VERSION "HNNBNNNYNNNNNNNNNNNNNNNNNNNNNNNNNNNNNNNNNN/4/%%%/4/'%**4NNN///"

NS_ :

BS_:

BU_: AWC BAP_Tester BMC_MLBevo BMS_MV BMS_NV CBC DCDC_800V_PAG DCDC_HV DCDC_HV_02 DCDC_IHEV FCU_MLBevo_FCEV Gateway Gateway_PAG Ladegeraet_2 Ladegeraet_Konzern LE1 LE2 LE_MLBevo Sub_Gateway TME

BO_ 2550034644 OBDC_SSN_CMC_04_Resp: 8 BMC_MLBevo
 SG_ OBDC_SSN_CMC_04_Resp_Data : 0|64@1+ (1.0,0.0) [0.0|18446744073709551615] ""  Gateway,Gateway_PAG

BO_ 2549903573 OBDC_SSN_CMC_05_Req: 8 Gateway
 SG_ OBDC_SSN_CMC_05_Req_Data : 0|64@1+ (1.0,0.0) [0.0|18446744073709551615] ""  BMC_MLBevo

BO_ 2550034645 OBDC_SSN_CMC_05_Resp: 8 BMC_MLBevo
 SG_ OBDC_SSN_CMC_05_Resp_Data : 0|64@1+ (1.0,0.0) [0.0|18446744073709551615] ""  Gateway,Gateway_PAG

BO_ 2549903574 OBDC_SSN_CMC_06_Req: 8 Gateway
 SG_ OBDC_SSN_CMC_06_Req_Data : 0|64@1+ (1.0,0.0) [0.0|18446744073709551615] ""  BMC_MLBevo

BO_ 2550034646 OBDC_SSN_CMC_06_Resp: 8 BMC_MLBevo
 SG_ OBDC_SSN_CMC_06_Resp_Data : 0|64@1+ (1.0,0.0) [0.0|18446744073709551615] ""  Gateway,Gateway_PAG

BO_ 2549903575 OBDC_SSN_CMC_07_Req: 8 Gateway
 SG_ OBDC_SSN_CMC_07_Req_Data : 0|64@1+ (1.0,0.0) [0.0|18446744073709551615] ""  BMC_MLBevo

BO_ 2550034647 OBDC_SSN_CMC_07_Resp: 8 BMC_MLBevo
 SG_ OBDC_SSN_CMC_07_Resp_Data : 0|64@1+ (1.0,0.0) [0.0|18446744073709551615] ""  Gateway,Gateway_PAG

BO_ 2549903576 OBDC_SSN_CMC_08_Req: 8 Gateway
 SG_ OBDC_SSN_CMC_08_Req_Data : 0|64@1+ (1.0,0.0) [0.0|18446744073709551615] ""  BMC_MLBevo

BO_ 2550034648 OBDC_SSN_CMC_08_Resp: 8 BMC_MLBevo
 SG_ OBDC_SSN_CMC_08_Resp_Data : 0|64@1+ (1.0,0.0) [0.0|18446744073709551615] ""  Gateway,Gateway_PAG

BO_ 2549903577 OBDC_SSN_CMC_09_Req: 8 Gateway
 SG_ OBDC_SSN_CMC_09_Req_Data : 0|64@1+ (1.0,0.0) [0.0|18446744073709551615] ""  BMC_MLBevo

BO_ 2550034649 OBDC_SSN_CMC_09_Resp: 8 BMC_MLBevo
 SG_ OBDC_SSN_CMC_09_Resp_Data : 0|64@1+ (1.0,0.0) [0.0|18446744073709551615] ""  Gateway,Gateway_PAG

BO_ 2549903578 OBDC_SSN_CMC_10_Req: 8 Gateway
 SG_ OBDC_SSN_CMC_10_Req_Data : 0|64@1+ (1.0,0.0) [0.0|18446744073709551615] ""  BMC_MLBevo

BO_ 2550034650 OBDC_SSN_CMC_10_Resp: 8 BMC_MLBevo
 SG_ OBDC_SSN_CMC_10_Resp_Data : 0|64@1+ (1.0,0.0) [0.0|18446744073709551615] ""  Gateway,Gateway_PAG

BO_ 2549903579 OBDC_SSN_CMC_11_Req: 8 Gateway
 SG_ OBDC_SSN_CMC_11_Req_Data : 0|64@1+ (1.0,0.0) [0.0|18446744073709551615] ""  BMC_MLBevo

BO_ 2550034651 OBDC_SSN_CMC_11_Resp: 8 BMC_MLBevo
 SG_ OBDC_SSN_CMC_11_Resp_Data : 0|64@1+ (1.0,0.0) [0.0|18446744073709551615] ""  Gateway,Gateway_PAG

BO_ 2549903580 OBDC_SSN_CMC_12_Req: 8 Gateway
 SG_ OBDC_SSN_CMC_12_Req_Data : 0|64@1+ (1.0,0.0) [0.0|18446744073709551615] ""  BMC_MLBevo

BO_ 2550034652 OBDC_SSN_CMC_12_Resp: 8 BMC_MLBevo
 SG_ OBDC_SSN_CMC_12_Resp_Data : 0|64@1+ (1.0,0.0) [0.0|18446744073709551615] ""  Gateway,Gateway_PAG

BO_ 2549903601 OBDC_SSN_CMC_13_Req: 8 Gateway
 SG_ OBDC_SSN_CMC_13_Req_Data : 0|64@1+ (1.0,0.0) [0.0|18446744073709551615] ""  BMC_MLBevo

BO_ 2550034673 OBDC_SSN_CMC_13_Resp: 8 BMC_MLBevo
 SG_ OBDC_SSN_CMC_13_Resp_Data : 0|64@1+ (1.0,0.0) [0.0|18446744073709551615] ""  Gateway,Gateway_PAG

BO_ 2549903602 OBDC_SSN_CMC_14_Req: 8 Gateway
 SG_ OBDC_SSN_CMC_14_Req_Data : 0|64@1+ (1.0,0.0) [0.0|18446744073709551615] ""  BMC_MLBevo

BO_ 2550034674 OBDC_SSN_CMC_14_Resp: 8 BMC_MLBevo
 SG_ OBDC_SSN_CMC_14_Resp_Data : 0|64@1+ (1.0,0.0) [0.0|18446744073709551615] ""  Gateway,Gateway_PAG

BO_ 2549903603 OBDC_SSN_CMC_15_Req: 8 Gateway
 SG_ OBDC_SSN_CMC_15_Req_Data : 0|64@1+ (1.0,0.0) [0.0|18446744073709551615] ""  BMC_MLBevo

BO_ 2550034675 OBDC_SSN_CMC_15_Resp: 8 BMC_MLBevo
 SG_ OBDC_SSN_CMC_15_Resp_Data : 0|64@1+ (1.0,0.0) [0.0|18446744073709551615] ""  Gateway,Gateway_PAG

BO_ 2549875380 OBDC_TelemetrieSG_Req: 8 Gateway
 SG_ OBDC_TelemetrieSG_Req_Data : 0|64@1+ (1.0,0.0) [0.0|18446744073709551615] ""  Sub_Gateway

BO_ 2550006452 OBDC_TelemetrieSG_Resp: 8 Sub_Gateway
 SG_ OBDC_TelemetrieSG_Resp_Data : 0|64@1+ (1.0,0.0) [0.0|18446744073709551615] ""  Gateway

BO_ 2549875266 OBDC_TME_Req: 8 Gateway
 SG_ OBDC_TME_Req_Data : 0|64@1+ (1.0,0.0) [0.0|18446744073709551615] ""  TME

BO_ 2550006338 OBDC_TME_Resp: 8 TME
 SG_ OBDC_TME_Resp_Data : 0|64@1+ (1.0,0.0) [0.0|18446744073709551615] ""  Gateway,Gateway_PAG

BO_ 2589283656 ORU_01: 8 Gateway
 SG_ ORU_Warnung : 58|2@1+ (1.0,0.0) [0.0|3] ""  Vector__XXX
 SG_ ORU_Status : 61|3@1+ (1.0,0.0) [0.0|7] ""  BMC_MLBevo,CBC,DCDC_800V_PAG,DCDC_HV,DCDC_HV_02,Ladegeraet_2,Ladegeraet_Konzern,TME

BO_ 872 Parkhilfe2_01: 8 Gateway
 SG_ PH2_Visualisierung : 0|3@1+ (1.0,0.0) [0.0|7] ""  Vector__XXX
 SG_ PDC2_Tonausgabe_Front : 4|4@1+ (1.0,0.0) [0.0|15] ""  Vector__XXX
 SG_ PDC2_Tonausgabe_Heck : 8|4@1+ (1.0,0.0) [0.0|15] ""  Vector__XXX
 SG_ PH2_nachtr_Stopp_An : 12|1@1+ (1.0,0.0) [0.0|1] ""  Vector__XXX
 SG_ PH2_Abschaltursache : 13|3@1+ (1.0,0.0) [0.0|7] ""  Vector__XXX
 SG_ PH2_Opt_Anzeige_V_ein : 16|1@1+ (1.0,0.0) [0.0|1] ""  Vector__XXX
 SG_ PH2_Opt_Anzeige_H_ein : 17|1@1+ (1.0,0.0) [0.0|1] ""  Vector__XXX
 SG_ PH2_Opt_Anz_V_Hindernis : 18|1@1+ (1.0,0.0) [0.0|1] ""  Vector__XXX
 SG_ PH2_Opt_Anz_H_Hindernis : 19|1@1+ (1.0,0.0) [0.0|1] ""  Vector__XXX
 SG_ PH2_Tongeber_V_aktiv : 20|1@1+ (1.0,0.0) [0.0|1] ""  Vector__XXX
 SG_ PH2_Tongeber_H_aktiv : 21|1@1+ (1.0,0.0) [0.0|1] ""  Vector__XXX
 SG_ PH2_Tongeber_mute : 22|1@1+ (1.0,0.0) [0.0|1] ""  Vector__XXX
 SG_ PH2_Anf_Audioabsenkung : 23|1@1+ (1.0,0.0) [0.0|1] ""  Vector__XXX
 SG_ PH2_Tongeber_H_verfuegbar : 24|1@1+ (1.0,0.0) [0.0|1] ""  Vector__XXX
 SG_ PH2_Taster : 28|2@1+ (1.0,0.0) [0.0|3] ""  Vector__XXX
 SG_ PH2_Anf_Verdeck : 30|2@1+ (1.0,0.0) [0.0|3] ""  Vector__XXX
 SG_ PH2_Frequenz_hinten : 32|4@1+ (1,0) [0|15] ""  Vector__XXX
 SG_ PH2_Lautstaerke_hinten : 36|4@1+ (1,0) [0|15] ""  Vector__XXX
 SG_ PH2_Frequenz_vorn : 40|4@1+ (1,0) [0|15] ""  Vector__XXX
 SG_ PH2_Lautstaerke_vorn : 44|4@1+ (1,0) [0|15] ""  Vector__XXX
 SG_ PH2_StartStopp_Info : 49|2@1+ (1.0,0.0) [0.0|3] ""  Vector__XXX
 SG_ PH2_Stoermeldung : 52|4@1+ (1.0,0.0) [0.0|15] ""  Vector__XXX
 SG_ PH2_defekt : 56|1@1+ (1.0,0.0) [0.0|1] ""  Vector__XXX
 SG_ PH2_gestoert : 57|1@1+ (1.0,0.0) [0.0|1] ""  Vector__XXX
 SG_ PH2_Systemzustand : 58|3@1+ (1.0,0.0) [0.0|7] ""  Vector__XXX
 SG_ PH2_Display_Kundenwunsch : 61|2@1+ (1.0,0.0) [0.0|3] ""  Vector__XXX

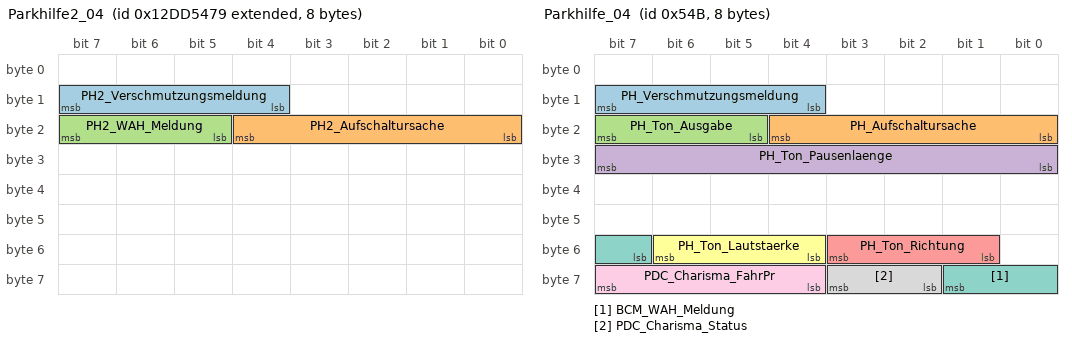
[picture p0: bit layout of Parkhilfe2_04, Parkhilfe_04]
BO_ 2463978617 Parkhilfe2_04: 8 Gateway
 SG_ PH2_Verschmutzungsmeldung : 12|4@1+ (1.0,0.0) [0.0|15] ""  Vector__XXX
 SG_ PH2_Aufschaltursache : 16|5@1+ (1.0,0.0) [0.0|31] ""  Vector__XXX
 SG_ PH2_WAH_Meldung : 21|3@1+ (1.0,0.0) [0.0|7] ""  Vector__XXX

BO_ 1175 Parkhilfe_01: 8 Gateway
 SG_ PH_Visualisierung : 0|3@1+ (1.0,0.0) [0.0|7] ""  Vector__XXX
 SG_ PDC_Tonausgabe_Front : 4|4@1+ (1.0,0.0) [0.0|15] ""  Vector__XXX
 SG_ PDC_Tonausgabe_Heck : 8|4@1+ (1.0,0.0) [0.0|15] ""  Vector__XXX
 SG_ PH_nachtr_Stopp_Anf : 12|1@1+ (1.0,0.0) [0.0|1] ""  Vector__XXX
 SG_ PH_Abschaltursache : 13|3@1+ (1.0,0.0) [0.0|7] ""  Vector__XXX
 SG_ PH_Opt_Anzeige_V_ein : 16|1@1+ (1.0,0.0) [0.0|1] ""  Vector__XXX
 SG_ PH_Opt_Anzeige_H_ein : 17|1@1+ (1.0,0.0) [0.0|1] ""  Vector__XXX
 SG_ PH_Opt_Anz_V_Hindernis : 18|1@1+ (1.0,0.0) [0.0|1] ""  Vector__XXX
 SG_ PH_Opt_Anz_H_Hindernis : 19|1@1+ (1.0,0.0) [0.0|1] ""  Vector__XXX
 SG_ PH_Tongeber_V_aktiv : 20|1@1+ (1.0,0.0) [0.0|1] ""  Vector__XXX
 SG_ PH_Tongeber_H_aktiv : 21|1@1+ (1.0,0.0) [0.0|1] ""  Vector__XXX
 SG_ PH_Tongeber_mute : 22|1@1+ (1.0,0.0) [0.0|1] ""  Vector__XXX
 SG_ PH_Anf_Audioabsenkung : 23|1@1+ (1.0,0.0) [0.0|1] ""  Vector__XXX
 SG_ PH_Tongeber_H_verfuegbar : 24|1@1+ (1.0,0.0) [0.0|1] ""  Vector__XXX
 SG_ PLA_Anf_Aufschaltung_RVC : 25|1@1+ (1.0,0.0) [0.0|1] ""  Vector__XXX
 SG_ PH_Taster : 28|2@1+ (1.0,0.0) [0.0|3] ""  Vector__XXX
 SG_ PH_Anf_Verdeck : 30|2@1+ (1.0,0.0) [0.0|3] ""  Vector__XXX
 SG_ PH_Frequenz_hinten : 32|4@1+ (1,0) [0|15] ""  Vector__XXX
 SG_ PH_Lautstaerke_hinten : 36|4@1+ (1,0) [0|15] ""  Vector__XXX
 SG_ PH_Frequenz_vorn : 40|4@1+ (1,0) [0|15] ""  Vector__XXX
 SG_ PH_Lautstaerke_vorn : 44|4@1+ (1,0) [0|15] ""  Vector__XXX
 SG_ PH_StartStopp_Info : 49|2@1+ (1.0,0.0) [0.0|3] ""  Vector__XXX
 SG_ PH_Stoermeldung : 52|4@1+ (1.0,0.0) [0.0|15] ""  Vector__XXX
 SG_ PH_defekt : 56|1@1+ (1.0,0.0) [0.0|1] ""  Vector__XXX
 SG_ PH_gestoert : 57|1@1+ (1.0,0.0) [0.0|1] ""  Vector__XXX
 SG_ PH_Systemzustand : 58|3@1+ (1.0,0.0) [0.0|7] ""  Vector__XXX
 SG_ PH_Display_Kundenwunsch : 61|2@1+ (1.0,0.0) [0.0|3] ""  Vector__XXX

BO_ 1355 Parkhilfe_04: 8 Gateway
 SG_ PH_Verschmutzungsmeldung : 12|4@1+ (1.0,0.0) [0.0|15] ""  Vector__XXX
 SG_ PH_Aufschaltursache : 16|5@1+ (1.0,0.0) [0.0|31] ""  Vector__XXX
 SG_ PH_Ton_Ausgabe : 21|3@1+ (1.0,0.0) [0.0|7] ""  Vector__XXX
 SG_ PH_Ton_Pausenlaenge : 24|8@1+ (1.0,0.0) [0.0|255] ""  Vector__XXX
 SG_ PH_Ton_Richtung : 49|3@1+ (1.0,0.0) [0.0|7] ""  Vector__XXX
 SG_ PH_Ton_Lautstaerke : 52|3@1+ (1.0,0.0) [0.0|7] ""  Vector__XXX
 SG_ BCM_WAH_Meldung : 55|3@1+ (1.0,0.0) [0.0|7] ""  Vector__XXX
 SG_ PDC_Charisma_Status : 58|2@1+ (1.0,0.0) [0.0|3] ""  Vector__XXX
 SG_ PDC_Charisma_FahrPr : 60|4@1+ (1.0,0.0) [0.0|15] ""  Vector__XXX

BO_ 617 PIF_01: 8 Gateway
 SG_ PIF_Toggle : 0|1@1+ (1.0,0.0) [0.0|1] ""  TME
 SG_ PIF_ST_Status : 1|2@1+ (1.0,0.0) [0.0|3] ""  TME
 SG_ PIF_MT_Status : 3|2@1+ (1.0,0.0) [0.0|3] ""  TME
 SG_ PIF_LT_Status : 5|2@1+ (1.0,0.0) [0.0|3] ""  TME
 SG_ PIF_Identifier : 7|3@1+ (1.0,0.0) [0.0|7] ""  TME
 SG_ PIF_ST_Bin_0 : 10|2@1+ (1.0,0.0) [0.0|3] ""  TME
 SG_ PIF_ST_Bin_1 : 12|2@1+ (1.0,0.0) [0.0|3] ""  TME
 SG_ PIF_ST_Bin_2 : 14|2@1+ (1.0,0.0) [0.0|3] ""  TME
 SG_ PIF_ST_Bin_3 : 16|2@1+ (1.0,0.0) [0.0|3] ""  TME
 SG_ PIF_ST_Bin_4 : 18|2@1+ (1.0,0.0) [0.0|3] ""  TME
 SG_ PIF_ST_Bin_5 : 20|2@1+ (1.0,0.0) [0.0|3] ""  TME
 SG_ PIF_ST_Bin_6 : 22|2@1+ (1.0,0.0) [0.0|3] ""  TME
 SG_ PIF_ST_Bin_7 : 24|2@1+ (1.0,0.0) [0.0|3] ""  TME
 SG_ PIF_ST_Bin_8 : 26|2@1+ (1.0,0.0) [0.0|3] ""  TME
 SG_ PIF_MT_Bin_0 : 28|2@1+ (1.0,0.0) [0.0|3] ""  TME
 SG_ PIF_MT_Bin_1 : 30|2@1+ (1.0,0.0) [0.0|3] ""  TME
 SG_ PIF_MT_Bin_2 : 32|2@1+ (1.0,0.0) [0.0|3] ""  TME
 SG_ PIF_MT_Bin_3 : 34|2@1+ (1.0,0.0) [0.0|3] ""  TME
 SG_ PIF_MT_Bin_4 : 36|2@1+ (1.0,0.0) [0.0|3] ""  TME
 SG_ PIF_MT_Bin_5 : 38|2@1+ (1.0,0.0) [0.0|3] ""  TME
 SG_ PIF_MT_Bin_6 : 40|2@1+ (1.0,0.0) [0.0|3] ""  TME
 SG_ PIF_MT_Bin_7 : 42|2@1+ (1.0,0.0) [0.0|3] ""  TME
 SG_ PIF_MT_Bin_8 : 44|2@1+ (1.0,0.0) [0.0|3] ""  TME
 SG_ PIF_LT_Bin_0 : 46|2@1+ (1.0,0.0) [0.0|3] ""  TME
 SG_ PIF_LT_Bin_1 : 48|2@1+ (1.0,0.0) [0.0|3] ""  TME
 SG_ PIF_LT_Bin_2 : 50|2@1+ (1.0,0.0) [0.0|3] ""  TME
 SG_ PIF_LT_Bin_3 : 52|2@1+ (1.0,0.0) [0.0|3] ""  TME
 SG_ PIF_LT_Bin_4 : 54|2@1+ (1.0,0.0) [0.0|3] ""  TME
 SG_ PIF_LT_Bin_5 : 56|2@1+ (1.0,0.0) [0.0|3] ""  TME
 SG_ PIF_LT_Bin_6 : 58|2@1+ (1.0,0.0) [0.0|3] ""  TME
 SG_ PIF_LT_Bin_7 : 60|2@1+ (1.0,0.0) [0.0|3] ""  TME
 SG_ PIF_LT_Bin_8 : 62|2@1+ (1.0,0.0) [0.0|3] ""  TME

BO_ 2549876804 PnC_Ladegeraet_Req: 8 Ladegeraet_Konzern
 SG_ PnC_Ladegeraet_Req_Data : 0|64@1+ (1,0) [0|18446744073709551615] "Unit_None"  Gateway,Gateway_PAG

BO_ 2550007876 PnC_Ladegeraet_Resp: 8 Gateway
 SG_ PnC_Ladegeraet_Resp_Data : 0|64@1+ (1,0) [0|18446744073709551615] "Unit_None"  Ladegeraet_Konzern

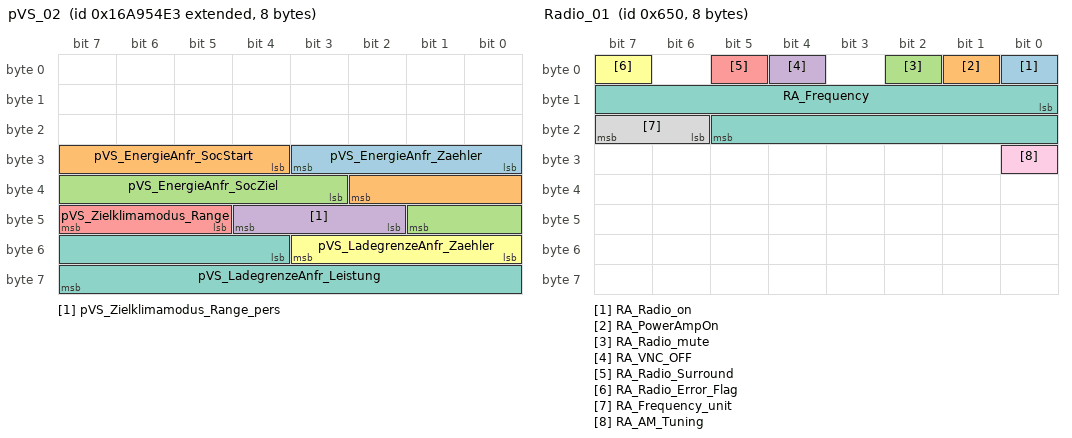
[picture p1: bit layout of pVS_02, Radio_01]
BO_ 2527679715 pVS_02: 8 Gateway_PAG
 SG_ pVS_EnergieAnfr_Zaehler : 24|4@1+ (1,0) [0|13] "Unit_None"  BMC_MLBevo
 SG_ pVS_EnergieAnfr_SocStart : 28|7@1+ (1,0) [0|100] "Unit_PerCent"  BMC_MLBevo
 SG_ pVS_EnergieAnfr_SocZiel : 35|7@1+ (1,0) [0|100] "Unit_PerCent"  BMC_MLBevo
 SG_ pVS_Zielklimamodus_Range_pers : 42|3@1+ (1.0,0.0) [0.0|7] ""  Vector__XXX
 SG_ pVS_Zielklimamodus_Range : 45|3@1+ (1.0,0.0) [0.0|7] ""  Vector__XXX
 SG_ pVS_LadegrenzeAnfr_Zaehler : 48|4@1+ (1,0) [0|13] "Unit_None"  BMC_MLBevo
 SG_ pVS_LadegrenzeAnfr_Leistung : 52|12@1+ (200,0) [0|818600] "Unit_Watt"  BMC_MLBevo

BO_ 1616 Radio_01: 8 Gateway
 SG_ RA_Radio_on : 0|1@1+ (1,0) [0|1] ""  DCDC_800V_PAG,DCDC_IHEV
 SG_ RA_PowerAmpOn : 1|1@1+ (1,0) [0|1] ""  Vector__XXX
 SG_ RA_Radio_mute : 2|1@1+ (1,0) [0|1] ""  Vector__XXX
 SG_ RA_VNC_OFF : 4|1@1+ (1,0) [0|1] ""  Vector__XXX
 SG_ RA_Radio_Surround : 5|1@1+ (1,0) [0|1] ""  Vector__XXX
 SG_ RA_Radio_Error_Flag : 7|1@1+ (1.0,0.0) [0.0|1] ""  Vector__XXX
 SG_ RA_Frequency : 8|14@1+ (1,0) [0|16383] "Unit_None"  DCDC_800V_PAG,DCDC_IHEV
 SG_ RA_Frequency_unit : 22|2@1+ (1.0,0.0) [0.0|3] ""  DCDC_800V_PAG,DCDC_IHEV
 SG_ RA_AM_Tuning : 24|1@1+ (1.0,0.0) [0.0|1] ""  DCDC_800V_PAG,DCDC_IHEV

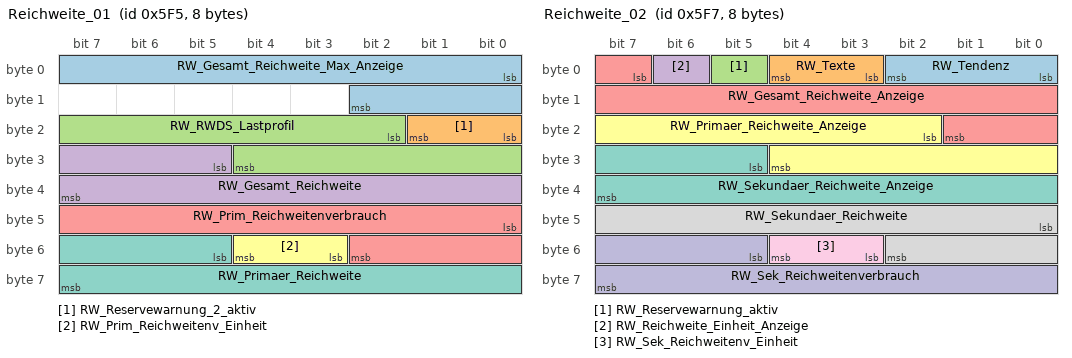
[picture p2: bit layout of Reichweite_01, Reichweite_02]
BO_ 1525 Reichweite_01: 8 Gateway
 SG_ RW_Gesamt_Reichweite_Max_Anzeige : 0|11@1+ (1,0) [0|2044] "Unit_None"  Sub_Gateway
 SG_ RW_Reservewarnung_2_aktiv : 16|2@1+ (1.0,0.0) [0.0|3] ""  Sub_Gateway,TME
 SG_ RW_RWDS_Lastprofil : 18|11@1+ (1,0) [0|2045] "Unit_Amper"  BMC_MLBevo,Sub_Gateway
 SG_ RW_Gesamt_Reichweite : 29|11@1+ (1,0) [0|2044] "Unit_KiloMeter"  Ladegeraet_Konzern,Sub_Gateway
 SG_ RW_Prim_Reichweitenverbrauch : 40|11@1+ (0.1,0) [0.0|204.4] "Unit_None"  Ladegeraet_Konzern,Sub_Gateway
 SG_ RW_Prim_Reichweitenv_Einheit : 51|2@1+ (1.0,0.0) [0.0|3] ""  Sub_Gateway
 SG_ RW_Primaer_Reichweite : 53|11@1+ (1,0) [0|2044] "Unit_KiloMeter"  Ladegeraet_Konzern,Sub_Gateway

BO_ 1527 Reichweite_02: 8 Gateway
 SG_ RW_Tendenz : 0|3@1+ (1.0,0.0) [0.0|7] ""  Sub_Gateway
 SG_ RW_Texte : 3|2@1+ (1.0,0.0) [0.0|3] ""  Sub_Gateway
 SG_ RW_Reservewarnung_aktiv : 5|1@1+ (1.0,0.0) [0.0|1] ""  Sub_Gateway,TME
 SG_ RW_Reichweite_Einheit_Anzeige : 6|1@1+ (1.0,0.0) [0.0|1] ""  Sub_Gateway
 SG_ RW_Gesamt_Reichweite_Anzeige : 7|11@1+ (1,0) [0|2044] "Unit_None"  Sub_Gateway
 SG_ RW_Primaer_Reichweite_Anzeige : 18|11@1+ (1,0) [0|2044] "Unit_None"  Ladegeraet_Konzern,Sub_Gateway
 SG_ RW_Sekundaer_Reichweite_Anzeige : 29|11@1+ (1,0) [0|2044] "Unit_None"  Sub_Gateway
 SG_ RW_Sekundaer_Reichweite : 40|11@1+ (1,0) [0|2044] "Unit_KiloMeter"  Ladegeraet_Konzern,Sub_Gateway
 SG_ RW_Sek_Reichweitenv_Einheit : 51|2@1+ (1.0,0.0) [0.0|3] ""  Sub_Gateway
 SG_ RW_Sek_Reichweitenverbrauch : 53|11@1+ (0.1,0) [0.0|204.4] "Unit_None"  Sub_Gateway

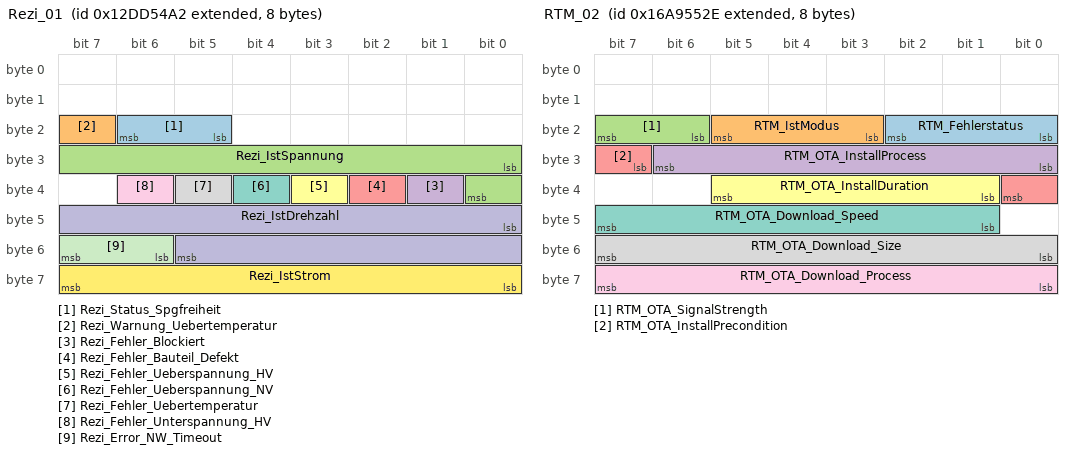
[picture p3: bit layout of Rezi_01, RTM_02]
BO_ 2463978658 Rezi_01: 8 FCU_MLBevo_FCEV
 SG_ Rezi_Status_Spgfreiheit : 21|2@1+ (1.0,0.0) [0.0|3] ""  Gateway
 SG_ Rezi_Warnung_Uebertemperatur : 23|1@1+ (1.0,0.0) [0.0|1] ""  Vector__XXX
 SG_ Rezi_IstSpannung : 24|9@1+ (2,0) [0|1020] "Unit_Volt"  Gateway
 SG_ Rezi_Fehler_Blockiert : 33|1@1+ (1.0,0.0) [0.0|1] ""  Vector__XXX
 SG_ Rezi_Fehler_Bauteil_Defekt : 34|1@1+ (1.0,0.0) [0.0|1] ""  Vector__XXX
 SG_ Rezi_Fehler_Ueberspannung_HV : 35|1@1+ (1.0,0.0) [0.0|1] ""  Vector__XXX
 SG_ Rezi_Fehler_Ueberspannung_NV : 36|1@1+ (1.0,0.0) [0.0|1] ""  Vector__XXX
 SG_ Rezi_Fehler_Uebertemperatur : 37|1@1+ (1.0,0.0) [0.0|1] ""  Vector__XXX
 SG_ Rezi_Fehler_Unterspannung_HV : 38|1@1+ (1.0,0.0) [0.0|1] ""  Vector__XXX
 SG_ Rezi_IstDrehzahl : 40|14@1+ (2,0) [0|32764] "Unit_RevPerMinute"  Vector__XXX
 SG_ Rezi_Error_NW_Timeout : 54|2@1+ (1.0,0.0) [0.0|3] ""  Vector__XXX
 SG_ Rezi_IstStrom : 56|8@1+ (0.1,0) [0.0|25.4] "Unit_Amper"  Vector__XXX

BO_ 1126 RTM_01: 8 Gateway
 SG_ RTM_Warnstatus : 62|2@1+ (1.0,0.0) [0.0|3] ""  Sub_Gateway

BO_ 2527679790 RTM_02: 8 Sub_Gateway
 SG_ RTM_Fehlerstatus : 16|3@1+ (1.0,0.0) [0.0|7] ""  Gateway,Gateway_PAG
 SG_ RTM_IstModus : 19|3@1+ (1.0,0.0) [0.0|7] ""  Gateway,Gateway_PAG
 SG_ RTM_OTA_SignalStrength : 22|2@1+ (1.0,0.0) [0.0|3] ""  Gateway,Gateway_PAG
 SG_ RTM_OTA_InstallProcess : 24|7@1+ (1,-1) [0|100] "Unit_PerCent"  Gateway,Gateway_PAG
 SG_ RTM_OTA_InstallPrecondition : 31|2@1+ (1.0,0.0) [0.0|3] ""  Gateway,Gateway_PAG
 SG_ RTM_OTA_InstallDuration : 33|5@1+ (1,0) [1|30] "Unit_Minut"  Gateway,Gateway_PAG
 SG_ RTM_OTA_Download_Speed : 41|7@1+ (0.1,0) [0.1|12.5] ""  Gateway,Gateway_PAG
 SG_ RTM_OTA_Download_Size : 48|8@1+ (1,1) [1|253] ""  Gateway,Gateway_PAG
 SG_ RTM_OTA_Download_Process : 56|8@1+ (0.5,0) [0.0|100.0] "Unit_PerCent"  Gateway,Gateway_PAG

BO_ 2527679791 RTM_03: 8 Sub_Gateway
 SG_ RTM_03_Dummy : 63|1@1+ (1.0,0.0) [0.0|1] ""  Gateway,Gateway_PAG

BO_ 2527679792 RTM_04: 8 Gateway
 SG_ MIB_OTA_Comfirmation : 12|3@1+ (1.0,0.0) [0.0|7] ""  Sub_Gateway

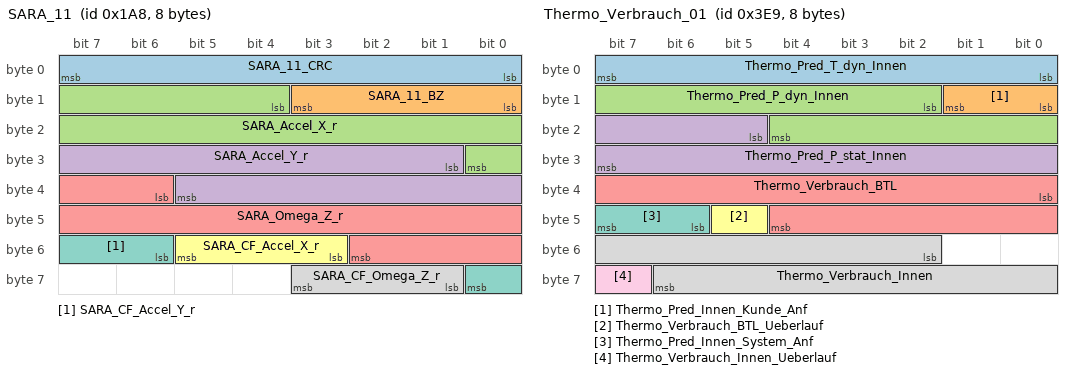
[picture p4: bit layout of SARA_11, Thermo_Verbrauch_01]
BO_ 424 SARA_11: 8 Gateway
 SG_ SARA_11_CRC : 0|8@1+ (1,0) [0|255] ""  Vector__XXX
 SG_ SARA_11_BZ : 8|4@1+ (1,0) [0|15] ""  Vector__XXX
 SG_ SARA_Accel_X_r : 12|13@1+ (0.16,-655.36) [-655.20|655.04] "Unit_MeterPerSeconSquar"  FCU_MLBevo_FCEV
 SG_ SARA_Accel_Y_r : 25|13@1+ (0.16,-655.36) [-655.20|655.04] "Unit_MeterPerSeconSquar"  FCU_MLBevo_FCEV
 SG_ SARA_Omega_Z_r : 38|13@1+ (0.08,-327.68) [-327.60|327.52] "Unit_DegreOfArcPerSecon"  Vector__XXX
 SG_ SARA_CF_Accel_X_r : 51|3@1+ (1.0,0.0) [0.0|7] ""  FCU_MLBevo_FCEV
 SG_ SARA_CF_Accel_Y_r : 54|3@1+ (1.0,0.0) [0.0|7] ""  FCU_MLBevo_FCEV
 SG_ SARA_CF_Omega_Z_r : 57|3@1+ (1.0,0.0) [0.0|7] ""  Vector__XXX

BO_ 1313 STH_01: 8 Gateway
 SG_ STH_Funk_ein : 0|1@1+ (1.0,0.0) [0.0|1] ""  Ladegeraet_Konzern
 SG_ STH_Funk_aus : 1|1@1+ (1.0,0.0) [0.0|1] ""  Ladegeraet_Konzern
 SG_ STH_Zusatzheizung : 2|1@1+ (1.0,0.0) [0.0|1] ""  TME
 SG_ STH_LED : 3|1@1+ (1.0,0.0) [0.0|1] ""  TME
 SG_ STH_Pumpe_ein : 4|1@1+ (1,0) [0|1] ""  TME
 SG_ STH_Geblaese : 5|1@1+ (1.0,0.0) [0.0|1] ""  TME
 SG_ STH_EKP_Anst : 6|1@1+ (1.0,0.0) [0.0|1] ""  Vector__XXX
 SG_ STH_Start_folgt : 7|1@1+ (1.0,0.0) [0.0|1] ""  Vector__XXX
 SG_ STH_Ventiloeffnungszeit : 8|6@1+ (1,0) [0|63] "Unit_Minut"  Vector__XXX
 SG_ STH_Ventil_Status : 14|1@1+ (1.0,0.0) [0.0|1] ""  TME
 SG_ STH_Fehler_ElWaPu : 15|1@1+ (1.0,0.0) [0.0|1] ""  TME
 SG_ STH_Waermeeintrag : 16|6@1+ (1,0) [0|63] "Unit_None"  Vector__XXX
 SG_ STH_Pumpen_Anf_extern : 22|1@1+ (1.0,0.0) [0.0|1] ""  Vector__XXX
 SG_ STH_KL_HUP : 23|1@1+ (1.0,0.0) [0.0|1] ""  Vector__XXX
 SG_ STH_KVS : 24|13@1+ (1,0) [0|8191] "Unit_MilliLiter"  Vector__XXX
 SG_ STH_Fehlerstatus : 37|3@1+ (1.0,0.0) [0.0|7] ""  TME
 SG_ STH_Heizleistung : 40|8@1+ (1,0) [0|255] ""  Vector__XXX
 SG_ STH_Wassertemp : 48|8@1+ (0.75,-40) [-40.00|142.25] "Unit_DegreCelsi"  TME
 SG_ STH_Texte : 56|3@1+ (1.0,0.0) [0.0|7] ""  TME
 SG_ STH_Motorvorwaermung : 59|1@1+ (1.0,0.0) [0.0|1] ""  Vector__XXX
 SG_ STH_Servicemode : 60|1@1+ (1.0,0.0) [0.0|1] ""  Vector__XXX
 SG_ STH_war_aktiv : 61|1@1+ (1.0,0.0) [0.0|1] ""  Vector__XXX
 SG_ STH_KVS_Ueberlauf : 62|1@1+ (1.0,0.0) [0.0|1] ""  Vector__XXX
 SG_ STH_SH_ZH : 63|1@1+ (1.0,0.0) [0.0|1] ""  Vector__XXX

BO_ 505 STP_03: 8 Gateway
 SG_ STP_03_CRC : 0|8@1+ (1,0) [0|255] ""  Vector__XXX
 SG_ STP_03_BZ : 8|4@1+ (1,0) [0|15] ""  Vector__XXX
 SG_ STP_Slave_Status : 12|4@1+ (1.0,0.0) [0.0|15] ""  Vector__XXX
 SG_ FZE_STP_Abschaltbedingung : 16|3@1+ (1.0,0.0) [0.0|7] ""  Vector__XXX
 SG_ ACA_HF_Grund_AV_AB : 19|3@1+ (1.0,0.0) [0.0|7] ""  Vector__XXX
 SG_ FZE_STP_Status : 22|2@1+ (1.0,0.0) [0.0|3] ""  Vector__XXX
 SG_ STP_Notlaufaktivierung : 25|1@1+ (1.0,0.0) [0.0|1] ""  Vector__XXX
 SG_ STP_Funktion_freigegeben : 26|1@1+ (1.0,0.0) [0.0|1] ""  TME
 SG_ ACA_QF_Status_Anzeige : 27|4@1+ (1.0,0.0) [0.0|15] ""  Vector__XXX
 SG_ ACF_SwuFahrerUnaufmerksam : 31|1@1+ (1.0,0.0) [0.0|1] ""  Vector__XXX
 SG_ ACA_QF_Fahreruebernahme : 32|2@1+ (1.0,0.0) [0.0|3] ""  Vector__XXX
 SG_ ACA_HF_Status : 34|4@1+ (1.0,0.0) [0.0|15] ""  Vector__XXX
 SG_ FZE_Spurwechsel_erkannt_li : 40|1@1+ (1.0,0.0) [0.0|1] ""  Vector__XXX
 SG_ FZE_Spurwechsel_erkannt_re : 41|1@1+ (1.0,0.0) [0.0|1] ""  Vector__XXX
 SG_ ACF_Spurwechsel_moeglich : 42|1@1+ (1.0,0.0) [0.0|1] ""  Vector__XXX
 SG_ ACF_Spurwechsel_wahrscheinlich : 43|1@1+ (1.0,0.0) [0.0|1] ""  Vector__XXX
 SG_ FZE_STP_Aktivierverhinderung : 44|2@1+ (1.0,0.0) [0.0|3] ""  Vector__XXX

BO_ 1413 Systeminfo_01: 8 Gateway
 SG_ SI_Sammel_SG_Fehler : 0|6@1+ (1,0) [0|60] ""  FCU_MLBevo_FCEV,Sub_Gateway
 SG_ SI_Diagnose_Aktiv : 7|1@1+ (1.0,0.0) [0.0|1] ""  FCU_MLBevo_FCEV,Sub_Gateway
 SG_ SI_QRS_Mode : 8|1@1+ (1.0,0.0) [0.0|1] ""  FCU_MLBevo_FCEV,Sub_Gateway,TME
 SG_ SI_T_Mode : 9|1@1+ (1.0,0.0) [0.0|1] ""  FCU_MLBevo_FCEV,Sub_Gateway,TME
 SG_ SI_NWDF : 10|1@1+ (1.0,0.0) [0.0|1] ""  BMS_MV,BMS_NV,CBC,DCDC_800V_PAG,DCDC_HV,DCDC_HV_02,DCDC_IHEV,FCU_MLBevo_FCEV,Ladegeraet_2,Ladegeraet_Konzern,Sub_Gateway
 SG_ SI_NWDF_gueltig : 11|1@1+ (1.0,0.0) [0.0|1] ""  BMS_MV,BMS_NV,CBC,DCDC_800V_PAG,DCDC_HV,DCDC_HV_02,DCDC_IHEV,FCU_MLBevo_FCEV,Ladegeraet_2,Ladegeraet_Konzern,Sub_Gateway
 SG_ SI_Sammelfehler : 12|1@1+ (1.0,0.0) [0.0|1] ""  FCU_MLBevo_FCEV,Sub_Gateway
 SG_ GW_KD_Fehler : 13|1@1+ (1.0,0.0) [0.0|1] ""  FCU_MLBevo_FCEV,Sub_Gateway
 SG_ SI_T_Schutz : 14|1@1+ (1.0,0.0) [0.0|1] ""  FCU_MLBevo_FCEV,Sub_Gateway
 SG_ SI_BUS_01 : 16|1@1+ (1.0,0.0) [0.0|1] ""  BMC_MLBevo,BMS_MV,CBC,DCDC_HV_02,FCU_MLBevo_FCEV,Sub_Gateway,TME
 SG_ SI_BUS_02 : 17|1@1+ (1.0,0.0) [0.0|1] ""  FCU_MLBevo_FCEV,Sub_Gateway
 SG_ SI_BUS_03 : 18|1@1+ (1.0,0.0) [0.0|1] ""  BMC_MLBevo,BMS_MV,BMS_NV,CBC,DCDC_800V_PAG,DCDC_HV,DCDC_HV_02,DCDC_IHEV,FCU_MLBevo_FCEV,Ladegeraet_2,Ladegeraet_Konzern,LE_MLBevo,Sub_Gateway,TME
 SG_ SI_BUS_04 : 19|1@1+ (1.0,0.0) [0.0|1] ""  BMC_MLBevo,BMS_MV,BMS_NV,CBC,DCDC_HV_02,FCU_MLBevo_FCEV,Ladegeraet_2,Ladegeraet_Konzern,Sub_Gateway,TME
 SG_ SI_BUS_05 : 20|1@1+ (1.0,0.0) [0.0|1] ""  FCU_MLBevo_FCEV,Sub_Gateway
 SG_ SI_BUS_06 : 21|1@1+ (1.0,0.0) [0.0|1] ""  FCU_MLBevo_FCEV,Ladegeraet_2,Ladegeraet_Konzern,Sub_Gateway,TME
 SG_ SI_BUS_07 : 22|1@1+ (1.0,0.0) [0.0|1] ""  FCU_MLBevo_FCEV,Sub_Gateway
 SG_ SI_BUS_08 : 23|1@1+ (1.0,0.0) [0.0|1] ""  FCU_MLBevo_FCEV,Sub_Gateway
 SG_ SI_BUS_09 : 24|1@1+ (1.0,0.0) [0.0|1] ""  FCU_MLBevo_FCEV,Sub_Gateway
 SG_ SI_BUS_10 : 25|1@1+ (1.0,0.0) [0.0|1] ""  BMC_MLBevo,BMS_MV,BMS_NV,CBC,DCDC_800V_PAG,DCDC_HV,DCDC_HV_02,DCDC_IHEV,FCU_MLBevo_FCEV,Ladegeraet_2,Ladegeraet_Konzern,LE_MLBevo,Sub_Gateway,TME
 SG_ SI_BUS_11 : 26|1@1+ (1.0,0.0) [0.0|1] ""  FCU_MLBevo_FCEV,Sub_Gateway
 SG_ SI_BUS_12 : 27|1@1+ (1.0,0.0) [0.0|1] ""  BMC_MLBevo,BMS_NV,CBC,DCDC_HV_02,FCU_MLBevo_FCEV,Ladegeraet_Konzern,Sub_Gateway,TME
 SG_ SI_BUS_13 : 28|1@1+ (1.0,0.0) [0.0|1] ""  BMS_NV,FCU_MLBevo_FCEV,Ladegeraet_Konzern,Sub_Gateway,TME
 SG_ SI_BUS_14 : 29|1@1+ (1.0,0.0) [0.0|1] ""  FCU_MLBevo_FCEV,Sub_Gateway
 SG_ SI_BUS_15 : 30|1@1+ (1.0,0.0) [0.0|1] ""  FCU_MLBevo_FCEV,Sub_Gateway
 SG_ SI_Bus_Identifikation : 32|8@1+ (1.0,0.0) [0.0|255] ""  FCU_MLBevo_FCEV,Sub_Gateway
 SG_ SI_CAB : 40|24@1+ (1.0,0.0) [0.0|16777215] ""  FCU_MLBevo_FCEV,Sub_Gateway

BO_ 1001 Thermo_Verbrauch_01: 8 TME
 SG_ Thermo_Pred_T_dyn_Innen : 0|8@1+ (1,0) [0|253] "Unit_Minut"  Gateway,Gateway_PAG
 SG_ Thermo_Pred_Innen_Kunde_Anf : 8|2@1+ (1,0) [0|3] "Unit_None"  Gateway,Gateway_PAG
 SG_ Thermo_Pred_P_dyn_Innen : 10|11@1+ (10,0) [0|20450] "Unit_Watt"  Gateway,Gateway_PAG
 SG_ Thermo_Pred_P_stat_Innen : 21|11@1+ (10,0) [0|20450] "Unit_Watt"  Gateway,Gateway_PAG
 SG_ Thermo_Verbrauch_BTL : 32|13@1+ (1,0) [0|8191] "Unit_WattSecond"  Gateway,Gateway_PAG
 SG_ Thermo_Verbrauch_BTL_Ueberlauf : 45|1@1+ (1.0,0.0) [0.0|1] ""  Gateway,Gateway_PAG
 SG_ Thermo_Pred_Innen_System_Anf : 46|2@1+ (1,0) [0|3] "Unit_None"  Gateway,Gateway_PAG
 SG_ Thermo_Verbrauch_Innen : 50|13@1+ (1,0) [0|8191] "Unit_WattSecond"  Gateway,Gateway_PAG
 SG_ Thermo_Verbrauch_Innen_Ueberlauf : 63|1@1+ (1.0,0.0) [0.0|1] ""  Gateway,Gateway_PAG

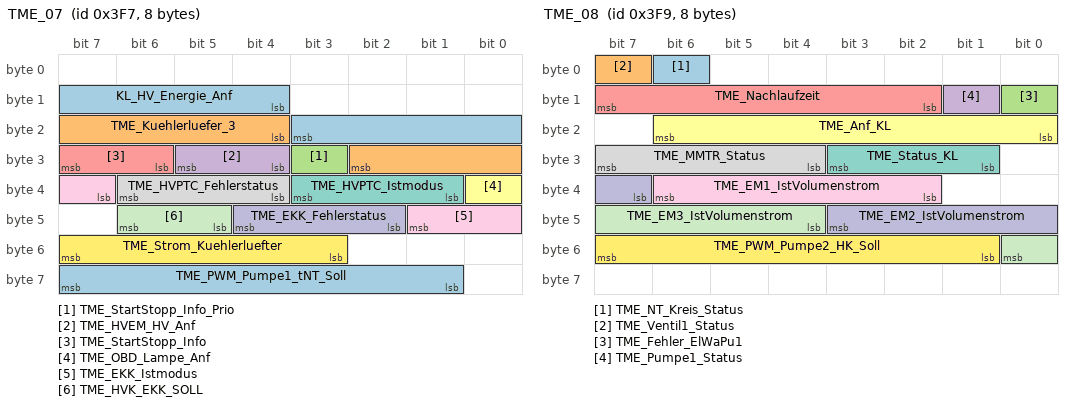
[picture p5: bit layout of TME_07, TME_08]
BO_ 1015 TME_07: 8 TME
 SG_ KL_HV_Energie_Anf : 12|8@1+ (50,0) [0|12600] "Unit_WattHour"  Gateway,Gateway_PAG,Ladegeraet_Konzern
 SG_ TME_Kuehlerluefer_3 : 20|7@1+ (1,0) [0|100] "Unit_PerCent"  Gateway,Gateway_PAG
 SG_ TME_StartStopp_Info_Prio : 27|1@1+ (1.0,0.0) [0.0|1] ""  Gateway,Gateway_PAG
 SG_ TME_HVEM_HV_Anf : 28|2@1+ (1.0,0.0) [0.0|3] ""  Gateway,Gateway_PAG
 SG_ TME_StartStopp_Info : 30|2@1+ (1.0,0.0) [0.0|3] ""  Gateway,Gateway_PAG
 SG_ TME_OBD_Lampe_Anf : 32|1@1+ (1.0,0.0) [0.0|1] ""  Gateway,Gateway_PAG
 SG_ TME_HVPTC_Istmodus : 33|3@1+ (1.0,0.0) [0.0|7] ""  Gateway,Gateway_PAG
 SG_ TME_HVPTC_Fehlerstatus : 36|3@1+ (1.0,0.0) [0.0|7] ""  Gateway,Gateway_PAG
 SG_ TME_EKK_Istmodus : 39|3@1+ (1.0,0.0) [0.0|7] ""  Gateway,Gateway_PAG
 SG_ TME_EKK_Fehlerstatus : 42|3@1+ (1.0,0.0) [0.0|7] ""  Gateway,Gateway_PAG
 SG_ TME_HVK_EKK_SOLL : 45|2@1+ (1.0,0.0) [0.0|3] ""  Gateway,Gateway_PAG
 SG_ TME_Strom_Kuehlerluefter : 51|5@1+ (5,0) [0|145] "Unit_Amper"  Gateway,Gateway_PAG
 SG_ TME_PWM_Pumpe1_tNT_Soll : 57|7@1+ (1,0) [0|100] "Unit_PerCent"  BMC_MLBevo,Gateway,Gateway_PAG

BO_ 1017 TME_08: 8 TME
 SG_ TME_NT_Kreis_Status : 6|1@1+ (1.0,0.0) [0.0|1] ""  CBC,DCDC_800V_PAG,DCDC_HV,Gateway,Gateway_PAG,LE1,LE2,LE_MLBevo
 SG_ TME_Ventil1_Status : 7|1@1+ (1.0,0.0) [0.0|1] ""  Gateway,Gateway_PAG
 SG_ TME_Fehler_ElWaPu1 : 8|1@1+ (1.0,0.0) [0.0|1] ""  Gateway,Gateway_PAG
 SG_ TME_Pumpe1_Status : 9|1@1+ (1.0,0.0) [0.0|1] ""  Gateway,Gateway_PAG
 SG_ TME_Nachlaufzeit : 10|6@1+ (15,0) [15|945] "Unit_Secon"  Gateway,Gateway_PAG
 SG_ TME_Anf_KL : 16|7@1+ (1,0) [0|100] "Unit_PerCent"  Gateway,Gateway_PAG
 SG_ TME_Status_KL : 25|3@1+ (1.0,0.0) [0.0|7] ""  Gateway,Gateway_PAG
 SG_ TME_MMTR_Status : 28|4@1+ (1.0,0.0) [0.0|15] ""  BMC_MLBevo,Gateway,Gateway_PAG
 SG_ TME_EM1_IstVolumenstrom : 34|5@1+ (0.5,0) [0.0|14.5] "Unit_LiterPerMinut"  Gateway,Gateway_PAG
 SG_ TME_EM2_IstVolumenstrom : 39|5@1+ (0.5,0) [0.0|14.5] "Unit_LiterPerMinut"  Gateway,Gateway_PAG
 SG_ TME_EM3_IstVolumenstrom : 44|5@1+ (0.5,0) [0.0|14.5] "Unit_LiterPerMinut"  Gateway,Gateway_PAG
 SG_ TME_PWM_Pumpe2_HK_Soll : 49|7@1+ (1,0) [0|100] "Unit_PerCent"  Gateway,Gateway_PAG

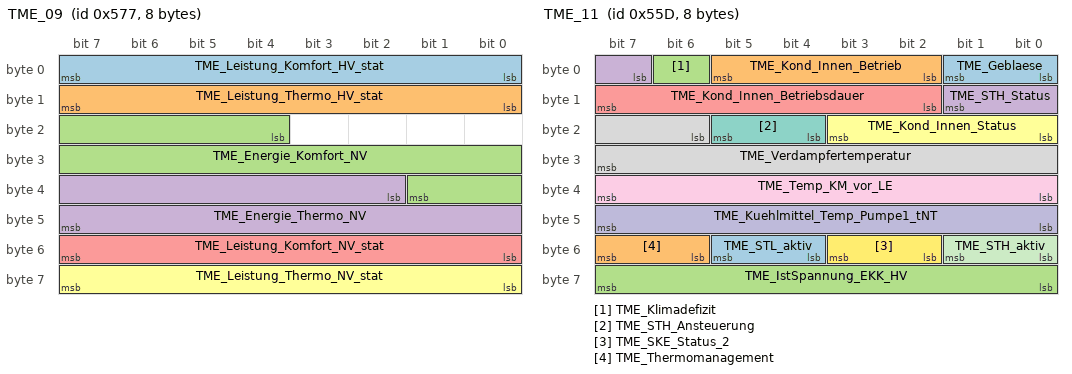
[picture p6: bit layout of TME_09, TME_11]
BO_ 1399 TME_09: 8 TME
 SG_ TME_Leistung_Komfort_HV_stat : 0|8@1+ (50,0) [0|12650] "Unit_Watt"  Ladegeraet_Konzern
 SG_ TME_Leistung_Thermo_HV_stat : 8|8@1+ (50,0) [0|12650] "Unit_Watt"  Ladegeraet_Konzern
 SG_ TME_Energie_Komfort_NV : 20|14@1+ (5,0) [0|63250] "Unit_WattHour"  Ladegeraet_Konzern
 SG_ TME_Energie_Thermo_NV : 34|14@1+ (5,0) [0|63250] "Unit_WattHour"  Ladegeraet_Konzern
 SG_ TME_Leistung_Komfort_NV_stat : 48|8@1+ (10,0) [0|2530] "Unit_Watt"  Ladegeraet_Konzern
 SG_ TME_Leistung_Thermo_NV_stat : 56|8@1+ (10,0) [0|2530] "Unit_Watt"  Ladegeraet_Konzern

BO_ 1375 TME_10: 8 TME
 SG_ TME_VoKo_Strategie_Anzeige : 2|4@1+ (1.0,0.0) [0.0|15] ""  Gateway,Gateway_PAG,Ladegeraet_Konzern
 SG_ TME_Zuheizer_Freigabe : 6|1@1+ (1.0,0.0) [0.0|1] ""  Gateway,Gateway_PAG
 SG_ TME_AC_LED : 7|1@1+ (1.0,0.0) [0.0|1] ""  Gateway,Gateway_PAG
 SG_ TME_Heizstrategie : 8|4@1+ (1.0,0.0) [0.0|15] ""  Gateway,Gateway_PAG,Ladegeraet_Konzern
 SG_ TME_Systemstatus : 12|2@1+ (1.0,0.0) [0.0|3] ""  Gateway,Gateway_PAG
 SG_ TME_Kbr_Innenraum : 14|1@1+ (1.0,0.0) [0.0|1] ""  Gateway,Gateway_PAG
 SG_ TME_Freigabe_Vorkond : 15|1@1+ (1.0,0.0) [0.0|1] ""  Gateway,Gateway_PAG,Ladegeraet_Konzern
 SG_ TME_Verdampfer_Status : 16|1@1+ (1.0,0.0) [0.0|1] ""  Gateway,Gateway_PAG
 SG_ TME_Kuehlmittel_Sensor : 17|1@1+ (1.0,0.0) [0.0|1] ""  BMC_MLBevo,Gateway,Gateway_PAG
 SG_ TME_AC_Rueckmeldung : 18|2@1+ (1.0,0.0) [0.0|3] ""  Gateway,Gateway_PAG
 SG_ TME_Heizungspumpen_Anst : 20|4@1+ (10,0) [0|100] "Unit_PerCent"  FCU_MLBevo_FCEV,Gateway,Gateway_PAG
 SG_ TME_Frischluftklappe_Soll : 24|7@1+ (1,0) [0|100] "Unit_PerCent"  Gateway,Gateway_PAG
 SG_ TME_Freigabe_Luft_PTC : 31|1@1+ (1.0,0.0) [0.0|1] ""  Gateway,Gateway_PAG
 SG_ TME_Umluftklappe_Soll : 32|7@1+ (1,0) [0|100] "Unit_PerCent"  Gateway,Gateway_PAG
 SG_ TME_Waermepumpe_aktiv : 39|1@1+ (1.0,0.0) [0.0|1] ""  Gateway,Gateway_PAG
 SG_ TME_Nachlaufzeit_Heizp : 40|6@1+ (15,0) [0|945] "Unit_Secon"  Gateway,Gateway_PAG
 SG_ TME_Absperrventil1_oeffnen : 46|2@1+ (1.0,0.0) [0.0|3] ""  Gateway,Gateway_PAG
 SG_ TME_Klima_Defizit : 48|8@1+ (40,0) [0|10000] "Unit_Watt"  Gateway,Gateway_PAG
 SG_ TME_Temp_KM_vor_HWT : 56|8@1+ (0.75,-40) [-40.00|149.75] "Unit_DegreCelsi"  Gateway,Gateway_PAG

BO_ 1373 TME_11: 8 TME
 SG_ TME_Geblaese : 0|2@1+ (1.0,0.0) [0.0|3] ""  Gateway,Gateway_PAG
 SG_ TME_Kond_Innen_Betrieb : 2|4@1+ (1.0,0.0) [0.0|15] ""  Gateway,Gateway_PAG,Ladegeraet_Konzern
 SG_ TME_Klimadefizit : 6|1@1+ (1.0,0.0) [0.0|1] ""  Gateway,Gateway_PAG
 SG_ TME_STH_Status : 7|3@1+ (1.0,0.0) [0.0|7] ""  Gateway,Gateway_PAG,Ladegeraet_Konzern
 SG_ TME_Kond_Innen_Betriebsdauer : 10|6@1+ (1,0) [0|60] "Unit_Minut"  Gateway,Gateway_PAG,Ladegeraet_Konzern
 SG_ TME_Kond_Innen_Status : 16|4@1+ (1.0,0.0) [0.0|15] ""  Gateway,Gateway_PAG,Ladegeraet_Konzern
 SG_ TME_STH_Ansteuerung : 20|2@1+ (1.0,0.0) [0.0|3] ""  Gateway,Gateway_PAG
 SG_ TME_Verdampfertemperatur : 22|10@1+ (0.1,-20) [-20.0|70.0] "Unit_DegreCelsi"  Gateway,Gateway_PAG
 SG_ TME_Temp_KM_vor_LE : 32|8@1+ (0.75,-48) [-48.00|141.75] "Unit_DegreCelsi"  FCU_MLBevo_FCEV,Gateway,Gateway_PAG,LE1,LE2,LE_MLBevo
 SG_ TME_Kuehlmittel_Temp_Pumpe1_tNT : 40|8@1+ (1,-40) [-40|213] "Unit_DegreCelsi"  BMC_MLBevo,Gateway,Gateway_PAG
 SG_ TME_STH_aktiv : 48|2@1+ (1.0,0.0) [0.0|3] ""  Gateway,Gateway_PAG
 SG_ TME_SKE_Status_2 : 50|2@1+ (1.0,0.0) [0.0|3] ""  Gateway,Gateway_PAG
 SG_ TME_STL_aktiv : 52|2@1+ (1.0,0.0) [0.0|3] ""  Gateway,Gateway_PAG
 SG_ TME_Thermomanagement : 54|2@1+ (1.0,0.0) [0.0|3] ""  Gateway,Gateway_PAG
 SG_ TME_IstSpannung_EKK_HV : 56|8@1+ (2,0) [0|508] "Unit_Volt"  DCDC_800V_PAG,Gateway,Gateway_PAG

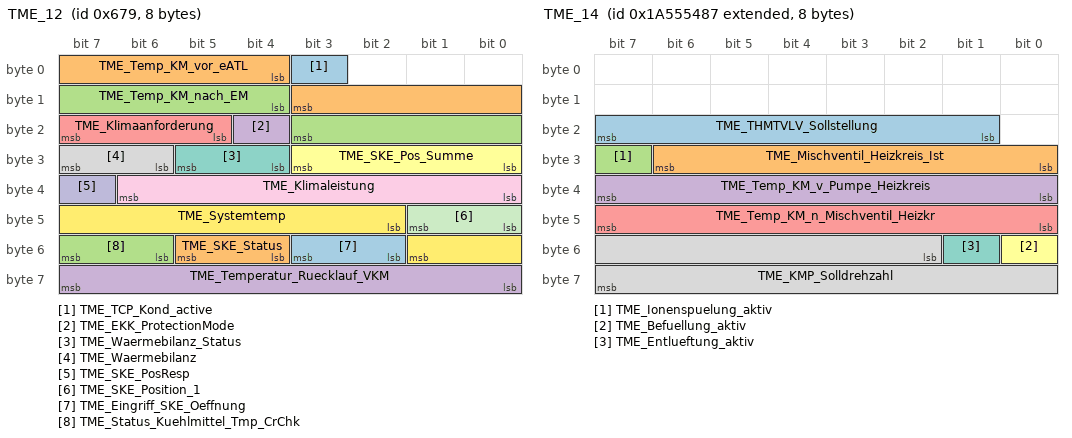
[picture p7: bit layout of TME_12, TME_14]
BO_ 1657 TME_12: 8 TME
 SG_ TME_TCP_Kond_active : 3|1@1+ (1.0,0.0) [0.0|1] ""  Gateway,Gateway_PAG
 SG_ TME_Temp_KM_vor_eATL : 4|8@1+ (1,-40) [-40|213] "Unit_DegreCelsi"  Gateway,Gateway_PAG
 SG_ TME_Temp_KM_nach_EM : 12|8@1+ (0.75,-48) [-48.00|141.00] "Unit_DegreCelsi"  Gateway,Gateway_PAG
 SG_ TME_EKK_ProtectionMode : 20|1@1+ (1.0,0.0) [0.0|1] ""  Gateway,Gateway_PAG
 SG_ TME_Klimaanforderung : 21|3@1+ (1.0,0.0) [0.0|7] ""  Gateway,Gateway_PAG
 SG_ TME_SKE_Pos_Summe : 24|4@1+ (10,0) [0|100] "Unit_PerCent"  Gateway,Gateway_PAG
 SG_ TME_Waermebilanz_Status : 28|2@1+ (1.0,0.0) [0.0|3] ""  Gateway,Gateway_PAG
 SG_ TME_Waermebilanz : 30|2@1+ (1.0,0.0) [0.0|3] ""  Gateway,Gateway_PAG
 SG_ TME_Klimaleistung : 32|7@1+ (0.04,0) [0.00|5.00] "Unit_KiloWatt"  Gateway,Gateway_PAG
 SG_ TME_SKE_PosResp : 39|1@1+ (1.0,0.0) [0.0|1] ""  Gateway,Gateway_PAG
 SG_ TME_SKE_Position_1 : 40|2@1+ (1.0,0.0) [0.0|3] ""  Gateway,Gateway_PAG
 SG_ TME_Systemtemp : 42|8@1+ (0.75,-48) [-48.00|141.75] "Unit_DegreCelsi"  Gateway,Gateway_PAG
 SG_ TME_Eingriff_SKE_Oeffnung : 50|2@1+ (1.0,0.0) [0.0|3] ""  Gateway,Gateway_PAG
 SG_ TME_SKE_Status : 52|2@1+ (1.0,0.0) [0.0|3] ""  Gateway,Gateway_PAG
 SG_ TME_Status_Kuehlmittel_Tmp_CrChk : 54|2@1+ (1.0,0.0) [0.0|3] ""  Gateway,Gateway_PAG
 SG_ TME_Temperatur_Ruecklauf_VKM : 56|8@1+ (0.75,-40) [-40.00|149.75] "Unit_DegreCelsi"  Gateway,Gateway_PAG

BO_ 2463978655 TME_13: 8 TME
 SG_ TME_Senkenleistung_verfuegbar : 55|9@1+ (0.1,0) [0.0|50.9] "Unit_KiloWatt"  FCU_MLBevo_FCEV,Gateway

BO_ 2589283463 TME_14: 8 TME
 SG_ TME_THMTVLV_Sollstellung : 17|7@1+ (1,0) [0|100] "Unit_PerCent"  FCU_MLBevo_FCEV
 SG_ TME_Mischventil_Heizkreis_Ist : 24|7@1+ (1,0) [0|100] "Unit_PerCent"  FCU_MLBevo_FCEV
 SG_ TME_Ionenspuelung_aktiv : 31|1@1+ (1.0,0.0) [0.0|1] ""  FCU_MLBevo_FCEV
 SG_ TME_Temp_KM_v_Pumpe_Heizkreis : 32|8@1+ (0.75,-48) [-48.00|141.75] "Unit_DegreCelsi"  FCU_MLBevo_FCEV
 SG_ TME_Temp_KM_n_Mischventil_Heizkr : 40|8@1+ (0.75,-48) [-48.00|141.75] "Unit_DegreCelsi"  FCU_MLBevo_FCEV
 SG_ TME_Befuellung_aktiv : 48|1@1+ (1.0,0.0) [0.0|1] ""  FCU_MLBevo_FCEV
 SG_ TME_Entlueftung_aktiv : 49|1@1+ (1.0,0.0) [0.0|1] ""  FCU_MLBevo_FCEV
 SG_ TME_KMP_Solldrehzahl : 50|14@1+ (1,0) [0|16381] "Unit_RevPerMinute"  FCU_MLBevo_FCEV

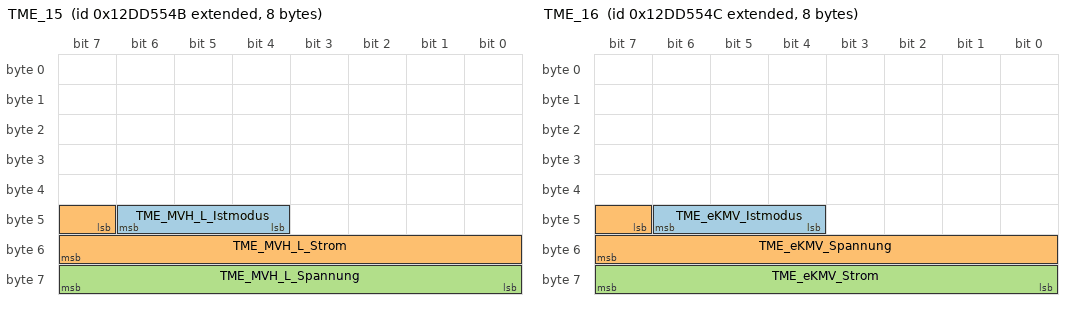
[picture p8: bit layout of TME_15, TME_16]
BO_ 2463978827 TME_15: 8 TME
 SG_ TME_MVH_L_Istmodus : 44|3@1+ (1.0,0.0) [0.0|7] ""  Gateway
 SG_ TME_MVH_L_Strom : 47|9@1+ (0.25,0) [0.00|127.25] "Unit_Amper"  Gateway
 SG_ TME_MVH_L_Spannung : 56|8@1+ (0.25,0) [0.00|63.25] "Unit_Volt"  Gateway

BO_ 2463978828 TME_16: 8 TME
 SG_ TME_eKMV_Istmodus : 44|3@1+ (1.0,0.0) [0.0|7] ""  Gateway
 SG_ TME_eKMV_Spannung : 47|9@1+ (0.2,0) [0.0|101.8] "Unit_Volt"  Gateway
 SG_ TME_eKMV_Strom : 56|8@1+ (0.75,0) [0.00|189.75] "Unit_Amper"  Gateway

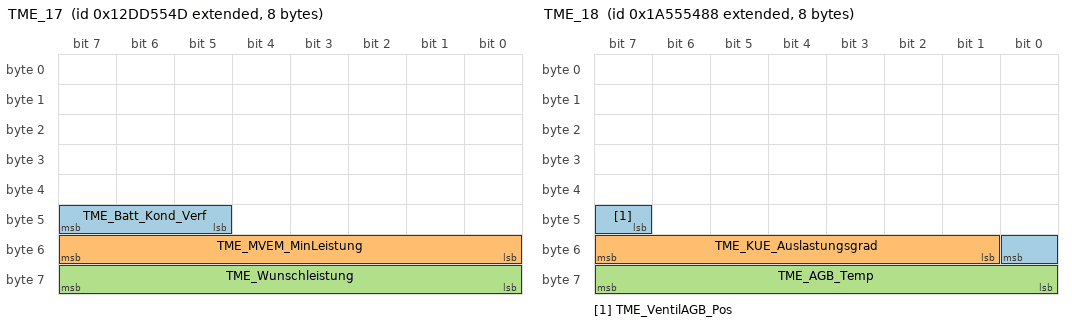
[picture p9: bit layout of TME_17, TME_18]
BO_ 2463978829 TME_17: 8 TME
 SG_ TME_Batt_Kond_Verf : 45|3@1+ (1.0,0.0) [0.0|7] ""  BMC_MLBevo
 SG_ TME_MVEM_MinLeistung : 48|8@1+ (50,0) [0|12650] "Unit_Watt"  Gateway
 SG_ TME_Wunschleistung : 56|8@1+ (50,0) [0|12650] "Unit_Watt"  Gateway

BO_ 2589283464 TME_18: 8 TME
 SG_ TME_VentilAGB_Pos : 47|2@1+ (1.0,0.0) [0.0|3] ""  Gateway,Gateway_PAG
 SG_ TME_KUE_Auslastungsgrad : 49|7@1+ (1,0) [0|100] "Unit_PerCent"  BMC_MLBevo,Gateway,Gateway_PAG
 SG_ TME_AGB_Temp : 56|8@1+ (1,-40) [-40|213] "Unit_DegreCelsi"  Gateway,Gateway_PAG

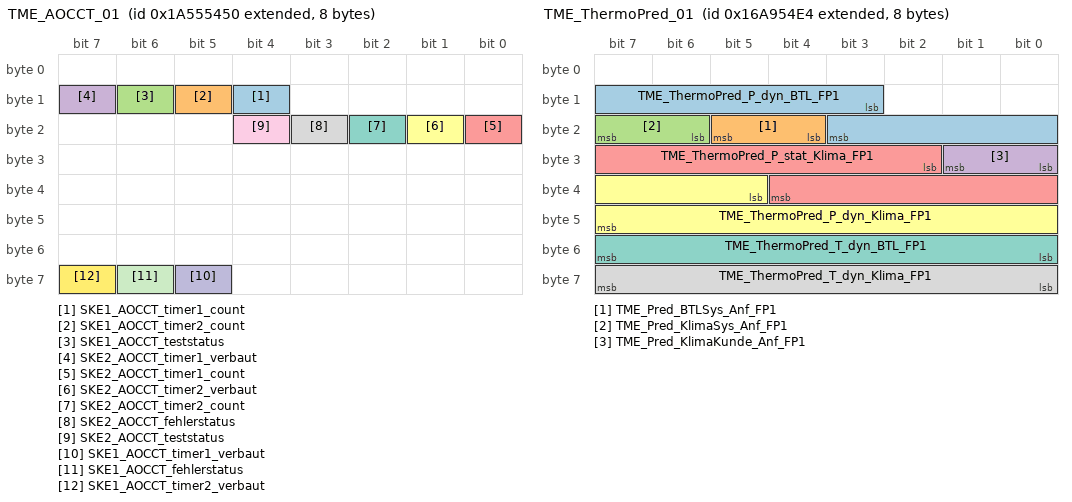
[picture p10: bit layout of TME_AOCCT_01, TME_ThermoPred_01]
BO_ 2589283408 TME_AOCCT_01: 8 TME
 SG_ SKE1_AOCCT_timer1_count : 12|1@1+ (1.0,0.0) [0.0|1] ""  Gateway,Gateway_PAG
 SG_ SKE1_AOCCT_timer2_count : 13|1@1+ (1.0,0.0) [0.0|1] ""  Gateway,Gateway_PAG
 SG_ SKE1_AOCCT_teststatus : 14|1@1+ (1.0,0.0) [0.0|1] ""  Gateway,Gateway_PAG
 SG_ SKE2_AOCCT_timer1_verbaut : 15|1@1+ (1.0,0.0) [0.0|1] ""  Gateway,Gateway_PAG
 SG_ SKE2_AOCCT_timer1_count : 16|1@1+ (1.0,0.0) [0.0|1] ""  Gateway,Gateway_PAG
 SG_ SKE2_AOCCT_timer2_verbaut : 17|1@1+ (1.0,0.0) [0.0|1] ""  Gateway,Gateway_PAG
 SG_ SKE2_AOCCT_timer2_count : 18|1@1+ (1.0,0.0) [0.0|1] ""  Gateway,Gateway_PAG
 SG_ SKE2_AOCCT_fehlerstatus : 19|1@1+ (1.0,0.0) [0.0|1] ""  Gateway,Gateway_PAG
 SG_ SKE2_AOCCT_teststatus : 20|1@1+ (1.0,0.0) [0.0|1] ""  Gateway,Gateway_PAG
 SG_ SKE1_AOCCT_timer1_verbaut : 61|1@1+ (1.0,0.0) [0.0|1] ""  Gateway,Gateway_PAG
 SG_ SKE1_AOCCT_fehlerstatus : 62|1@1+ (1.0,0.0) [0.0|1] ""  Gateway,Gateway_PAG
 SG_ SKE1_AOCCT_timer2_verbaut : 63|1@1+ (1.0,0.0) [0.0|1] ""  Gateway,Gateway_PAG

BO_ 2527679716 TME_ThermoPred_01: 8 TME
 SG_ TME_ThermoPred_P_dyn_BTL_FP1 : 11|9@1+ (50,0) [0|20450] "Unit_Watt"  Gateway,Gateway_PAG
 SG_ TME_Pred_BTLSys_Anf_FP1 : 20|2@1+ (1,0) [0|3] ""  Gateway,Gateway_PAG
 SG_ TME_Pred_KlimaSys_Anf_FP1 : 22|2@1+ (1,0) [0|3] ""  Gateway,Gateway_PAG
 SG_ TME_Pred_KlimaKunde_Anf_FP1 : 24|2@1+ (1,0) [0|3] ""  Gateway,Gateway_PAG
 SG_ TME_ThermoPred_P_stat_Klima_FP1 : 26|11@1+ (10,0) [0|20450] "Unit_Watt"  Gateway,Gateway_PAG
 SG_ TME_ThermoPred_P_dyn_Klima_FP1 : 37|11@1+ (10,0) [0|20450] "Unit_Watt"  Gateway,Gateway_PAG
 SG_ TME_ThermoPred_T_dyn_BTL_FP1 : 48|8@1+ (1,0) [0|253] "Unit_Minut"  Gateway,Gateway_PAG
 SG_ TME_ThermoPred_T_dyn_Klima_FP1 : 56|8@1+ (1,0) [0|253] "Unit_Minut"  Gateway,Gateway_PAG

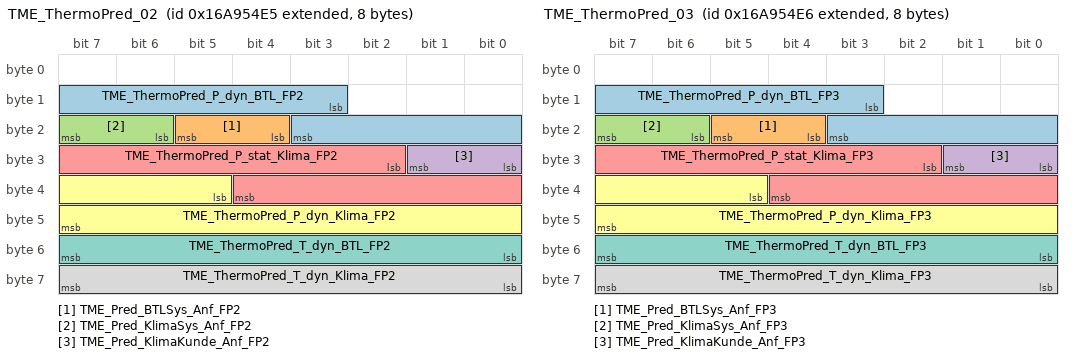
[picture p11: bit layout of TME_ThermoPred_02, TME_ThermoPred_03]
BO_ 2527679717 TME_ThermoPred_02: 8 TME
 SG_ TME_ThermoPred_P_dyn_BTL_FP2 : 11|9@1+ (50,0) [0|20450] "Unit_Watt"  Gateway,Gateway_PAG
 SG_ TME_Pred_BTLSys_Anf_FP2 : 20|2@1+ (1,0) [0|3] ""  Gateway,Gateway_PAG
 SG_ TME_Pred_KlimaSys_Anf_FP2 : 22|2@1+ (1,0) [0|3] ""  Gateway,Gateway_PAG
 SG_ TME_Pred_KlimaKunde_Anf_FP2 : 24|2@1+ (1,0) [0|3] ""  Gateway,Gateway_PAG
 SG_ TME_ThermoPred_P_stat_Klima_FP2 : 26|11@1+ (10,0) [0|20450] "Unit_Watt"  Gateway,Gateway_PAG
 SG_ TME_ThermoPred_P_dyn_Klima_FP2 : 37|11@1+ (10,0) [0|20450] "Unit_Watt"  Gateway,Gateway_PAG
 SG_ TME_ThermoPred_T_dyn_BTL_FP2 : 48|8@1+ (1,0) [0|253] "Unit_Minut"  Gateway,Gateway_PAG
 SG_ TME_ThermoPred_T_dyn_Klima_FP2 : 56|8@1+ (1,0) [0|253] "Unit_Minut"  Gateway,Gateway_PAG

BO_ 2527679718 TME_ThermoPred_03: 8 TME
 SG_ TME_ThermoPred_P_dyn_BTL_FP3 : 11|9@1+ (50,0) [0|20450] "Unit_Watt"  Gateway,Gateway_PAG
 SG_ TME_Pred_BTLSys_Anf_FP3 : 20|2@1+ (1,0) [0|3] ""  Gateway,Gateway_PAG
 SG_ TME_Pred_KlimaSys_Anf_FP3 : 22|2@1+ (1,0) [0|3] ""  Gateway,Gateway_PAG
 SG_ TME_Pred_KlimaKunde_Anf_FP3 : 24|2@1+ (1,0) [0|3] ""  Gateway,Gateway_PAG
 SG_ TME_ThermoPred_P_stat_Klima_FP3 : 26|11@1+ (10,0) [0|20450] "Unit_Watt"  Gateway,Gateway_PAG
 SG_ TME_ThermoPred_P_dyn_Klima_FP3 : 37|11@1+ (10,0) [0|20450] "Unit_Watt"  Gateway,Gateway_PAG
 SG_ TME_ThermoPred_T_dyn_BTL_FP3 : 48|8@1+ (1,0) [0|253] "Unit_Minut"  Gateway,Gateway_PAG
 SG_ TME_ThermoPred_T_dyn_Klima_FP3 : 56|8@1+ (1,0) [0|253] "Unit_Minut"  Gateway,Gateway_PAG

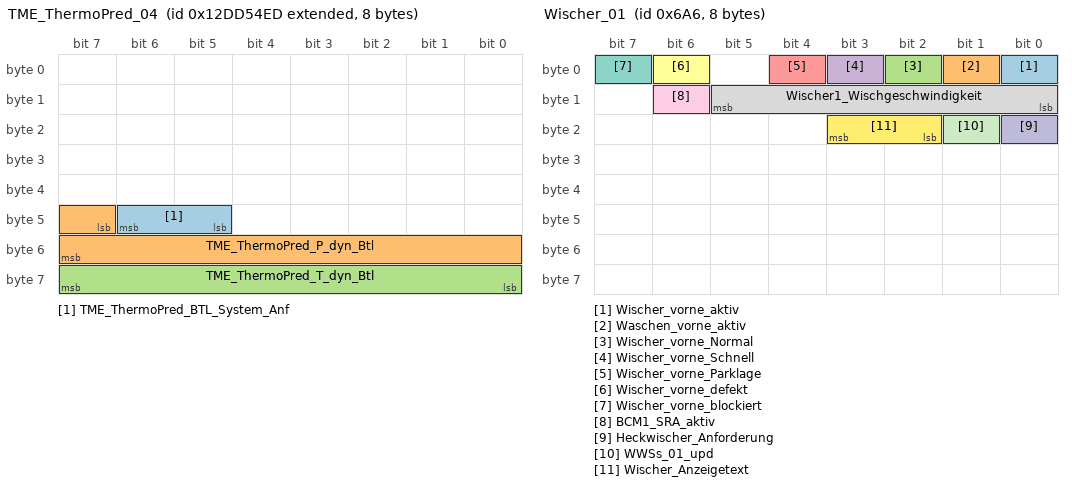
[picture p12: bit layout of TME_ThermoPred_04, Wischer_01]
BO_ 2463978733 TME_ThermoPred_04: 8 TME
 SG_ TME_ThermoPred_BTL_System_Anf : 45|2@1+ (1,0) [0|3] ""  Gateway,Gateway_PAG
 SG_ TME_ThermoPred_P_dyn_Btl : 47|9@1+ (50,0) [0|20450] "Unit_Watt"  Gateway,Gateway_PAG
 SG_ TME_ThermoPred_T_dyn_Btl : 56|8@1+ (1.0,0.0) [0.0|255] ""  Gateway,Gateway_PAG

BO_ 977 TSG_BT_01: 8 Gateway
 SG_ BT_Tuer_geoeffnet : 0|1@1+ (1.0,0.0) [0.0|1] ""  Ladegeraet_Konzern,TME
 SG_ BT_verriegelt : 1|1@1+ (1.0,0.0) [0.0|1] ""  Vector__XXX
 SG_ BT_gesafet : 2|1@1+ (1.0,0.0) [0.0|1] ""  Vector__XXX
 SG_ BT_Schluesselschalter_auf : 3|1@1+ (1.0,0.0) [0.0|1] ""  Vector__XXX
 SG_ BT_Schluesselschalter_zu : 4|1@1+ (1.0,0.0) [0.0|1] ""  Vector__XXX
 SG_ BT_Unlock_Taster : 5|1@1+ (1.0,0.0) [0.0|1] ""  Vector__XXX
 SG_ BT_Lock_Taster : 6|1@1+ (1.0,0.0) [0.0|1] ""  Vector__XXX
 SG_ BT_Sperrklinke : 7|1@1+ (1.0,0.0) [0.0|1] ""  Vector__XXX
 SG_ BT_TAG_betaetigt : 8|1@1+ (1.0,0.0) [0.0|1] ""  Vector__XXX
 SG_ BT_TIG_betaetigt : 9|1@1+ (1.0,0.0) [0.0|1] ""  Vector__XXX
 SG_ BT_EC_Spiegel_Helligkeit : 10|5@1+ (3.125,0) [0.000|96.875] "Unit_PerCent"  Vector__XXX
 SG_ BT_Sp_Heizung_Anf : 15|1@1+ (100,0) [0|100] "Unit_PerCent"  Vector__XXX
 SG_ BT_Tuer_Status : 16|2@1+ (1.0,0.0) [0.0|3] ""  Vector__XXX
 SG_ BT_TSG_hinten_verbaut : 18|1@1+ (1.0,0.0) [0.0|1] ""  Vector__XXX
 SG_ BT_Sp_Blk_def : 19|1@1+ (1.0,0.0) [0.0|1] ""  Vector__XXX
 SG_ BT_FH_S_ManHoch : 20|1@1+ (1.0,0.0) [0.0|1] ""  Vector__XXX
 SG_ BT_FH_S_AutoHoch : 21|1@1+ (1.0,0.0) [0.0|1] ""  Vector__XXX
 SG_ BT_FH_S_ManTief : 22|1@1+ (1.0,0.0) [0.0|1] ""  Vector__XXX
 SG_ BT_FH_S_AutoTief : 23|1@1+ (1.0,0.0) [0.0|1] ""  Vector__XXX
 SG_ BT_FH_Oeffnung : 24|8@1+ (0.5,0) [0.0|100.0] "Unit_PerCent"  TME
 SG_ BT_FH_Bew_hoch : 32|1@1+ (1.0,0.0) [0.0|1] ""  Vector__XXX
 SG_ BT_FH_Bew_tief : 33|1@1+ (1.0,0.0) [0.0|1] ""  Vector__XXX
 SG_ BT_FH_Fang : 34|1@1+ (1.0,0.0) [0.0|1] ""  Vector__XXX
 SG_ BT_FH_Block : 35|1@1+ (1.0,0.0) [0.0|1] ""  Vector__XXX
 SG_ BT_FH_Thermo : 36|1@1+ (1.0,0.0) [0.0|1] ""  Vector__XXX
 SG_ BT_UEKB_aktiviert : 37|1@1+ (1.0,0.0) [0.0|1] ""  Vector__XXX
 SG_ BT_Kisi_Fehler : 38|1@1+ (1.0,0.0) [0.0|1] ""  Vector__XXX
 SG_ BT_FH_normiert : 39|1@1+ (1.0,0.0) [0.0|1] ""  Vector__XXX
 SG_ BT_Schliesstaster : 40|1@1+ (1.0,0.0) [0.0|1] ""  Vector__XXX
 SG_ BT_Zuziehhilfe_aktiv : 41|1@1+ (1.0,0.0) [0.0|1] ""  Vector__XXX
 SG_ BT_SP_ausgerastet : 42|1@1+ (1.0,0.0) [0.0|1] ""  Vector__XXX
 SG_ BT_SP_lr_aktiv : 43|1@1+ (1.0,0.0) [0.0|1] ""  Vector__XXX
 SG_ BT_SP_ht_aktiv : 44|1@1+ (1.0,0.0) [0.0|1] ""  Vector__XXX
 SG_ BT_SP_Heizung_aktiv : 45|1@1+ (1.0,0.0) [0.0|1] ""  Vector__XXX
 SG_ BT_Oben_Block_erw : 46|1@1+ (1.0,0.0) [0.0|1] ""  Vector__XXX
 SG_ BT_Unten_Block_erw : 47|1@1+ (1.0,0.0) [0.0|1] ""  Vector__XXX
 SG_ BT_Tuer_Status_QBit : 48|1@1+ (1.0,0.0) [0.0|1] ""  Vector__XXX
 SG_ BFS_Status_eTAG : 49|2@1+ (1.0,0.0) [0.0|3] ""  Vector__XXX
 SG_ BT_TCR_Mode_aktiv : 51|1@1+ (1.0,0.0) [0.0|1] ""  Vector__XXX
 SG_ BT_SP_Heizung_Status : 55|1@1+ (1.0,0.0) [0.0|1] ""  Vector__XXX
 SG_ ASW_Warnung_aktiv_BFS : 56|1@1+ (1.0,0.0) [0.0|1] ""  Vector__XXX
 SG_ BT_FH_Pos_oben : 57|1@1+ (1.0,0.0) [0.0|1] ""  Vector__XXX
 SG_ BT_Tuerschloss_defekt : 58|1@1+ (1.0,0.0) [0.0|1] ""  Vector__XXX
 SG_ BT_Tueroeffnen_Warnung : 59|1@1+ (1.0,0.0) [0.0|1] ""  Vector__XXX
 SG_ BT_Lock_Taster_inv : 60|1@1+ (1.0,0.0) [0.0|1] ""  Vector__XXX
 SG_ BT_Schluesselschalter_zu_inv : 61|1@1+ (1.0,0.0) [0.0|1] ""  Vector__XXX
 SG_ BT_SWA_HMI_defekt : 62|1@1+ (1.0,0.0) [0.0|1] ""  Vector__XXX
 SG_ BT_ASW_HMI_defekt : 63|1@1+ (1.0,0.0) [0.0|1] ""  Vector__XXX

BO_ 976 TSG_FT_01: 8 Gateway
 SG_ FT_Tuer_geoeffnet : 0|1@1+ (1.0,0.0) [0.0|1] ""  Ladegeraet_Konzern,TME
 SG_ FT_verriegelt : 1|1@1+ (1.0,0.0) [0.0|1] ""  Vector__XXX
 SG_ FT_gesafet : 2|1@1+ (1.0,0.0) [0.0|1] ""  Vector__XXX
 SG_ FT_Schluesselschalter_auf : 3|1@1+ (1.0,0.0) [0.0|1] ""  FCU_MLBevo_FCEV
 SG_ FT_Schluesselschalter_zu : 4|1@1+ (1.0,0.0) [0.0|1] ""  FCU_MLBevo_FCEV
 SG_ FT_Unlock_Taster : 5|1@1+ (1.0,0.0) [0.0|1] ""  Vector__XXX
 SG_ FT_Lock_Taster : 6|1@1+ (1.0,0.0) [0.0|1] ""  Vector__XXX
 SG_ FT_Sperrklinke : 7|1@1+ (1.0,0.0) [0.0|1] ""  Vector__XXX
 SG_ FT_TAG_betaetigt : 8|1@1+ (1.0,0.0) [0.0|1] ""  Vector__XXX
 SG_ FT_TIG_betaetigt : 9|1@1+ (1.0,0.0) [0.0|1] ""  Vector__XXX
 SG_ FT_IRUE_Taste : 10|1@1+ (1.0,0.0) [0.0|1] ""  Vector__XXX
 SG_ FT_HD_Taste : 11|1@1+ (1.0,0.0) [0.0|1] ""  Vector__XXX
 SG_ FT_TD_Taste_Fehler : 12|1@1+ (1.0,0.0) [0.0|1] ""  FCU_MLBevo_FCEV,Ladegeraet_Konzern
 SG_ FT_TD_Taste : 13|1@1+ (1.0,0.0) [0.0|1] ""  FCU_MLBevo_FCEV,Ladegeraet_Konzern
 SG_ SSR_Temp_Freigabe : 14|1@1+ (1.0,0.0) [0.0|1] ""  Vector__XXX
 SG_ FT_Sp_Heizung_Anf : 15|1@1+ (100,0) [0|100] "Unit_PerCent"  Vector__XXX
 SG_ FT_HD_Taste_2 : 16|1@1+ (1.0,0.0) [0.0|1] ""  Vector__XXX
 SG_ FT_TSG_hinten_verbaut : 18|1@1+ (1.0,0.0) [0.0|1] ""  Vector__XXX
 SG_ FT_Sp_Blk_def : 19|1@1+ (1.0,0.0) [0.0|1] ""  Vector__XXX
 SG_ FT_FH_S_ManHoch : 20|1@1+ (1.0,0.0) [0.0|1] ""  Vector__XXX
 SG_ FT_FH_S_AutoHoch : 21|1@1+ (1.0,0.0) [0.0|1] ""  Vector__XXX
 SG_ FT_FH_S_ManTief : 22|1@1+ (1.0,0.0) [0.0|1] ""  Vector__XXX
 SG_ FT_FH_S_AutoTief : 23|1@1+ (1.0,0.0) [0.0|1] ""  Vector__XXX
 SG_ FT_FH_Oeffnung : 24|8@1+ (0.5,0) [0.0|100.0] "Unit_PerCent"  TME
 SG_ FT_FH_Bew_hoch : 32|1@1+ (1.0,0.0) [0.0|1] ""  Vector__XXX
 SG_ FT_FH_Bew_tief : 33|1@1+ (1.0,0.0) [0.0|1] ""  Vector__XXX
 SG_ FT_FH_Fang : 34|1@1+ (1.0,0.0) [0.0|1] ""  Vector__XXX
 SG_ FT_FH_Block : 35|1@1+ (1.0,0.0) [0.0|1] ""  Vector__XXX
 SG_ FT_FH_Thermo : 36|1@1+ (1.0,0.0) [0.0|1] ""  Vector__XXX
 SG_ FT_UEKB_aktiviert : 37|1@1+ (1.0,0.0) [0.0|1] ""  Vector__XXX
 SG_ ASW_HMI_defekt : 38|1@1+ (1.0,0.0) [0.0|1] ""  Vector__XXX
 SG_ FT_FH_normiert : 39|1@1+ (1.0,0.0) [0.0|1] ""  Vector__XXX
 SG_ FT_Schliesstaster : 40|1@1+ (1.0,0.0) [0.0|1] ""  Vector__XXX
 SG_ FT_Zuziehhilfe_aktiv : 41|1@1+ (1.0,0.0) [0.0|1] ""  Vector__XXX
 SG_ FT_SP_ausgerastet : 42|1@1+ (1.0,0.0) [0.0|1] ""  Vector__XXX
 SG_ FT_SP_lr_aktiv : 43|1@1+ (1.0,0.0) [0.0|1] ""  Vector__XXX
 SG_ FT_SP_ht_aktiv : 44|1@1+ (1.0,0.0) [0.0|1] ""  Vector__XXX
 SG_ ASW_wakeup : 45|1@1+ (1.0,0.0) [0.0|1] ""  Vector__XXX
 SG_ FT_Oben_Block_erw : 46|1@1+ (1.0,0.0) [0.0|1] ""  Vector__XXX
 SG_ FT_Unten_Block_erw : 47|1@1+ (1.0,0.0) [0.0|1] ""  Vector__XXX
 SG_ FT_Kisi_li_aktiv : 48|1@1+ (1.0,0.0) [0.0|1] ""  Vector__XXX
 SG_ FT_Kisi_re_aktiv : 49|1@1+ (1.0,0.0) [0.0|1] ""  Vector__XXX
 SG_ FT_Kisi_Taster_li : 50|1@1+ (1.0,0.0) [0.0|1] ""  Vector__XXX
 SG_ FT_Kisi_Taster_re : 51|1@1+ (1.0,0.0) [0.0|1] ""  Vector__XXX
 SG_ FT_BFS_Fond_Freigabe : 52|1@1+ (1.0,0.0) [0.0|1] ""  Vector__XXX
 SG_ FT_Kisi_Fehler : 53|1@1+ (1.0,0.0) [0.0|1] ""  Vector__XXX
 SG_ FT_Daemmglas : 54|1@1+ (1.0,0.0) [0.0|1] ""  Vector__XXX
 SG_ FT_SP_Heizung_Status : 55|1@1+ (1.0,0.0) [0.0|1] ""  Vector__XXX
 SG_ ASW_Warnung_aktiv_FS : 56|1@1+ (1.0,0.0) [0.0|1] ""  Vector__XXX
 SG_ FT_FH_Pos_oben : 57|1@1+ (1.0,0.0) [0.0|1] ""  Vector__XXX
 SG_ FT_Tuerschloss_defekt : 58|1@1+ (1.0,0.0) [0.0|1] ""  Vector__XXX
 SG_ FT_SWA_Taster : 59|1@1+ (1.0,0.0) [0.0|1] ""  Vector__XXX
 SG_ SWA_HMI_Diagnose : 60|2@1+ (1.0,0.0) [0.0|3] ""  Vector__XXX
 SG_ FS_Status_eTAG : 62|2@1+ (1.0,0.0) [0.0|3] ""  Vector__XXX

BO_ 975 TSG_HBFS_01: 8 Gateway
 SG_ HBFS_Tuer_geoeffnet : 0|1@1+ (1.0,0.0) [0.0|1] ""  Vector__XXX
 SG_ HBFS_verriegelt : 1|1@1+ (1.0,0.0) [0.0|1] ""  Vector__XXX
 SG_ HBFS_gesafet : 2|1@1+ (1.0,0.0) [0.0|1] ""  Vector__XXX
 SG_ HBFS_Heckrollotaster_betaetigt : 3|1@1+ (1.0,0.0) [0.0|1] ""  Vector__XXX
 SG_ HBFS_Tuerschloss_defekt : 4|1@1+ (1.0,0.0) [0.0|1] ""  Vector__XXX
 SG_ HBFS_Unlock_Taster : 5|1@1+ (1.0,0.0) [0.0|1] ""  Vector__XXX
 SG_ HBFS_Lock_Taster : 6|1@1+ (1.0,0.0) [0.0|1] ""  Vector__XXX
 SG_ HBFS_Sperrklinke : 7|1@1+ (1.0,0.0) [0.0|1] ""  Vector__XXX
 SG_ HBFS_TAG_betaetigt : 8|1@1+ (1.0,0.0) [0.0|1] ""  Vector__XXX
 SG_ HBFS_TIG_betaetigt : 9|1@1+ (1.0,0.0) [0.0|1] ""  Vector__XXX
 SG_ HBFS_FH_S_HFS_AutoHoch : 10|1@1+ (1.0,0.0) [0.0|1] ""  Vector__XXX
 SG_ HBFS_FH_S_HFS_AutoTief : 11|1@1+ (1.0,0.0) [0.0|1] ""  Vector__XXX
 SG_ HBFS_FH_S_HFS_ManHoch : 12|1@1+ (1.0,0.0) [0.0|1] ""  Vector__XXX
 SG_ HBFS_FH_S_HFS_ManTief : 13|1@1+ (1.0,0.0) [0.0|1] ""  Vector__XXX
 SG_ HBFS_Tuer_Status : 14|2@1+ (1.0,0.0) [0.0|3] ""  Vector__XXX
 SG_ HBFS_SAD_Schalter : 16|4@1+ (1.0,0.0) [0.0|15] ""  Vector__XXX
 SG_ HBFS_FH_S_ManHoch : 20|1@1+ (1.0,0.0) [0.0|1] ""  Vector__XXX
 SG_ HBFS_FH_S_AutoHoch : 21|1@1+ (1.0,0.0) [0.0|1] ""  Vector__XXX
 SG_ HBFS_FH_S_ManTief : 22|1@1+ (1.0,0.0) [0.0|1] ""  Vector__XXX
 SG_ HBFS_FH_S_AutoTief : 23|1@1+ (1.0,0.0) [0.0|1] ""  Vector__XXX
 SG_ HBFS_FH_Oeffnung : 24|8@1+ (0.5,0) [0.0|100.0] "Unit_PerCent"  Vector__XXX
 SG_ HBFS_FH_Bew_hoch : 32|1@1+ (1.0,0.0) [0.0|1] ""  Vector__XXX
 SG_ HBFS_FH_Bew_tief : 33|1@1+ (1.0,0.0) [0.0|1] ""  Vector__XXX
 SG_ HBFS_FH_Fang : 34|1@1+ (1.0,0.0) [0.0|1] ""  Vector__XXX
 SG_ HBFS_FH_Block : 35|1@1+ (1.0,0.0) [0.0|1] ""  Vector__XXX
 SG_ HBFS_FH_Thermo : 36|1@1+ (1.0,0.0) [0.0|1] ""  Vector__XXX
 SG_ HBFS_UEKB_aktiviert : 37|1@1+ (1.0,0.0) [0.0|1] ""  Vector__XXX
 SG_ HBFS_Tueroeffnen_Warnung : 38|1@1+ (1.0,0.0) [0.0|1] ""  Vector__XXX
 SG_ HBFS_FH_normiert : 39|1@1+ (1.0,0.0) [0.0|1] ""  Vector__XXX
 SG_ ASW_Warnung_aktiv_HBFS : 40|1@1+ (1.0,0.0) [0.0|1] ""  Vector__XXX
 SG_ HBFS_Zuziehhilfe_aktiv : 41|1@1+ (1.0,0.0) [0.0|1] ""  Vector__XXX
 SG_ HBFS_Seitenrollo_hoch : 42|1@1+ (1.0,0.0) [0.0|1] ""  TME
 SG_ HBFS_Seitenrollo_tief : 43|1@1+ (1.0,0.0) [0.0|1] ""  TME
 SG_ HBFS_Status_KiSi : 44|1@1+ (1.0,0.0) [0.0|1] ""  Vector__XXX
 SG_ SSR_HBFS_Pos_Unten : 45|1@1+ (1.0,0.0) [0.0|1] ""  Vector__XXX
 SG_ HBFS_Oben_Block_erw : 46|1@1+ (1.0,0.0) [0.0|1] ""  Vector__XXX
 SG_ HBFS_Unten_Block_erw : 47|1@1+ (1.0,0.0) [0.0|1] ""  Vector__XXX
 SG_ MTHBFS_M_Taste : 48|1@1+ (1.0,0.0) [0.0|1] ""  Vector__XXX
 SG_ MTHBFS_Pos1 : 49|1@1+ (1.0,0.0) [0.0|1] ""  Vector__XXX
 SG_ MTHBFS_Pos2 : 50|1@1+ (1.0,0.0) [0.0|1] ""  Vector__XXX
 SG_ MTHBFS_Pos3 : 51|1@1+ (1.0,0.0) [0.0|1] ""  Vector__XXX
 SG_ HBFS_MRollo_Schalter : 52|3@1+ (1.0,0.0) [0.0|7] ""  Vector__XXX
 SG_ HBFS_Lock_Taster_inv : 55|1@1+ (1.0,0.0) [0.0|1] ""  Vector__XXX
 SG_ HBFS_Status_KiSi_inv : 56|1@1+ (1.0,0.0) [0.0|1] ""  Vector__XXX
 SG_ HBFS_Status_eTAG : 57|2@1+ (1.0,0.0) [0.0|3] ""  Vector__XXX
 SG_ HBFS_Tuer_Status_QBit : 59|1@1+ (1.0,0.0) [0.0|1] ""  Vector__XXX
 SG_ HBFS_TIG_betaetigt_schliessen : 60|1@1+ (1.0,0.0) [0.0|1] ""  Vector__XXX

BO_ 974 TSG_HFS_01: 8 Gateway
 SG_ HFS_Tuer_geoeffnet : 0|1@1+ (1.0,0.0) [0.0|1] ""  Vector__XXX
 SG_ HFS_verriegelt : 1|1@1+ (1.0,0.0) [0.0|1] ""  Vector__XXX
 SG_ HFS_gesafet : 2|1@1+ (1.0,0.0) [0.0|1] ""  Vector__XXX
 SG_ HFS_Heckrollotaster_betaetigt : 3|1@1+ (1.0,0.0) [0.0|1] ""  Vector__XXX
 SG_ HFS_Tuerschloss_defekt : 4|1@1+ (1.0,0.0) [0.0|1] ""  Vector__XXX
 SG_ HFS_Unlock_Taster : 5|1@1+ (1.0,0.0) [0.0|1] ""  Vector__XXX
 SG_ HFS_Lock_Taster : 6|1@1+ (1.0,0.0) [0.0|1] ""  Vector__XXX
 SG_ HFS_Sperrklinke : 7|1@1+ (1.0,0.0) [0.0|1] ""  Vector__XXX
 SG_ HFS_TAG_betaetigt : 8|1@1+ (1.0,0.0) [0.0|1] ""  Vector__XXX
 SG_ HFS_TIG_betaetigt : 9|1@1+ (1.0,0.0) [0.0|1] ""  Vector__XXX
 SG_ HFS_FH_S_HBFS_AutoHoch : 10|1@1+ (1.0,0.0) [0.0|1] ""  Vector__XXX
 SG_ HFS_FH_S_HBFS_AutoTief : 11|1@1+ (1.0,0.0) [0.0|1] ""  Vector__XXX
 SG_ HFS_FH_S_HBFS_ManHoch : 12|1@1+ (1.0,0.0) [0.0|1] ""  Vector__XXX
 SG_ HFS_FH_S_HBFS_ManTief : 13|1@1+ (1.0,0.0) [0.0|1] ""  Vector__XXX
 SG_ HFS_Tuer_Status : 14|2@1+ (1.0,0.0) [0.0|3] ""  Vector__XXX
 SG_ HFS_SAD_Schalter : 16|4@1+ (1.0,0.0) [0.0|15] ""  Vector__XXX
 SG_ HFS_FH_S_ManHoch : 20|1@1+ (1.0,0.0) [0.0|1] ""  Vector__XXX
 SG_ HFS_FH_S_AutoHoch : 21|1@1+ (1.0,0.0) [0.0|1] ""  Vector__XXX
 SG_ HFS_FH_S_ManTief : 22|1@1+ (1.0,0.0) [0.0|1] ""  Vector__XXX
 SG_ HFS_FH_S_AutoTief : 23|1@1+ (1.0,0.0) [0.0|1] ""  Vector__XXX
 SG_ HFS_FH_Oeffnung : 24|8@1+ (0.5,0) [0.0|100.0] "Unit_PerCent"  Vector__XXX
 SG_ HFS_FH_Bew_hoch : 32|1@1+ (1.0,0.0) [0.0|1] ""  Vector__XXX
 SG_ HFS_FH_Bew_tief : 33|1@1+ (1.0,0.0) [0.0|1] ""  Vector__XXX
 SG_ HFS_FH_Fang : 34|1@1+ (1.0,0.0) [0.0|1] ""  Vector__XXX
 SG_ HFS_FH_Block : 35|1@1+ (1.0,0.0) [0.0|1] ""  Vector__XXX
 SG_ HFS_FH_Thermo : 36|1@1+ (1.0,0.0) [0.0|1] ""  Vector__XXX
 SG_ HFS_UEKB_aktiviert : 37|1@1+ (1.0,0.0) [0.0|1] ""  Vector__XXX
 SG_ HFS_Tueroeffnen_Warnung : 38|1@1+ (1.0,0.0) [0.0|1] ""  Vector__XXX
 SG_ HFS_FH_normiert : 39|1@1+ (1.0,0.0) [0.0|1] ""  Vector__XXX
 SG_ ASW_Warnung_aktiv_HFS : 40|1@1+ (1.0,0.0) [0.0|1] ""  Vector__XXX
 SG_ HFS_Zuziehhilfe_aktiv : 41|1@1+ (1.0,0.0) [0.0|1] ""  Vector__XXX
 SG_ HFS_Seitenrollo_hoch : 42|1@1+ (1.0,0.0) [0.0|1] ""  TME
 SG_ HFS_Seitenrollo_tief : 43|1@1+ (1.0,0.0) [0.0|1] ""  TME
 SG_ HFS_Status_KiSi : 44|1@1+ (1.0,0.0) [0.0|1] ""  Vector__XXX
 SG_ SSR_HFS_Pos_Unten : 45|1@1+ (1.0,0.0) [0.0|1] ""  Vector__XXX
 SG_ HFS_Oben_Block_erw : 46|1@1+ (1.0,0.0) [0.0|1] ""  Vector__XXX
 SG_ HFS_Unten_Block_erw : 47|1@1+ (1.0,0.0) [0.0|1] ""  Vector__XXX
 SG_ MTHFS_M_Taste : 48|1@1+ (1.0,0.0) [0.0|1] ""  Vector__XXX
 SG_ MTHFS_Pos1 : 49|1@1+ (1.0,0.0) [0.0|1] ""  Vector__XXX
 SG_ MTHFS_Pos2 : 50|1@1+ (1.0,0.0) [0.0|1] ""  Vector__XXX
 SG_ MTHFS_Pos3 : 51|1@1+ (1.0,0.0) [0.0|1] ""  Vector__XXX
 SG_ HFS_MRollo_Schalter : 52|3@1+ (1.0,0.0) [0.0|7] ""  Vector__XXX
 SG_ HFS_Lock_Taster_inv : 55|1@1+ (1.0,0.0) [0.0|1] ""  Vector__XXX
 SG_ HFS_Status_eTAG : 56|2@1+ (1.0,0.0) [0.0|3] ""  Vector__XXX
 SG_ HFS_Tuer_Status_QBit : 58|1@1+ (1.0,0.0) [0.0|1] ""  Vector__XXX
 SG_ HFS_TCR_Mode_aktiv : 59|1@1+ (1.0,0.0) [0.0|1] ""  Vector__XXX

BO_ 995 Verdeck_01: 8 Gateway
 SG_ Verdeck_01_CRC : 0|8@1+ (1,0) [0|255] ""  Vector__XXX
 SG_ Verdeck_01_BZ : 8|4@1+ (1,0) [0|15] ""  Vector__XXX
 SG_ VS_VD_zu_ver : 16|1@1+ (1.0,0.0) [0.0|1] ""  TME
 SG_ VS_VD_entriegelt : 17|1@1+ (1.0,0.0) [0.0|1] ""  Vector__XXX
 SG_ VS_VD_offen_ver : 18|1@1+ (1.0,0.0) [0.0|1] ""  Vector__XXX
 SG_ VS_VD_Zwischenposition : 19|1@1+ (1.0,0.0) [0.0|1] ""  Vector__XXX
 SG_ VS_VD_Bew_auf : 20|1@1+ (1.0,0.0) [0.0|1] ""  Vector__XXX
 SG_ VS_VD_Bew_zu : 21|1@1+ (1.0,0.0) [0.0|1] ""  Vector__XXX
 SG_ VS_Verdeck_Anf : 22|1@1+ (1.0,0.0) [0.0|1] ""  Vector__XXX
 SG_ VS_Hardtop : 23|1@1+ (1.0,0.0) [0.0|1] ""  Vector__XXX
 SG_ VS_VD_Fehler : 24|1@1+ (1.0,0.0) [0.0|1] ""  Vector__XXX
 SG_ VS_Lampe_Blk : 25|1@1+ (1.0,0.0) [0.0|1] ""  Vector__XXX
 SG_ VS_Buzzer : 26|1@1+ (1.0,0.0) [0.0|1] ""  Vector__XXX
 SG_ VS_HD_sperren : 27|1@1+ (1.0,0.0) [0.0|1] ""  Vector__XXX
 SG_ VS_HHS_enable : 28|1@1+ (1.0,0.0) [0.0|1] ""  Vector__XXX
 SG_ VD_SpannungsAnf : 29|2@1+ (1.0,0.0) [0.0|3] ""  Vector__XXX
 SG_ VS_VDKD_auf : 31|1@1+ (1.0,0.0) [0.0|1] ""  Vector__XXX
 SG_ VS_FS_AutoHoch : 32|1@1+ (1.0,0.0) [0.0|1] ""  Vector__XXX
 SG_ VS_FS_AutoTief : 33|1@1+ (1.0,0.0) [0.0|1] ""  Vector__XXX
 SG_ VS_FS_ManHoch : 34|1@1+ (1.0,0.0) [0.0|1] ""  Vector__XXX
 SG_ VS_FS_ManTief : 35|1@1+ (1.0,0.0) [0.0|1] ""  Vector__XXX
 SG_ VS_BFS_AutoHoch : 36|1@1+ (1.0,0.0) [0.0|1] ""  Vector__XXX
 SG_ VS_BFS_AutoTief : 37|1@1+ (1.0,0.0) [0.0|1] ""  Vector__XXX
 SG_ VS_BFS_ManHoch : 38|1@1+ (1.0,0.0) [0.0|1] ""  Vector__XXX
 SG_ VS_BFS_ManTief : 39|1@1+ (1.0,0.0) [0.0|1] ""  Vector__XXX
 SG_ VS_HFS_AutoHoch : 40|1@1+ (1.0,0.0) [0.0|1] ""  Vector__XXX
 SG_ VS_HFS_AutoTief : 41|1@1+ (1.0,0.0) [0.0|1] ""  Vector__XXX
 SG_ VS_HFS_ManHoch : 42|1@1+ (1.0,0.0) [0.0|1] ""  Vector__XXX
 SG_ VS_HFS_ManTief : 43|1@1+ (1.0,0.0) [0.0|1] ""  Vector__XXX
 SG_ VS_HBFS_AutoHoch : 44|1@1+ (1.0,0.0) [0.0|1] ""  Vector__XXX
 SG_ VS_HBFS_AutoTief : 45|1@1+ (1.0,0.0) [0.0|1] ""  Vector__XXX
 SG_ VS_HBFS_ManHoch : 46|1@1+ (1.0,0.0) [0.0|1] ""  Vector__XXX
 SG_ VS_HBFS_ManTief : 47|1@1+ (1.0,0.0) [0.0|1] ""  Vector__XXX
 SG_ VS_FH_FT_Langhub : 49|1@1+ (1.0,0.0) [0.0|1] ""  Vector__XXX
 SG_ VS_Windschott_nicht_abgelegt : 50|1@1+ (1.0,0.0) [0.0|1] ""  Vector__XXX
 SG_ VS_FH_BT_Langhub : 51|1@1+ (1.0,0.0) [0.0|1] ""  Vector__XXX
 SG_ VS_FH_HFS_Langhub : 53|1@1+ (1.0,0.0) [0.0|1] ""  Vector__XXX
 SG_ VS_Heckschloss_auf : 54|1@1+ (1.0,0.0) [0.0|1] ""  Vector__XXX
 SG_ VS_FH_HBFS_Langhub : 55|1@1+ (1.0,0.0) [0.0|1] ""  Vector__XXX
 SG_ VSG_Meldungen : 56|6@1+ (1,0) [1|63] "Unit_None"  Vector__XXX
 SG_ VS_StartStopp_Info : 62|2@1+ (1.0,0.0) [0.0|3] ""  Vector__XXX

BO_ 1716 VIN_01: 8 Gateway
 SG_ VIN_01_MUX M  : 0|2@1+ (1,0) [0|3] ""  Ladegeraet_Konzern,Sub_Gateway,TME
 SG_ KS_Geheimnis_1 m0  : 8|8@1+ (1,0) [0|255] ""  Sub_Gateway
 SG_ VIN_4 m1  : 8|8@1+ (1,0) [0|255] ""  Ladegeraet_Konzern,Sub_Gateway,TME
 SG_ VIN_11 m2  : 8|8@1+ (1,0) [0|255] ""  Ladegeraet_Konzern,Sub_Gateway,TME
 SG_ KS_Geheimnis_2 m0  : 16|8@1+ (1,0) [0|255] ""  Sub_Gateway
 SG_ VIN_5 m1  : 16|8@1+ (1,0) [0|255] ""  Ladegeraet_Konzern,Sub_Gateway,TME
 SG_ VIN_12 m2  : 16|8@1+ (1,0) [0|255] ""  Ladegeraet_Konzern,Sub_Gateway,TME
 SG_ KS_Geheimnis_3 m0  : 24|8@1+ (1,0) [0|255] ""  Sub_Gateway
 SG_ VIN_6 m1  : 24|8@1+ (1,0) [0|255] ""  Ladegeraet_Konzern,Sub_Gateway,TME
 SG_ VIN_13 m2  : 24|8@1+ (1,0) [0|255] ""  Ladegeraet_Konzern,Sub_Gateway,TME
 SG_ KS_Geheimnis_4 m0  : 32|8@1+ (1,0) [0|255] ""  Sub_Gateway
 SG_ VIN_7 m1  : 32|8@1+ (1,0) [0|255] ""  Ladegeraet_Konzern,Sub_Gateway,TME
 SG_ VIN_14 m2  : 32|8@1+ (1,0) [0|255] ""  Ladegeraet_Konzern,Sub_Gateway,TME
 SG_ VIN_1 m0  : 40|8@1+ (1,0) [0|255] ""  Ladegeraet_Konzern,Sub_Gateway,TME
 SG_ VIN_8 m1  : 40|8@1+ (1,0) [0|255] ""  Ladegeraet_Konzern,Sub_Gateway,TME
 SG_ VIN_15 m2  : 40|8@1+ (1,0) [0|255] ""  Ladegeraet_Konzern,Sub_Gateway,TME
 SG_ VIN_2 m0  : 48|8@1+ (1,0) [0|255] ""  Ladegeraet_Konzern,Sub_Gateway,TME
 SG_ VIN_9 m1  : 48|8@1+ (1,0) [0|255] ""  Ladegeraet_Konzern,Sub_Gateway,TME
 SG_ VIN_16 m2  : 48|8@1+ (1,0) [0|255] ""  Ladegeraet_Konzern,Sub_Gateway,TME
 SG_ VIN_3 m0  : 56|8@1+ (1,0) [0|255] ""  Ladegeraet_Konzern,Sub_Gateway,TME
 SG_ VIN_10 m1  : 56|8@1+ (1,0) [0|255] ""  Ladegeraet_Konzern,Sub_Gateway,TME
 SG_ VIN_17 m2  : 56|8@1+ (1,0) [0|255] ""  Ladegeraet_Konzern,Sub_Gateway,TME

BO_ 916 WBA_03: 8 Gateway
 SG_ WBA_03_CRC : 0|8@1+ (1,0) [0|255] ""  Sub_Gateway
 SG_ WBA_03_BZ : 8|4@1+ (1,0) [0|15] ""  Sub_Gateway
 SG_ WBA_Fahrstufe_02 : 12|4@1+ (1.0,0.0) [0.0|15] ""  Sub_Gateway
 SG_ WBA_ZielFahrstufe : 16|4@1+ (1.0,0.0) [0.0|15] ""  Sub_Gateway
 SG_ WBA_GE_Warnung_02 : 20|4@1+ (1.0,0.0) [0.0|15] ""  Sub_Gateway
 SG_ WBA_eing_Gang_02 : 24|4@1+ (1.0,0.0) [0.0|15] ""  Sub_Gateway
 SG_ WBA_GE_Texte : 28|3@1+ (1.0,0.0) [0.0|7] ""  Sub_Gateway
 SG_ WBA_Segeln_aktiv : 31|1@1+ (1.0,0.0) [0.0|1] ""  Sub_Gateway
 SG_ WBA_Schaltschema : 32|5@1+ (1.0,0.0) [0.0|31] ""  Sub_Gateway
 SG_ WBA_GE_Zusatzwarnungen : 37|3@1+ (1.0,0.0) [0.0|7] ""  Sub_Gateway
 SG_ GE_Sollgang : 40|4@1+ (1.0,0.0) [0.0|15] ""  Sub_Gateway
 SG_ GE_Tipschaltempf_verfuegbar : 44|1@1+ (1.0,0.0) [0.0|1] ""  Sub_Gateway
 SG_ WBA_GE_Texte_02 : 45|3@1+ (1.0,0.0) [0.0|7] ""  Sub_Gateway
 SG_ WBA_GE_Texte_03 : 48|4@1+ (1.0,0.0) [0.0|15] ""  Sub_Gateway
 SG_ WBA_Blinken : 54|1@1+ (1.0,0.0) [0.0|1] ""  Sub_Gateway
 SG_ GE_Wiederstart_Anz_Std : 55|1@1+ (1.0,0.0) [0.0|1] ""  Sub_Gateway
 SG_ GE_Stoppverbot_Anz_01 : 56|1@1+ (1.0,0.0) [0.0|1] ""  Sub_Gateway
 SG_ GE_Stoppverbot_Anz_02 : 57|1@1+ (1.0,0.0) [0.0|1] ""  Sub_Gateway
 SG_ GE_Stoppverbot_Anz_03 : 58|1@1+ (1.0,0.0) [0.0|1] ""  Sub_Gateway
 SG_ GE_Stoppverbot_Anz_04 : 59|1@1+ (1.0,0.0) [0.0|1] ""  Sub_Gateway
 SG_ GE_Stoppverbot_Anz_05 : 60|1@1+ (1.0,0.0) [0.0|1] ""  Sub_Gateway
 SG_ GE_Stoppverbot_Anz_06 : 61|1@1+ (1.0,0.0) [0.0|1] ""  Sub_Gateway
 SG_ GE_Stoppverbot_Anz_07 : 62|1@1+ (1.0,0.0) [0.0|1] ""  Sub_Gateway
 SG_ GE_Stoppverbot_Anz_Std : 63|1@1+ (1.0,0.0) [0.0|1] ""  Sub_Gateway

BO_ 1702 Wischer_01: 8 Gateway
 SG_ Wischer_vorne_aktiv : 0|1@1+ (1.0,0.0) [0.0|1] ""  TME
 SG_ Waschen_vorne_aktiv : 1|1@1+ (1.0,0.0) [0.0|1] ""  TME
 SG_ Wischer_vorne_Normal : 2|1@1+ (1.0,0.0) [0.0|1] ""  Vector__XXX
 SG_ Wischer_vorne_Schnell : 3|1@1+ (1.0,0.0) [0.0|1] ""  Vector__XXX
 SG_ Wischer_vorne_Parklage : 4|1@1+ (1.0,0.0) [0.0|1] ""  Vector__XXX
 SG_ Wischer_vorne_defekt : 6|1@1+ (1.0,0.0) [0.0|1] ""  Vector__XXX
 SG_ Wischer_vorne_blockiert : 7|1@1+ (1.0,0.0) [0.0|1] ""  Vector__XXX
 SG_ Wischer1_Wischgeschwindigkeit : 8|6@1+ (1,9) [10|70] "Unit_MinutInver"  Vector__XXX
 SG_ BCM1_SRA_aktiv : 14|1@1+ (1.0,0.0) [0.0|1] ""  Vector__XXX
 SG_ Heckwischer_Anforderung : 16|1@1+ (1.0,0.0) [0.0|1] ""  Vector__XXX
 SG_ WWSs_01_upd : 17|1@1+ (1.0,0.0) [0.0|1] ""  Vector__XXX
 SG_ Wischer_Anzeigetext : 18|2@1+ (1.0,0.0) [0.0|3] ""  Vector__XXX

BO_ 2617079552 XCP_BattRegelung_CRO_01: 8 Vector__XXX
 SG_ XCP_BattRegelung_CRO_01_Data : 0|64@1+ (1,0) [0|1] ""  BMS_NV

BO_ 2617079553 XCP_BattRegelung_DTO_01: 8 BMS_NV
 SG_ XCP_BattRegelung_DTO_01_Data : 0|64@1+ (1,0) [0|1] ""  Vector__XXX

BO_ 2566705152 XCP_BJB_CRO_01: 8 Vector__XXX
 SG_ XCP_BJB_CRO_01_Data : 0|64@1+ (1.0,0.0) [0.0|18446744073709551615] ""  BMC_MLBevo

BO_ 2566705153 XCP_BJB_DTO_01: 8 BMC_MLBevo
 SG_ XCP_BJB_DTO_01_Data : 0|64@1+ (1.0,0.0) [0.0|18446744073709551615] ""  Vector__XXX

BO_ 2617042688 XCP_BMS_MV_CRO_01: 8 Vector__XXX
 SG_ XCP_BMS_MV_CRO_01_Data : 0|64@1+ (1,0) [0|1] ""  BMS_MV

BO_ 2617042689 XCP_BMS_MV_DTO_01: 8 BMS_MV
 SG_ XCP_BMS_MV_DTO_01_Data : 0|64@1+ (1,0) [0|1] ""  Vector__XXX

BO_ 2617118208 XCP_DCDC_CRO_01: 8 Vector__XXX
 SG_ XCP_DCDC_CRO_01_Data : 0|64@1+ (1.0,0.0) [0.0|18446744073709551615] ""  DCDC_IHEV

BO_ 2617118209 XCP_DCDC_DTO_01: 8 DCDC_IHEV
 SG_ XCP_DCDC_DTO_01_Data : 0|64@1+ (1.0,0.0) [0.0|18446744073709551615] ""  Vector__XXX

BO_ 2617097984 XCP_DCDC_HV_CRO_01: 8 Vector__XXX
 SG_ XCP_DCDC_HV_CRO_01_Data : 0|64@1+ (1.0,0.0) [0.0|18446744073709551615] ""  CBC,DCDC_800V_PAG,DCDC_HV

BO_ 2617097985 XCP_DCDC_HV_DTO_01: 8 CBC
 SG_ XCP_DCDC_HV_DTO_01_Data : 0|64@1+ (1.0,0.0) [0.0|18446744073709551615] ""  Vector__XXX

BO_ 2617093888 XCP_FCU_CRO_01: 8 Vector__XXX
 SG_ XCP_FCU_CRO_01_Data : 0|64@1+ (1.0,0.0) [0.0|18446744073709551615] ""  FCU_MLBevo_FCEV

BO_ 2617093889 XCP_FCU_DTO_01: 8 FCU_MLBevo_FCEV
 SG_ XCP_FCU_DTO_01_Data : 0|64@1+ (1.0,0.0) [0.0|18446744073709551615] ""  Vector__XXX

BO_ 2617120256 XCP_TME_CRO_01: 8 Vector__XXX
 SG_ XCP_TME_CRO_01_Data : 0|64@1+ (1,0) [0|1] ""  TME

BO_ 2617120257 XCP_TME_DTO_01: 8 TME
 SG_ XCP_TME_DTO_01_Data : 0|64@1+ (1,0) [0|1] ""  Vector__XXX

BO_ 1140 Zentralrechner_01: 8 Gateway
 SG_ ZR_State_DU_1 : 0|3@1+ (1.0,0.0) [0.0|7] ""  Vector__XXX
 SG_ ZR_State_DU_2 : 3|3@1+ (1.0,0.0) [0.0|7] ""  Vector__XXX
 SG_ ZR_State_DU_3 : 6|3@1+ (1.0,0.0) [0.0|7] ""  Vector__XXX
 SG_ ZR_WecktGesp : 9|1@1+ (1.0,0.0) [0.0|1] ""  Vector__XXX
 SG_ MMI_State : 10|6@1+ (1.0,0.0) [0.0|63] ""  Vector__XXX
 SG_ ZR_DimOffs_DU_1 : 16|4@1+ (1,-5) [-5|5] "Unit_None"  Vector__XXX
 SG_ ZR_DimOffs_DU_2 : 20|4@1+ (1,-5) [-5|5] "Unit_None"  Vector__XXX
 SG_ ZR_DimOffs_DU_3 : 24|4@1+ (1,-5) [-5|5] "Unit_None"  Vector__XXX
 SG_ SI_ICAN : 28|1@1+ (1.0,0.0) [0.0|1] ""  Vector__XXX
 SG_ ZR_Lenkerposition : 29|1@1+ (1.0,0.0) [0.0|1] ""  Vector__XXX
 SG_ WLC1_Systemzustand : 30|1@1+ (1.0,0.0) [0.0|1] ""  Vector__XXX
 SG_ WLC2_Systemzustand : 31|1@1+ (1.0,0.0) [0.0|1] ""  Vector__XXX
 SG_ ZR_SpannungSaeule : 35|1@1+ (1.0,0.0) [0.0|1] ""  TME
 SG_ ZR_LeistungSaeule : 36|2@1+ (1.0,0.0) [0.0|3] ""  TME
 SG_ ZR_SOCSaeule : 41|7@1+ (1,0) [0|100] "Unit_PerCent"  TME
 SG_ ZR_State_DU_4 : 48|3@1+ (1.0,0.0) [0.0|7] ""  Vector__XXX
 SG_ ZR_DimOffs_DU_4 : 51|4@1+ (1,-5) [-5|5] "Unit_None"  Vector__XXX
 SG_ ZR_t_naechsteLadung : 56|8@1+ (1,0) [0|255] "Unit_Minut"  TME

BO_ 2527679655 Zentralrechner_03: 8 Gateway
 SG_ ZR_SOC_Weiterfahrt : 51|7@1+ (1,0) [0|100] "Unit_PerCent"  TME
 SG_ MMI_StartupAnimation : 61|3@1+ (1.0,0.0) [0.0|7] ""  Vector__XXX

BO_ 388 ZV_01: 8 Gateway
 SG_ ZV_01_CRC : 0|8@1+ (1,0) [0|255] ""  Vector__XXX
 SG_ ZV_01_BZ : 8|4@1+ (1,0) [0|15] ""  Vector__XXX
 SG_ ZV_FT_verriegeln : 12|1@1+ (1.0,0.0) [0.0|1] ""  Ladegeraet_Konzern
 SG_ ZV_FT_entriegeln : 13|1@1+ (1.0,0.0) [0.0|1] ""  FCU_MLBevo_FCEV,Ladegeraet_Konzern
 SG_ ZV_BT_verriegeln : 14|1@1+ (1.0,0.0) [0.0|1] ""  Ladegeraet_Konzern
 SG_ ZV_BT_entriegeln : 15|1@1+ (1.0,0.0) [0.0|1] ""  Ladegeraet_Konzern
 SG_ ZV_HFS_verriegeln : 16|1@1+ (1.0,0.0) [0.0|1] ""  Vector__XXX
 SG_ ZV_HFS_entriegeln : 17|1@1+ (1.0,0.0) [0.0|1] ""  Vector__XXX
 SG_ ZV_HBFS_verriegeln : 18|1@1+ (1.0,0.0) [0.0|1] ""  Vector__XXX
 SG_ ZV_HBFS_entriegeln : 19|1@1+ (1.0,0.0) [0.0|1] ""  Vector__XXX
 SG_ ZV_zentral_safen : 20|1@1+ (1.0,0.0) [0.0|1] ""  Vector__XXX
 SG_ ZV_zentral_entsafen : 21|1@1+ (1.0,0.0) [0.0|1] ""  Vector__XXX
 SG_ ZV_Spg_Anklappen : 22|1@1+ (1.0,0.0) [0.0|1] ""  Vector__XXX
 SG_ ZV_Softtouch_betaetigt : 23|1@1+ (1.0,0.0) [0.0|1] ""  Vector__XXX
 SG_ ZV_LED_Steuerung : 24|1@1+ (1.0,0.0) [0.0|1] ""  Vector__XXX
 SG_ ZV_LED_Uebernahme : 25|1@1+ (1.0,0.0) [0.0|1] ""  Vector__XXX
 SG_ ZV_auf_FT : 26|1@1+ (1.0,0.0) [0.0|1] ""  Vector__XXX
 SG_ ZV_zu_FT : 27|1@1+ (1.0,0.0) [0.0|1] ""  Vector__XXX
 SG_ ZV_auf_BT : 28|1@1+ (1.0,0.0) [0.0|1] ""  Vector__XXX
 SG_ ZV_zu_BT : 29|1@1+ (1.0,0.0) [0.0|1] ""  Vector__XXX
 SG_ ZV_auf_Kessy : 30|1@1+ (1.0,0.0) [0.0|1] ""  Vector__XXX
 SG_ ZV_zu_Kessy : 31|1@1+ (1.0,0.0) [0.0|1] ""  Vector__XXX
 SG_ ZV_auf_Funk : 32|1@1+ (1.0,0.0) [0.0|1] ""  Vector__XXX
 SG_ ZV_zu_Funk : 33|1@1+ (1.0,0.0) [0.0|1] ""  Vector__XXX
 SG_ VIP_Sensor_betaetigt : 34|1@1+ (1.0,0.0) [0.0|1] ""  Vector__XXX
 SG_ VIP_Freigabe : 35|1@1+ (1.0,0.0) [0.0|1] ""  Vector__XXX
 SG_ ZV_zu_Zeitl_Nachverr : 36|1@1+ (1.0,0.0) [0.0|1] ""  Vector__XXX
 SG_ ZV_HSK_entriegeln : 37|1@1+ (1.0,0.0) [0.0|1] ""  Vector__XXX
 SG_ ZV_HSK_verriegeln : 38|1@1+ (1.0,0.0) [0.0|1] ""  Vector__XXX
 SG_ ZV_Verdeck_zu : 39|1@1+ (1.0,0.0) [0.0|1] ""  Vector__XXX
 SG_ ZV_Verdeck_auf : 40|1@1+ (1.0,0.0) [0.0|1] ""  Vector__XXX
 SG_ FH_FT_hoch : 41|1@1+ (1.0,0.0) [0.0|1] ""  Vector__XXX
 SG_ FH_FT_tief : 42|1@1+ (1.0,0.0) [0.0|1] ""  Vector__XXX
 SG_ FH_BT_hoch : 43|1@1+ (1.0,0.0) [0.0|1] ""  Vector__XXX
 SG_ FH_BT_tief : 44|1@1+ (1.0,0.0) [0.0|1] ""  Vector__XXX
 SG_ FH_HFS_hoch : 45|1@1+ (1.0,0.0) [0.0|1] ""  Vector__XXX
 SG_ FH_HFS_tief : 46|1@1+ (1.0,0.0) [0.0|1] ""  Vector__XXX
 SG_ FH_HBFS_hoch : 47|1@1+ (1.0,0.0) [0.0|1] ""  Vector__XXX
 SG_ FH_HBFS_tief : 48|1@1+ (1.0,0.0) [0.0|1] ""  Vector__XXX
 SG_ BCM_Spg_Synchron : 49|1@1+ (1.0,0.0) [0.0|1] ""  Vector__XXX
 SG_ BCM_BF_Spg_Absenkung : 50|1@1+ (1.0,0.0) [0.0|1] ""  Vector__XXX
 SG_ ZV_Signatur : 51|11@1+ (1,0) [0|2047] ""  Vector__XXX
 SG_ ZV_entriegeln_Anf : 62|1@1+ (1.0,0.0) [0.0|1] ""  Vector__XXX
 SG_ ZV_auto_Ansteuerung : 63|1@1+ (1.0,0.0) [0.0|1] ""  Vector__XXX

BO_ 1411 ZV_02: 8 Gateway
 SG_ BCM_FH_Freigabe : 12|1@1+ (1.0,0.0) [0.0|1] ""  Vector__XXX
 SG_ BCM_Komfortfkt_Freigabe : 13|1@1+ (1.0,0.0) [0.0|1] ""  Vector__XXX
 SG_ BCM_HSK_Freigabe : 14|1@1+ (1.0,0.0) [0.0|1] ""  Vector__XXX
 SG_ BCM_Verdeck_Freigabe : 15|1@1+ (1.0,0.0) [0.0|1] ""  Vector__XXX
 SG_ ZV_verriegelt_intern_ist : 16|1@1+ (1.0,0.0) [0.0|1] ""  Ladegeraet_Konzern
 SG_ ZV_verriegelt_extern_ist : 17|1@1+ (1.0,0.0) [0.0|1] ""  Ladegeraet_Konzern
 SG_ ZV_verriegelt_intern_soll : 18|1@1+ (1.0,0.0) [0.0|1] ""  Ladegeraet_Konzern
 SG_ ZV_verriegelt_extern_soll : 19|1@1+ (1.0,0.0) [0.0|1] ""  Ladegeraet_Konzern
 SG_ ZV_gesafet_extern_ist : 20|1@1+ (1.0,0.0) [0.0|1] ""  Vector__XXX
 SG_ ZV_gesafet_extern_soll : 21|1@1+ (1.0,0.0) [0.0|1] ""  Vector__XXX
 SG_ ZV_Einzeltuerentriegelung : 22|1@1+ (1.0,0.0) [0.0|1] ""  Vector__XXX
 SG_ ZV_Heckeinzelentriegelung : 23|1@1+ (1.0,0.0) [0.0|1] ""  Vector__XXX
 SG_ ZV_FT_offen : 24|1@1+ (1.0,0.0) [0.0|1] ""  Vector__XXX
 SG_ ZV_BT_offen : 25|1@1+ (1.0,0.0) [0.0|1] ""  Vector__XXX
 SG_ ZV_HFS_offen : 26|1@1+ (1.0,0.0) [0.0|1] ""  Vector__XXX
 SG_ ZV_HBFS_offen : 27|1@1+ (1.0,0.0) [0.0|1] ""  Vector__XXX
 SG_ ZV_HD_offen : 28|1@1+ (1.0,0.0) [0.0|1] ""  Vector__XXX
 SG_ ZV_HS_offen : 29|1@1+ (1.0,0.0) [0.0|1] ""  Vector__XXX
 SG_ IRUE_aktiv : 30|1@1+ (1.0,0.0) [0.0|1] ""  Vector__XXX
 SG_ DWA_aktiv : 31|1@1+ (1.0,0.0) [0.0|1] ""  Vector__XXX
 SG_ HD_Hauptraste : 32|1@1+ (1.0,0.0) [0.0|1] ""  Vector__XXX
 SG_ HD_Vorraste : 33|1@1+ (1.0,0.0) [0.0|1] ""  Vector__XXX
 SG_ FFB_CarFinder : 38|1@1+ (1.0,0.0) [0.0|1] ""  Vector__XXX
 SG_ FFB_Komfortoeffnen : 39|1@1+ (1.0,0.0) [0.0|1] ""  Vector__XXX
 SG_ FFB_Komfortschliessen : 40|1@1+ (1.0,0.0) [0.0|1] ""  Vector__XXX
 SG_ ZV_Schluessel_Zugang : 42|4@1+ (1.0,0.0) [0.0|15] ""  Vector__XXX
 SG_ ZV_SafeFunktion_aktiv : 46|1@1+ (1.0,0.0) [0.0|1] ""  Vector__XXX
 SG_ FBS_Warn_Schluessel_Batt : 47|1@1+ (1.0,0.0) [0.0|1] ""  Vector__XXX
 SG_ ZV_Oeffnungsmodus : 48|2@1+ (1.0,0.0) [0.0|3] ""  Vector__XXX
 SG_ HFS_verriegelt : 50|1@1+ (1.0,0.0) [0.0|1] ""  Vector__XXX
 SG_ HFS_gesafet : 51|1@1+ (1.0,0.0) [0.0|1] ""  Vector__XXX
 SG_ HBFS_verriegelt : 52|1@1+ (1.0,0.0) [0.0|1] ""  Vector__XXX
 SG_ HBFS_gesafet : 53|1@1+ (1.0,0.0) [0.0|1] ""  Vector__XXX
 SG_ ZV_ist_Zustand_verfuegbar : 54|1@1+ (1.0,0.0) [0.0|1] ""  Vector__XXX
 SG_ IRUE_Taster_Fkts_LED : 55|1@1+ (1.0,0.0) [0.0|1] ""  Vector__XXX
 SG_ ZV_Tankklappe_offen : 56|1@1+ (1.0,0.0) [0.0|1] ""  Vector__XXX
 SG_ ZV_Rollo_auf : 57|1@1+ (1.0,0.0) [0.0|1] ""  Vector__XXX
 SG_ ZV_Rollo_zu : 58|1@1+ (1.0,0.0) [0.0|1] ""  Vector__XXX
 SG_ ZV_SAD_auf : 59|1@1+ (1.0,0.0) [0.0|1] ""  Vector__XXX
 SG_ ZV_SAD_zu : 60|1@1+ (1.0,0.0) [0.0|1] ""  Vector__XXX
 SG_ BCM_Tankklappensteller_Fehler : 61|1@1+ (1.0,0.0) [0.0|1] ""  Vector__XXX
 SG_ ZV_verriegelt_soll : 62|2@1+ (1.0,0.0) [0.0|3] ""  Vector__XXX

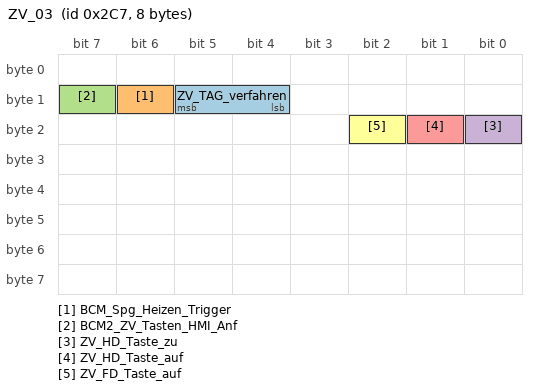
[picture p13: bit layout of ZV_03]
BO_ 711 ZV_03: 8 Gateway
 SG_ ZV_TAG_verfahren : 12|2@1+ (1.0,0.0) [0.0|3] ""  Vector__XXX
 SG_ BCM_Spg_Heizen_Trigger : 14|1@1+ (1.0,0.0) [0.0|1] ""  Vector__XXX
 SG_ BCM2_ZV_Tasten_HMI_Anf : 15|1@1+ (1.0,0.0) [0.0|1] ""  Ladegeraet_Konzern
 SG_ ZV_HD_Taste_zu : 16|1@1+ (1.0,0.0) [0.0|1] ""  Vector__XXX
 SG_ ZV_HD_Taste_auf : 17|1@1+ (1.0,0.0) [0.0|1] ""  Vector__XXX
 SG_ ZV_FD_Taste_auf : 18|1@1+ (1.0,0.0) [0.0|1] ""  Vector__XXX

BO_TX_BU_ 2549903573 :Gateway,Gateway_PAG;
BO_TX_BU_ 2549903574 :Gateway,Gateway_PAG;
BO_TX_BU_ 2549903575 :Gateway,Gateway_PAG;
BO_TX_BU_ 2549903576 :Gateway,Gateway_PAG;
BO_TX_BU_ 2549903577 :Gateway,Gateway_PAG;
BO_TX_BU_ 2549903578 :Gateway,Gateway_PAG;
BO_TX_BU_ 2549903579 :Gateway,Gateway_PAG;
BO_TX_BU_ 2549903580 :Gateway,Gateway_PAG;
BO_TX_BU_ 2549903601 :Gateway,Gateway_PAG;
BO_TX_BU_ 2549903602 :Gateway,Gateway_PAG;
BO_TX_BU_ 2549903603 :Gateway,Gateway_PAG;
BO_TX_BU_ 2549875266 :Gateway,Gateway_PAG;
BO_TX_BU_ 2589283656 :Gateway,Gateway_PAG;
BO_TX_BU_ 872 :Gateway,Gateway_PAG;
BO_TX_BU_ 2463978617 :Gateway,Gateway_PAG;
BO_TX_BU_ 1175 :Gateway,Gateway_PAG;
BO_TX_BU_ 1355 :Gateway,Gateway_PAG;
BO_TX_BU_ 617 :Gateway,Gateway_PAG;
BO_TX_BU_ 2550007876 :Gateway,Gateway_PAG;
BO_TX_BU_ 1616 :Gateway,Gateway_PAG;
BO_TX_BU_ 1525 :Gateway,Gateway_PAG;
BO_TX_BU_ 1527 :Gateway,Gateway_PAG;
BO_TX_BU_ 1126 :Gateway,Gateway_PAG;
BO_TX_BU_ 2527679792 :Gateway,Gateway_PAG;
BO_TX_BU_ 1313 :Gateway,Gateway_PAG;
BO_TX_BU_ 505 :Gateway,Gateway_PAG;
BO_TX_BU_ 1413 :Gateway,Gateway_PAG;
BO_TX_BU_ 977 :Gateway,Gateway_PAG;
BO_TX_BU_ 976 :Gateway,Gateway_PAG;
BO_TX_BU_ 975 :Gateway,Gateway_PAG;
BO_TX_BU_ 974 :Gateway,Gateway_PAG;
BO_TX_BU_ 995 :Gateway,Gateway_PAG;
BO_TX_BU_ 1716 :Gateway,Gateway_PAG;
BO_TX_BU_ 916 :Gateway,Gateway_PAG;
BO_TX_BU_ 1702 :Gateway,Gateway_PAG;
BO_TX_BU_ 2617097985 :CBC,DCDC_800V_PAG,DCDC_HV;
BO_TX_BU_ 1140 :Gateway,Gateway_PAG;
BO_TX_BU_ 2527679655 :Gateway,Gateway_PAG;
BO_TX_BU_ 388 :Gateway,Gateway_PAG;
BO_TX_BU_ 1411 :Gateway,Gateway_PAG;
BO_TX_BU_ 711 :Gateway,Gateway_PAG;
CM_ BO_ 1175 "neue Struktur ab MQB ohne KD-Fehler";
CM_ BO_ 1355 "neue Struktur ab MQB ohne KD-Fehler";
CM_ BO_ 424 "CAN-Botschaft";
CM_ BO_ 1413 "MQB, MLBevo";
CM_ BO_ 977 "ab MQB 7.05";
CM_ BO_ 976 "ab MQB 7.05";
CM_ BO_ 995 "ab MQB IS5";
CM_ BO_ 1716 "200ms bei D4 und folgende";
CM_ BO_ 916 "ersetzt WBA_02";
CM_ BO_ 1702 "MLBevo";
CM_ BO_ 2566705152 "ab MQB";
CM_ BO_ 2566705153 "ab MQB";

CM_ SG_ 2550034644 OBDC_SSN_CMC_04_Resp_Data "Response FID- zu NA- Kommunikation zw. OnboardDiagnoseClient und DK2F Sub-System-Knoten CMC_01 ... 16";

CM_ SG_ 2549903573 OBDC_SSN_CMC_05_Req_Data "Request FID- zu NA- Kommunikation zw. OnboardDiagnoseClient und DK2F Sub-System-Knoten CMC_01 ... 16";

CM_ SG_ 2550034645 OBDC_SSN_CMC_05_Resp_Data "Response FID- zu NA- Kommunikation zw. OnboardDiagnoseClient und DK2F Sub-System-Knoten CMC_01 ... 16";

CM_ SG_ 2549903574 OBDC_SSN_CMC_06_Req_Data "Request FID- zu NA- Kommunikation zw. OnboardDiagnoseClient und DK2F Sub-System-Knoten CMC_01 ... 16";

CM_ SG_ 2550034646 OBDC_SSN_CMC_06_Resp_Data "Response FID- zu NA- Kommunikation zw. OnboardDiagnoseClient und DK2F Sub-System-Knoten CMC_01 ... 16";

CM_ SG_ 2549903575 OBDC_SSN_CMC_07_Req_Data "Request FID- zu NA- Kommunikation zw. OnboardDiagnoseClient und DK2F Sub-System-Knoten CMC_01 ... 16";

CM_ SG_ 2550034647 OBDC_SSN_CMC_07_Resp_Data "Response FID- zu NA- Kommunikation zw. OnboardDiagnoseClient und DK2F Sub-System-Knoten CMC_01 ... 16";

CM_ SG_ 2549903576 OBDC_SSN_CMC_08_Req_Data "Request FID- zu NA- Kommunikation zw. OnboardDiagnoseClient und DK2F Sub-System-Knoten CMC_01 ... 16";

CM_ SG_ 2550034648 OBDC_SSN_CMC_08_Resp_Data "Response FID- zu NA- Kommunikation zw. OnboardDiagnoseClient und DK2F Sub-System-Knoten CMC_01 ... 16";

CM_ SG_ 2549903577 OBDC_SSN_CMC_09_Req_Data "Request FID- zu NA- Kommunikation zw. OnboardDiagnoseClient und DK2F Sub-System-Knoten CMC_01 ... 16";

CM_ SG_ 2550034649 OBDC_SSN_CMC_09_Resp_Data "Response FID- zu NA- Kommunikation zw. OnboardDiagnoseClient und DK2F Sub-System-Knoten CMC_01 ... 16";

CM_ SG_ 2549903578 OBDC_SSN_CMC_10_Req_Data "Request FID- zu NA- Kommunikation zw. OnboardDiagnoseClient und DK2F Sub-System-Knoten CMC_01 ... 16";

CM_ SG_ 2550034650 OBDC_SSN_CMC_10_Resp_Data "Response FID- zu NA- Kommunikation zw. OnboardDiagnoseClient und DK2F Sub-System-Knoten CMC_01 ... 16";

CM_ SG_ 2549903579 OBDC_SSN_CMC_11_Req_Data "Request FID- zu NA- Kommunikation zw. OnboardDiagnoseClient und DK2F Sub-System-Knoten CMC_01 ... 16";

CM_ SG_ 2550034651 OBDC_SSN_CMC_11_Resp_Data "Response FID- zu NA- Kommunikation zw. OnboardDiagnoseClient und DK2F Sub-System-Knoten CMC_01 ... 16";

CM_ SG_ 2549903580 OBDC_SSN_CMC_12_Req_Data "Request FID- zu NA- Kommunikation zw. OnboardDiagnoseClient und DK2F Sub-System-Knoten CMC_01 ... 16";

CM_ SG_ 2550034652 OBDC_SSN_CMC_12_Resp_Data "Response FID- zu NA- Kommunikation zw. OnboardDiagnoseClient und DK2F Sub-System-Knoten CMC_01 ... 16";

CM_ SG_ 2549903601 OBDC_SSN_CMC_13_Req_Data "Request FID- zu NA- Kommunikation zw. OnboardDiagnoseClient und DK2F Sub-System-Knoten CMC_01 ... 16";

CM_ SG_ 2550034673 OBDC_SSN_CMC_13_Resp_Data "Response FID- zu NA- Kommunikation zw. OnboardDiagnoseClient und DK2F Sub-System-Knoten CMC_01 ... 16";

CM_ SG_ 2549903602 OBDC_SSN_CMC_14_Req_Data "Request FID- zu NA- Kommunikation zw. OnboardDiagnoseClient und DK2F Sub-System-Knoten CMC_01 ... 16";

CM_ SG_ 2550034674 OBDC_SSN_CMC_14_Resp_Data "Response FID- zu NA- Kommunikation zw. OnboardDiagnoseClient und DK2F Sub-System-Knoten CMC_01 ... 16";

CM_ SG_ 2549903603 OBDC_SSN_CMC_15_Req_Data "Request FID- zu NA- Kommunikation zw. OnboardDiagnoseClient und DK2F Sub-System-Knoten CMC_01 ... 16";

CM_ SG_ 2550034675 OBDC_SSN_CMC_15_Resp_Data "Response FID- zu NA- Kommunikation zw. OnboardDiagnoseClient und DK2F Sub-System-Knoten CMC_01 ... 16";

CM_ SG_ 2549875380 OBDC_TelemetrieSG_Req_Data "OnBoard Tester Diagnose Request TelemetrieSG";

CM_ SG_ 2550006452 OBDC_TelemetrieSG_Resp_Data "TP-Kanal für den Onboard Datensammler";

CM_ SG_ 2589283656 ORU_Status "Verteilung des internen ORU Zustandes";
CM_ SG_ 2589283656 ORU_Warnung "Wenn durch Störungen der Funktion Online Remote Update nicht sichergestellt ist, dass vor Kunde keine Funktionseinschränkungen auftreten, muss der Benutzer des Fahrzeugs entsprechend gewarnt werden.";

CM_ SG_ 872 PDC2_Tonausgabe_Front "In Abhängigkeit der Systemaktivitäten werden unterschiedliche Tonwarnungen ausgegeben. 
Kombi spielt entsprechende WAV.-Datei über internen Audiomaster ab.

0 = kein Ton
1 = Intervallton 1
2 = Intervallton 2
3 = Intervallton 3
4 = Intervallton 4
5";
CM_ SG_ 872 PDC2_Tonausgabe_Heck "In Abhängigkeit der Systemaktivitäten werden unterschiedliche Tonwarnungen ausgegeben. 
Kombi spielt entsprechende WAV.-Datei über internen Audiomaster ab.

0 = kein Ton
1 = Intervallton 1
2 = Intervallton 2
3 = Intervallton 3
4 = Intervallton 4
5";
CM_ SG_ 872 PH2_Abschaltursache "Abschaltursache bleibt bis zur nächsten Aktivierung bzw. bis KL15 aus gesetzt
Im Fehlerfall (blinkende LED) wird '7' gesendet obwohl das System noch aktiv ist, bei 'geheiltem' Fehler wird sofort wieder der Zustand '0' gesendet";
CM_ SG_ 872 PH2_Anf_Audioabsenkung "Es gibt zwei unterschiedliche Nachlauftimer für dieses Bit:
1. normale Funktion
2. Demotonausgabe";
CM_ SG_ 872 PH2_Anf_Verdeck "Anforderung an ein Verdeck-System, die vom Fahrer angeforderte Öffnung/Schließung zu verhindern";
CM_ SG_ 872 PH2_defekt "Zeigt an das sich die Parkhilfe im Fehlerzustand befindet. Signal bleibt bis zur nächsten 'Gut-Aktivierung' gesetzt.
Spezialfall: Sensordefekt hinten bei Anhängerbetrieb. Anhänger wird abgesteckt Fehler wird gesetzt. Fehlerfall bleibt bis Behebung des De";
CM_ SG_ 872 PH2_Display_Kundenwunsch "Anzeige der bei Aktivierung verwendeten Parameter bzgl. Kundenwunsch Displayanziege. Änderungen werden erst bei erneuter Aktivierung aktualisiert.";
CM_ SG_ 872 PH2_Frequenz_hinten "Uebertragung der aktuell im APS Steuergeraet gespeicherten Werte fuer Tongeber Frequenz hinten
Anzeige der aktuell verwendeten Parameter (nicht zwingend die abgespeicherten - da Werte erst 2s nach der letzten Änderung gespeichert werden!)";
CM_ SG_ 872 PH2_Frequenz_vorn "Uebertragung der aktuell im APS Steuergeraet gespeicherten Werte fuer Tongeber Frequenz vorne
Anzeige der aktuell verwendeten Parameter (nicht zwingend die abgespeicherten - da Werte erst 2s nach der letzten Änderung gespeichert werden!)";
CM_ SG_ 872 PH2_gestoert "Eine Störung ist aufgetreten, der die Parkhilfe in einen 'gestört-Zustand' versetzt, z.B. massiver Fremdultraschall, Vereisung, Schnee.Derzeit nur für Störschall benutzt, da keinerlei andere Erkennung implementiert.";
CM_ SG_ 872 PH2_Lautstaerke_hinten "Uebertragung der aktuell im APS Steuergeraet gespeicherten Werte fuer Tongeber Lautstaerke hinten
Anzeige der aktuell verwendeten Parameter (nicht zwingend die abgespeicherten - da Werte erst 2s nach der letzten Änderung gespeichert werden!)";
CM_ SG_ 872 PH2_Lautstaerke_vorn "Uebertragung der aktuell im APS Steuergeraet gespeicherten Werte fuer Tongeber Lautstaerke vorn.
Anzeige der aktuell verwendeten Parameter (nicht zwingend die abgespeicherten - da Werte erst 2s nach der letzten Änderung gespeichert werden!)";
CM_ SG_ 872 PH2_nachtr_Stopp_An "Dieses Signal dient dem Motor als Trigger, dass ein nachträglicher Motorstopp eingeleitet werden kann, wenn es die Bedingungen des StSt Koordinators dies zulassen. ";
CM_ SG_ 872 PH2_Opt_Anz_H_Hindernis "mindestens 1 Segment wird für den hinteren Detekionsbereich dargestellt, also ein Hindernis ist im Detektionsbereich. Funktion nur bei gesicherter Rückmeldung vom ASG gegeben.";
CM_ SG_ 872 PH2_Opt_Anz_V_Hindernis "mindestens 1 Segment wird für den vorderen Detekionsbereich dargestellt, also ein Hindernis ist im Detektionsbereich. Funktion nur bei gesicherter Rückmeldung vom ASG gegeben.";
CM_ SG_ 872 PH2_Opt_Anzeige_H_ein "OPS hinten ist im Display aktiv bzw. Anzeigemodule hinten sind eingeschaltet. Funktion nur bei gesicherter Rückmeldung vom ASG gegeben.";
CM_ SG_ 872 PH2_Opt_Anzeige_V_ein "OPS vorne ist im Display aktiv bzw. Anzeigemodule vorne sind eingeschaltet. Funktion nur bei gesicherter Rückmeldung vom ASG gegeben.";
CM_ SG_ 872 PH2_StartStopp_Info "Stopp-Freigabe und Start-Anforderung an den Start-Stopp-Koordinator";
CM_ SG_ 872 PH2_Stoermeldung "Meldung einer Störung der PDC an das Kombi";
CM_ SG_ 872 PH2_Systemzustand "Aktivierungsursache wird für die Dauer der Aktivierung gemeldet.
Im Fehlerfall bei atkviem System wechselt das Signal auf '7'
(siehe auch 'Abschaltursache')";
CM_ SG_ 872 PH2_Taster "Taster Status (für RVC/TopView)";
CM_ SG_ 872 PH2_Tongeber_H_aktiv "Rohsignal für 'Tongeber hinten wird angesteuert', verlängerbar mit Nachlauftimer.
Bit wird nicht während des Stellgliedtests angesteuert.";
CM_ SG_ 872 PH2_Tongeber_H_verfuegbar "Tongeber ist für die Tonausgabe für externe Funktionen verfügbar. PDC ist aktiv und Tongeber ist nicht gestört.";
CM_ SG_ 872 PH2_Tongeber_mute "Die Akustikausgabe des Systems wird unterdrückt, z.B. Wählhebel in 'P', Parlbremse geschlossen (8-Kanal-System)";
CM_ SG_ 872 PH2_Tongeber_V_aktiv "Rohsignal für 'Tongeber vorne wird angesteuert', verlängerbar mit Nachlauftimer.
Bit wird nicht während des Stellgliedtests angesteuert.";
CM_ SG_ 872 PH2_Visualisierung "Signal zeigt den Partnersteuergeräten RearView/TopView/ARA/... den aktuellen Status der Visualisierung des OPS. Die Partnersteuergeräte können dadurch auch ihre Aufschaltung an dieses Signal koppeln.";

CM_ SG_ 2463978617 PH2_Aufschaltursache "Der Grund für die Aufschaltung der Einparkhilfe wird angegeben, z.B. bei der Aktivierung der Einparkhilfe durch eine andere Funktion, wird diese Funktion als Aktivierungsursache für die Dauer der Aktivierung gemeldet.
Das Signal wird den PH_Systemzustand";
CM_ SG_ 2463978617 PH2_Verschmutzungsmeldung "Meldung einer Verschmutzung/Vereisung der PDC an das Kombi";
CM_ SG_ 2463978617 PH2_WAH_Meldung "Steuert die HMI-Meldungen im Kombi für den Wiederanfahrhinweis";

CM_ SG_ 1175 PDC_Tonausgabe_Front "In Abhängigkeit der Systemaktivitäten werden unterschiedliche Tonwarnungen ausgegeben. 
Kombi spielt entsprechende WAV.-Datei über internen Audiomaster ab.

0 = kein Ton
1 = Intervallton 1
2 = Intervallton 2
3 = Intervallton 3
4 = Intervallton 4
5";
CM_ SG_ 1175 PDC_Tonausgabe_Heck "In Abhängigkeit der Systemaktivitäten werden unterschiedliche Tonwarnungen ausgegeben. 
Kombi spielt entsprechende WAV.-Datei über internen Audiomaster ab.

0 = kein Ton
1 = Intervallton 1
2 = Intervallton 2
3 = Intervallton 3
4 = Intervallton 4
5";
CM_ SG_ 1175 PH_Abschaltursache "Abschaltursache bleibt bis zur nächsten Aktivierung bzw. bis KL15 aus gesetzt
Im Fehlerfall (blinkende LED) wird '7' gesendet obwohl das System noch aktiv ist, bei 'geheiltem' Fehler wird sofort wieder der Zustand '0' gesendet";
CM_ SG_ 1175 PH_Anf_Audioabsenkung "Es gibt zwei unterschiedliche Nachlauftimer für dieses Bit:
1. normale Funktion
2. Demotonausgabe";
CM_ SG_ 1175 PH_Anf_Verdeck "Anforderung an ein Verdeck-System, die vom Fahrer angeforderte Öffnung/Schließung zu verhindern";
CM_ SG_ 1175 PH_defekt "Zeigt an das sich die Parkhilfe im Fehlerzustand befindet. Signal bleibt bis zur nächsten 'Gut-Aktivierung' gesetzt.
Spezialfall: Sensordefekt hinten bei Anhängerbetrieb. Anhänger wird abgesteckt Fehler wird gesetzt. Fehlerfall bleibt bis Behebung des De";
CM_ SG_ 1175 PH_Display_Kundenwunsch "Anzeige der bei Aktivierung verwendeten Parameter bzgl. Kundenwunsch Displayanziege. Änderungen werden erst bei erneuter Aktivierung aktualisiert.";
CM_ SG_ 1175 PH_Frequenz_hinten "Uebertragung der aktuell im APS Steuergeraet gespeicherten Werte fuer Tongeber Frequenz hinten
Anzeige der aktuell verwendeten Parameter (nicht zwingend die abgespeicherten - da Werte erst 2s nach der letzten Änderung gespeichert werden!)";
CM_ SG_ 1175 PH_Frequenz_vorn "Uebertragung der aktuell im APS Steuergeraet gespeicherten Werte fuer Tongeber Frequenz vorne
Anzeige der aktuell verwendeten Parameter (nicht zwingend die abgespeicherten - da Werte erst 2s nach der letzten Änderung gespeichert werden!)";
CM_ SG_ 1175 PH_gestoert "Eine Störung ist aufgetreten, der die Parkhilfe in einen 'gestört-Zustand' versetzt, z.B. massiver Fremdultraschall, Vereisung, Schnee.Derzeit nur für Störschall benutzt, da keinerlei andere Erkennung implementiert.";
CM_ SG_ 1175 PH_Lautstaerke_hinten "Uebertragung der aktuell im APS Steuergeraet gespeicherten Werte fuer Tongeber Lautstaerke hinten
Anzeige der aktuell verwendeten Parameter (nicht zwingend die abgespeicherten - da Werte erst 2s nach der letzten Änderung gespeichert werden!)";
CM_ SG_ 1175 PH_Lautstaerke_vorn "Uebertragung der aktuell im APS Steuergeraet gespeicherten Werte fuer Tongeber Lautstaerke vorn.
Anzeige der aktuell verwendeten Parameter (nicht zwingend die abgespeicherten - da Werte erst 2s nach der letzten Änderung gespeichert werden!)";
CM_ SG_ 1175 PH_nachtr_Stopp_Anf "Dieses Signal dient dem Motor als Trigger, dass ein nachträglicher Motorstopp eingeleitet werden kann, wenn es die Bedingungen des StSt Koordinators dies zulassen. ";
CM_ SG_ 1175 PH_Opt_Anz_H_Hindernis "mindestens 1 Segment wird für den hinteren Detekionsbereich dargestellt, also ein Hindernis ist im Detektionsbereich. Funktion nur bei gesicherter Rückmeldung vom ASG gegeben.";
CM_ SG_ 1175 PH_Opt_Anz_V_Hindernis "mindestens 1 Segment wird für den vorderen Detekionsbereich dargestellt, also ein Hindernis ist im Detektionsbereich. Funktion nur bei gesicherter Rückmeldung vom ASG gegeben.";
CM_ SG_ 1175 PH_Opt_Anzeige_H_ein "OPS hinten ist im Display aktiv bzw. Anzeigemodule hinten sind eingeschaltet. Funktion nur bei gesicherter Rückmeldung vom ASG gegeben.";
CM_ SG_ 1175 PH_Opt_Anzeige_V_ein "OPS vorne ist im Display aktiv bzw. Anzeigemodule vorne sind eingeschaltet. Funktion nur bei gesicherter Rückmeldung vom ASG gegeben.";
CM_ SG_ 1175 PH_StartStopp_Info "Stopp-Freigabe und Start-Anforderung an den Start-Stopp-Koordinator";
CM_ SG_ 1175 PH_Stoermeldung "Meldung einer Störung der PDC an das Kombi";
CM_ SG_ 1175 PH_Systemzustand "Aktivierungsursache wird für die Dauer der Aktivierung gemeldet.
Im Fehlerfall bei atkviem System wechselt das Signal auf '7'
(siehe auch 'Abschaltursache')";
CM_ SG_ 1175 PH_Taster "Taster Status (für RVC/TopView)";
CM_ SG_ 1175 PH_Tongeber_H_aktiv "Rohsignal für 'Tongeber hinten wird angesteuert', verlängerbar mit Nachlauftimer.
Bit wird nicht während des Stellgliedtests angesteuert.";
CM_ SG_ 1175 PH_Tongeber_H_verfuegbar "Tongeber ist für die Tonausgabe für externe Funktionen verfügbar. PDC ist aktiv und Tongeber ist nicht gestört.";
CM_ SG_ 1175 PH_Tongeber_mute "Die Akustikausgabe des Systems wird unterdrückt, z.B. Wählhebel in 'P', Parlbremse geschlossen (8-Kanal-System)";
CM_ SG_ 1175 PH_Tongeber_V_aktiv "Rohsignal für 'Tongeber vorne wird angesteuert', verlängerbar mit Nachlauftimer.
Bit wird nicht während des Stellgliedtests angesteuert.";
CM_ SG_ 1175 PH_Visualisierung "Signal zeigt den Partnersteuergeräten RearView/TopView/ARA/... den aktuellen Status der Visualisierung des OPS. Die Partnersteuergeräte können dadurch auch ihre Aufschaltung an dieses Signal koppeln.";
CM_ SG_ 1175 PLA_Anf_Aufschaltung_RVC "Anforderung der Aufschaltung RVC durch PLA";

CM_ SG_ 1355 BCM_WAH_Meldung "Steuert die HMI-Meldungen im Kombi für den Wiederanfahrhinweis";
CM_ SG_ 1355 PDC_Charisma_FahrPr "Istwert der Kennline (siehe System-LAH MQB FPA)";
CM_ SG_ 1355 PDC_Charisma_Status "Charisma Systemstatus des Charisma-Teilnehmers";
CM_ SG_ 1355 PH_Aufschaltursache "Der Grund für die Aufschaltung der Einparkhilfe wird angegeben, z.B. bei der Aktivierung der Einparkhilfe durch eine andere Funktion, wird diese Funktion als Aktivierungsursache für die Dauer der Aktivierung gemeldet.
Das Signal wird den PH_Systemzustand";
CM_ SG_ 1355 PH_Ton_Ausgabe "Anforderung einer Tonausgabe beim MIB3 durch die Parkhilfe";
CM_ SG_ 1355 PH_Ton_Lautstaerke "Wunschlautstärke der Tonanforderung beim MIB3 durch die Parkhilfe.";
CM_ SG_ 1355 PH_Ton_Pausenlaenge "Pause zwischen den angeforderten Tönen beim MIB3 durch die Parkhilfe. Nur für Intervalltöne, nicht relevant für Dauerton und Quittierungston.";
CM_ SG_ 1355 PH_Ton_Richtung "Abspielrichtung des angeforderten Ton beim MIB3 durch die Parkhilfe";
CM_ SG_ 1355 PH_Verschmutzungsmeldung "Meldung einer Verschmutzung/Vereisung der PDC an das Kombi";

CM_ SG_ 617 PIF_Identifier "Mux Identifier PIF Botschaft";
CM_ SG_ 617 PIF_LT_Bin_0 "Wahrscheinlichkeit im Long-Term Horizont. Übermittelte Größe entsprechend PIF_Mux";
CM_ SG_ 617 PIF_LT_Bin_1 "Wahrscheinlichkeit im Long-Term Horizont. Übermittelte Größe entsprechend PIF_Mux";
CM_ SG_ 617 PIF_LT_Bin_2 "Wahrscheinlichkeit im Long-Term Horizont. Übermittelte Größe entsprechend PIF_Mux";
CM_ SG_ 617 PIF_LT_Bin_3 "Wahrscheinlichkeit im Long-Term Horizont. Übermittelte Größe entsprechend PIF_Mux";
CM_ SG_ 617 PIF_LT_Bin_4 "Wahrscheinlichkeit im Long-Term Horizont. Übermittelte Größe entsprechend PIF_Mux";
CM_ SG_ 617 PIF_LT_Bin_5 "Wahrscheinlichkeit im Long-Term Horizont. Übermittelte Größe entsprechend PIF_Mux";
CM_ SG_ 617 PIF_LT_Bin_6 "Wahrscheinlichkeit im Long-Term Horizont. Übermittelte Größe entsprechend PIF_Mux";
CM_ SG_ 617 PIF_LT_Bin_7 "Wahrscheinlichkeit im Long-Term Horizont. Übermittelte Größe entsprechend PIF_Mux";
CM_ SG_ 617 PIF_LT_Bin_8 "Wahrscheinlichkeit im Long-Term Horizont. Übermittelte Größe entsprechend PIF_Mux";
CM_ SG_ 617 PIF_LT_Status "Status der Long-Term Botschaft (0 - 10 s Prädiktionshorizont)";
CM_ SG_ 617 PIF_MT_Bin_0 "Wahrscheinlichkeit für Bereich 0 im Mid-Term Horizont. Übermittelte Größe entsprechend PIF_Mux";
CM_ SG_ 617 PIF_MT_Bin_1 "Wahrscheinlichkeit für Bereich 0 im Mid-Term Horizont. Übermittelte Größe entsprechend PIF_Mux";
CM_ SG_ 617 PIF_MT_Bin_2 "Wahrscheinlichkeit für Bereich 0 im Mid-Term Horizont. Übermittelte Größe entsprechend PIF_Mux";
CM_ SG_ 617 PIF_MT_Bin_3 "Wahrscheinlichkeit für Bereich 0 im Mid-Term Horizont. Übermittelte Größe entsprechend PIF_Mux";
CM_ SG_ 617 PIF_MT_Bin_4 "Wahrscheinlichkeit für Bereich 0 im Mid-Term Horizont. Übermittelte Größe entsprechend PIF_Mux";
CM_ SG_ 617 PIF_MT_Bin_5 "Wahrscheinlichkeit für Bereich 0 im Mid-Term Horizont. Übermittelte Größe entsprechend PIF_Mux";
CM_ SG_ 617 PIF_MT_Bin_6 "Wahrscheinlichkeit für Bereich 0 im Mid-Term Horizont. Übermittelte Größe entsprechend PIF_Mux";
CM_ SG_ 617 PIF_MT_Bin_7 "Wahrscheinlichkeit für Bereich 0 im Mid-Term Horizont. Übermittelte Größe entsprechend PIF_Mux";
CM_ SG_ 617 PIF_MT_Bin_8 "Wahrscheinlichkeit für Bereich 0 im Mid-Term Horizont. Übermittelte Größe entsprechend PIF_Mux";
CM_ SG_ 617 PIF_MT_Status "Status der Mid-Term Botschaft (0 - 10 s Prädiktionshorizont)";
CM_ SG_ 617 PIF_ST_Bin_0 "Wahrscheinlichkeit für Bereich 0 im Short-Term Horizont. Übermittelte Größe entsprechend PIF_Mux";
CM_ SG_ 617 PIF_ST_Bin_1 "Wahrscheinlichkeit für Bereich 1 im Short-Term Horizont. Übermittelte Größe entsprechend PIF_Mux";
CM_ SG_ 617 PIF_ST_Bin_2 "Wahrscheinlichkeit für diesen Bereich im Short-Term Horizont. Übermittelte Größe entsprechend PIF_Mux";
CM_ SG_ 617 PIF_ST_Bin_3 "Wahrscheinlichkeit für diesen Bereich im Short-Term Horizont. Übermittelte Größe entsprechend PIF_Mux";
CM_ SG_ 617 PIF_ST_Bin_4 "Wahrscheinlichkeit für diesen Bereich im Short-Term Horizont. Übermittelte Größe entsprechend PIF_Mux";
CM_ SG_ 617 PIF_ST_Bin_5 "Wahrscheinlichkeit für diesen Bereich im Short-Term Horizont. Übermittelte Größe entsprechend PIF_Mux";
CM_ SG_ 617 PIF_ST_Bin_6 "Wahrscheinlichkeit für diesen Bereich im Short-Term Horizont. Übermittelte Größe entsprechend PIF_Mux";
CM_ SG_ 617 PIF_ST_Bin_7 "Wahrscheinlichkeit für diesen Bereich im Short-Term Horizont. Übermittelte Größe entsprechend PIF_Mux";
CM_ SG_ 617 PIF_ST_Bin_8 "Wahrscheinlichkeit für diesen Bereich im Short-Term Horizont. Übermittelte Größe entsprechend PIF_Mux";
CM_ SG_ 617 PIF_ST_Status "Status der Short-Term Botschaft (0 - 10 s Prädiktionshorizont)";
CM_ SG_ 617 PIF_Toggle "Alive Counter der PIF-Funktion";

CM_ SG_ 2549876804 PnC_Ladegeraet_Req_Data "Plug and Charge request an Ladegeraet";

CM_ SG_ 2550007876 PnC_Ladegeraet_Resp_Data "Plug and Charge response an Ladegeraet";

CM_ SG_ 2527679715 pVS_EnergieAnfr_SocStart "Energieanfrage zur Erstellung einer Ladekurve: Start-SoC";
CM_ SG_ 2527679715 pVS_EnergieAnfr_SocZiel "Energieanfrage zur Erstellung einer Ladekurve: Ziel-SOC";
CM_ SG_ 2527679715 pVS_EnergieAnfr_Zaehler "Fortlaufender Zähler für die Anfrage Energie durch die Funktion pVS.";
CM_ SG_ 2527679715 pVS_LadegrenzeAnfr_Leistung "Anfrage Ladeleistung mit welcher bis zu SOC aus BMS_LadegrenzeAntw_SOC geladen werden kann.
Anfrage wird von pVS zur Erstellung einer Ladekurve versendet.";
CM_ SG_ 2527679715 pVS_LadegrenzeAnfr_Zaehler "Fortlaufender Zähler für die Anfrage Ladegrenze für die Funktion pVS (Erzeugung einer Ladekurve)";
CM_ SG_ 2527679715 pVS_Zielklimamodus_Range "Zielklimamodus welchen die Klimaanlage im Fahrprogramm Range annehmen soll, wenn Sie nicht bereits in einem Energieeffizienterem Klimamodus ist.";
CM_ SG_ 2527679715 pVS_Zielklimamodus_Range_pers "Vom Nutzer konfigurierter Zielklimamodus (personalisiert) welchen die Klimaanlage im Fahrprogramm Range (ohne pVS) annehmen soll, wenn Sie nicht bereits in einem Energieeffizienterem Klimamodus ist.";

CM_ SG_ 1616 RA_AM_Tuning "Das Signal kennzeichnet einen aktiven AM Suchlauf. Während des Suchlaufes wird die Frequenz = 0 übertragen.
0 = frequency locked => Störquelle vermeidet die aktuelle Frequenz
1 = AM tuning in progress => Störquelle abschalten bzw.PWM Signal auf DC umsch";
CM_ SG_ 1616 RA_Frequency "Übermittlung der eingestellten Sendefrequenz AM oder FM, diese wird mit RA_Frequency_unit multipliziert.
Im DAB oder Hybrid/Online Mode wird die aktuelle FM-Alternativfrequenz oder, falls nicht vorhanden, die zuletzt gehörte Senderfrequenz übertragen (AM";
CM_ SG_ 1616 RA_Frequency_unit "Faktor für RA_Frequency
bei AM: Faktor 0 = 1kHz
sonst   Faktor 1 = 100kHz";
CM_ SG_ 1616 RA_PowerAmpOn "1 = Request for Amplifier; 0 = Amplifier mute/off";
CM_ SG_ 1616 RA_Radio_Error_Flag "1 = mindestens ein Kundendienstfehlerspeicher Eintrag vorhanden";
CM_ SG_ 1616 RA_Radio_mute "1=Radio is muted for telephone";
CM_ SG_ 1616 RA_Radio_on "1 = user perceived On";
CM_ SG_ 1616 RA_Radio_Surround "1 = Surround ON; 0 = Surround OFF
requests the Amp to switch Surroundmode";
CM_ SG_ 1616 RA_VNC_OFF "VNC = Vehicle Noice Cancellation;
1 = VNC OFF; 0 = VNC ON
requests the Amp to switch VNC off";

CM_ SG_ 1525 RW_Gesamt_Reichweite "Reichweite für primär und sekundär Reichweite (eventuell Gewichtet)";
CM_ SG_ 1525 RW_Gesamt_Reichweite_Max_Anzeige "Angabe der Maximalen Anzeige der gesamten Reichweite.
Ergänzt das Signal RW_Gesamt_Reichweite_Anzeige.Die Einheit dieser Signal ist über RW_Reichweite_Einheit_Anzeige bereitgestellt.";
CM_ SG_ 1525 RW_Prim_Reichweitenv_Einheit "Für primäre  Reichweitenberechnung (KBI_Prim_Reichweitenverbrauch) zugrunde gelegte Einheit";
CM_ SG_ 1525 RW_Prim_Reichweitenverbrauch "Für primäre Reichweitenberechnung zugrunde gelegter Verbrauch";
CM_ SG_ 1525 RW_Primaer_Reichweite "Reichweite der primären Antriebsart";
CM_ SG_ 1525 RW_Reservewarnung_2_aktiv "Ansteuerung der Reservewarnung im Kombiinstrument (Leuchte und MFA-Warnhinweis). Wird gesetzt bei Erreichen / Unterschreiten eines unteren Reichweitenschwellwerts und zurückgenommen bei Erreich.
Zusätzlich erfolgt eine logische Verknüpfung mit einer akti";
CM_ SG_ 1525 RW_RWDS_Lastprofil "Lastprofil zur Bestimmung der notwendigen Nachladeenergie (Reichweitendurchschnittstrom)";

CM_ SG_ 1527 RW_Gesamt_Reichweite_Anzeige "Reichweite für primär und sekundär Reichweite (eventuell Gewichtet) zur Anzeige im Kombi. Die Einheit dieser Signal ist über RW_Reichweite_Einheit_Anzeige bereitgestellt.";
CM_ SG_ 1527 RW_Primaer_Reichweite_Anzeige "Reichweite der primären Antriebsart zur Anzeige im Kombi";
CM_ SG_ 1527 RW_Reichweite_Einheit_Anzeige "Einheit für Primaer-/Sekundaer-/Gesamt- Reichweite zur Anzeige im Kombi";
CM_ SG_ 1527 RW_Reservewarnung_aktiv "Ansteuerung der Reservewarnung im Kombiinstrument (Leuchte und MFA-Warnhinweis). Wird gesetzt bei Erreichen / Unterschreiten eines unteren Reichweitenschwellwerts und zurückgenommen bei Erreichen / Überschreiten eines oberen Reichweitenschwellwerts.";
CM_ SG_ 1527 RW_Sek_Reichweitenv_Einheit "Für sekundäre Reichweitenberechnung (KBI_Sek_Reichweitenverbrauch) zugrunde gelegte Einheit";
CM_ SG_ 1527 RW_Sek_Reichweitenverbrauch "Für sekundäre Reichweitenberechnung zugrunde gelegter Verbrauch";
CM_ SG_ 1527 RW_Sekundaer_Reichweite "Reichweite der sekundaeren Antriebsart";
CM_ SG_ 1527 RW_Sekundaer_Reichweite_Anzeige "Reichweite der sekundaeren Antriebsart zur Anzeige im Kombi";
CM_ SG_ 1527 RW_Tendenz "Signalisierung der RW-Tendenz auf Basis der aktuellen Fahrweise. ";
CM_ SG_ 1527 RW_Texte "Signal zum Steuern von reichweitenbezogenen Hinweistexten für Pop-Up Anzeigen im Kombiinstrument";

CM_ SG_ 2463978658 Rezi_Error_NW_Timeout "Fehler in CAN-Kommunikation, gesendet von Rezi";
CM_ SG_ 2463978658 Rezi_Fehler_Bauteil_Defekt "Fehler bei Bauteildefekt (elekrischer Fehler, o.ä.), gesendet von Rezi";
CM_ SG_ 2463978658 Rezi_Fehler_Blockiert "Läufer des H2-Rezirkulationsgebläses ist blockiert, gesendet von Rezi";
CM_ SG_ 2463978658 Rezi_Fehler_Ueberspannung_HV "Überspannung im HV-DC-Netz, gesendet von Rezi";
CM_ SG_ 2463978658 Rezi_Fehler_Ueberspannung_NV "Überspannung im NV-Netz, gesendet von Rezi";
CM_ SG_ 2463978658 Rezi_Fehler_Uebertemperatur "Fehlermeldung bei überschreiten einer definierten Temperaturschwelle, gesendet von Rezi";
CM_ SG_ 2463978658 Rezi_Fehler_Unterspannung_HV "Unterspannung im HV-DC-Netz, gesendet von Rezi";
CM_ SG_ 2463978658 Rezi_IstDrehzahl "aktuelle Drehzahl des H2-Rezirkulationsgebläses, gesendet von Rezi";
CM_ SG_ 2463978658 Rezi_IstSpannung "DC-Spannung des H2-Rezirkulationsgebläses, gesendet von Rezi";
CM_ SG_ 2463978658 Rezi_IstStrom "DC-Strom des H2-Rezirkulationsgebläses, gesendet von Rezi";
CM_ SG_ 2463978658 Rezi_Status_Spgfreiheit "Status der HV-Spannungsfreiheitserfassungsfunktion in der LE des Rezi";
CM_ SG_ 2463978658 Rezi_Warnung_Uebertemperatur "Warnung bei überschreiten einer definierten Temperaturschwelle, gesendet von Rezi";

CM_ SG_ 1126 RTM_Warnstatus "Signalisiert die RTM-Warnstufe.";

CM_ SG_ 2527679790 RTM_Fehlerstatus "The error status of RTM.";
CM_ SG_ 2527679790 RTM_IstModus "The operation status of RTM";
CM_ SG_ 2527679790 RTM_OTA_Download_Process "RTM OTA package download process in percentage[%]:0~100%";
CM_ SG_ 2527679790 RTM_OTA_Download_Size "The size of OTA download package [MB]";
CM_ SG_ 2527679790 RTM_OTA_Download_Speed "RTM OTA package download speed
[MB/s]";
CM_ SG_ 2527679790 RTM_OTA_InstallDuration "The estimated duration of  OTA package installation
Range:1-30min";
CM_ SG_ 2527679790 RTM_OTA_InstallPrecondition "The precondition check for SW upgrade installation.";
CM_ SG_ 2527679790 RTM_OTA_InstallProcess "RTM OTA package installation process in percentage[%]:0~100%";
CM_ SG_ 2527679790 RTM_OTA_SignalStrength "The signal strength during OTA package downloading";

CM_ SG_ 2527679792 MIB_OTA_Comfirmation "MIB Pop-up confirmations for RTM OTA";

CM_ SG_ 424 SARA_11_CRC "Für MLB:
'Berechnung siehe Lastenheft 'Kommunikationsabsicherung für Flexray und CAN''

Ab MQB und MLBevo:
'Berechnung siehe Lastenheft 'End-to-End Kommunikationsabsicherung'

Endwerte siehe Begleitdokument 'S-PDU Kennungsfolge'";
CM_ SG_ 424 SARA_Accel_X_r "Beschleunigung Acceleration-X routable:
- 0x0000= Sensor nicht verbaut, Signal wird nicht berechnet
- genutzter Wertebereich ± 640 m/s²

Filterung: 60 Hz Sensorfilter + 15 Hz uC-Filter (Cheby-II 3.Ordnung)";
CM_ SG_ 424 SARA_Accel_Y_r "Beschleunigung Acceleration-Y routable:
- 0x0000= Sensor nicht verbaut, Signal wird nicht berechnet
- genutzter Wertebereich ± 640 m/s²

Filterung: 60 Hz Sensorfilter + 15 Hz uC-Filter (Cheby-II 3.Ordnung)";
CM_ SG_ 424 SARA_CF_Accel_X_r "Confidence Faktor Beschleunigung Acceleration-X routable:

0=gültiger Wert
1=nicht belegt
2=nicht belegt
3=Temporärer Fehler {solange möglich werden aktuelle Sensorwerte gesendet, ansonsten 0xFFFF}
4=Init {0x8000 wird gesendet}
5=Sensor nicht verba";
CM_ SG_ 424 SARA_CF_Accel_Y_r "Confidence Faktor Beschleunigung Acceleration-Y routable:

0=gültiger Wert
1=nicht belegt
2=nicht belegt
3=Temporärer Fehler {solange möglich werden aktuelle Sensorwerte gesendet, ansonsten 0xFFFF}
4=Init {0x8000 wird gesendet}
5=Sensor nicht verba";
CM_ SG_ 424 SARA_CF_Omega_Z_r "Confidence Faktor Winkelgeschwindigkeit Omega-Z routable:

0=gültiger Wert
1=nicht belegt
2=nicht belegt
3=Temporärer Fehler {solange möglich werden aktuelle Sensorwerte gesendet, ansonsten 0xFFFF}
4=Init {0x8000 wird gesendet}
5=Sensor nicht verba";
CM_ SG_ 424 SARA_Omega_Z_r "Winkelgeschwindigkeit Omega-Z routable:
- 0x0000 = Sensor nicht verbaut, Signal wird nicht berechnet
- genutzter Wertebereich ± 320 Deg/s

Filterung: 60 Hz Sensorfilter + 15 Hz uC-Filter (Cheby-II 3.Ordnung)";

CM_ SG_ 1313 STH_EKP_Anst "STH sendet die Anforderung zur Ansteuerung der EKP an den Motor, um Kraftstoffbehälter der STH zu befüllen.";
CM_ SG_ 1313 STH_Fehler_ElWaPu "Fehler der el. Zusatzwasserpumpe der zur Deaktivierung der Wasserpumpe führt ";
CM_ SG_ 1313 STH_Fehlerstatus "Übermittlung der unterschiedlichen Fehlerzustände der Standheizung";
CM_ SG_ 1313 STH_Funk_aus "Funkbefehl über Funkfernbedienung zum Ausschalten Standheizung";
CM_ SG_ 1313 STH_Funk_ein "Funkbefehl über Funkfernbedienung zum Einschalten Standheizung";
CM_ SG_ 1313 STH_Geblaese "Ein-/ Ausschaltbefehl an die Klimaanlage, Gebläse";
CM_ SG_ 1313 STH_Heizleistung "Heizleistung in %";
CM_ SG_ 1313 STH_KL_HUP "Signal HUP Aktivierung an Klima

0 = HUP aus
1 = HUP ein";
CM_ SG_ 1313 STH_KVS "Kraftstoffverbrauch";
CM_ SG_ 1313 STH_KVS_Ueberlauf "Kraftstoffverbrauch, Überlauf hat stattgefunden";
CM_ SG_ 1313 STH_LED "Funktionslampe";
CM_ SG_ 1313 STH_Motorvorwaermung "Info an der Motor, dass der Aufheizvorgang mit Motorvorwärmung erfolgt ist";
CM_ SG_ 1313 STH_Pumpen_Anf_extern "Anforderung der motorseitigen elektr. (externen) Wasserpumpe zur Kreislaufunterstützung im Standheizbetrieb";
CM_ SG_ 1313 STH_Servicemode "Rückmeldung, dass die Standheizung sich gerade im Diagnosemodus befindet, gestartet über Diagnosetester";
CM_ SG_ 1313 STH_SH_ZH "0 = Heizgerät ist Standheizung
1 = Heizgerät ist Zuheizer
Gerätekennung WZH oder ZH
";
CM_ SG_ 1313 STH_Start_folgt "Thema Start/Stop: Im Stop-Modus muß das KBT einen Wiederstart anfordern, da ein STH-Start notwendig ist.";
CM_ SG_ 1313 STH_Texte "Anforderung der unterschiedlichen Anzeigetexte im Mitteldisplay des Kombi.

0: Keine Anzeige
1: Kein Standheizungs- bzw Lueftungsbetrieb wegen Batteriemanagementeinschraenkung
2: Kein Standheizungs- bzw Lueftungsbetrieb wegen Kraftstoffmangels
3: Kei";
CM_ SG_ 1313 STH_Ventil_Status "Statusrückmeldung Ansteuerung 3/2 Wege-Ventil";
CM_ SG_ 1313 STH_Ventiloeffnungszeit "Die Standheizung sendet an den Motor die Information darüber wie lange das Magnetventil die Wasserkreisläufe von 'klein' aus 'gross' geschaltet hat. ";
CM_ SG_ 1313 STH_Waermeeintrag "Signal enthält die Brenndauer in 1min-Schritten, über welche die Standheizung gelaufen ist";
CM_ SG_ 1313 STH_war_aktiv "Bit beeinhaltet die Info, dass die Standheizung während der letzten halbe Stunde aktiv war.";
CM_ SG_ 1313 STH_Wassertemp "Kühlmitteltemperatur der Standheizung";
CM_ SG_ 1313 STH_Zusatzheizung "Kraftstoffzuheizer aktiv";

CM_ SG_ 505 ACA_HF_Grund_AV_AB "Abschaltbedingung und Aktivierverhinderung";
CM_ SG_ 505 ACA_HF_Status "Status der Hands-Off-Querfuehrung";
CM_ SG_ 505 ACA_QF_Fahreruebernahme "Anforderung einer Fahrerübernhame durch die ACA Querführung für die HMI Ansteuerung im ACC-SG";
CM_ SG_ 505 ACA_QF_Status_Anzeige "Status der ACA Querführung, angepasst für die HMI Ansteuerung im ACC-SG";
CM_ SG_ 505 ACF_Spurwechsel_moeglich "Spurwechselmöglichkeit in Überholrichtung (verkehrssinnabh.) gegeben";
CM_ SG_ 505 ACF_Spurwechsel_wahrscheinlich "Spurwechsel in Überholrichtung (verkehrssinnabh.) wahrscheinlich";
CM_ SG_ 505 ACF_SwuFahrerUnaufmerksam "Erkannte Fahrerunaufmerksamkeit von der FZE (ACF)";
CM_ SG_ 505 FZE_Spurwechsel_erkannt_li "Spurwechsel nach links erkannt.";
CM_ SG_ 505 FZE_Spurwechsel_erkannt_re "Spurwechsel nach rechts erkannt.";
CM_ SG_ 505 FZE_STP_Abschaltbedingung "Es liegt eine FZE Bedienhandlung für eine Abschaltung vor";
CM_ SG_ 505 FZE_STP_Aktivierverhinderung "Aktivierverhinderungen STP aus Sicht der FZE";
CM_ SG_ 505 FZE_STP_Status "'Initialisierung / Auskodiert
FZE_STP Signale können verwendet werden
Es liegt ein reversibler Fehler für STP Signale vor
Es liegt ein irreversibler Fehler für STP Signale vor'
";
CM_ SG_ 505 STP_03_BZ "Botschaftszähler
Botschaft asynchron geroutet. Zählerwert kann springen.";
CM_ SG_ 505 STP_03_CRC "End-to-End Absicherung";
CM_ SG_ 505 STP_Funktion_freigegeben "Gibt in ASIL D an, ob die Funktion Staupilot zum Betrieb freigegeben ist.";
CM_ SG_ 505 STP_Notlaufaktivierung "Aktivierung des Notlaufs im ESC/EBKV durch den STP";
CM_ SG_ 505 STP_Slave_Status "Zustandsbeschreibung für STP-Slave-State-Machine";

CM_ SG_ 1413 GW_KD_Fehler "Kundendienstfehlerbit Gateway zur Anzeige eines im Gateway abgelegten Fehlerspeichereintrages.";
CM_ SG_ 1413 SI_BUS_01 "MQB/MQB_A0/PQ26: ACAN
MQB2020: ACAN(FD)
MLBevo: HCAN
E3_Volumen: ACAN(FD)
MQBw_Baseline: ACAN(FD)";
CM_ SG_ 1413 SI_BUS_02 "MQB/MQB A0 Standard+, High: FCAN
MQB2020: FCAN(FD)
MLBevo: Frei
E3_Volumen: FCAN(FD)
MQBw_Baseline: FCAN(FD)";
CM_ SG_ 1413 SI_BUS_03 "MQB/MQB A0/PQ26: KCAN
MQB2020: KCAN
MLBevo: KCAN
E3_Volumen: KCAN(HS) / K2CAN(FD) (Buskopplung)
MQBw_Baseline: KCAN(HS)";
CM_ SG_ 1413 SI_BUS_04 "MQB/MQB A0 Standard+, High: ICAN
MQB2020: ICAN(HS)
MLBevo: ICAN
E3_Volumen: ABCAN(FD)
MQBw_Baseline: ICAN(HS)";
CM_ SG_ 1413 SI_BUS_05 "MQB/MQB A0/PQ26: DiagCAN
MQB2020: DiagCAN(FD)
MLBevo: DiagCAN
E3_Volumen: DiagCAN(FD)
MQBw_Baseline: DiagCAN(FD)";
CM_ SG_ 1413 SI_BUS_06 "MQB/MQB A0/PQ26: ECAN
MQB2020: FASCAN(FD)
MLBevo: ECAN
E3_Volumen: FASCAN_1(FD)
MQBw_Baseline: FASCAN_1(FD)";
CM_ SG_ 1413 SI_BUS_07 "MQB: LIN1 (Energie)
MQB2020: LIN1 (Energie)
MLBevo: LIN1 (Energie)
E3_Volumen: LIN 1 (Energie)
MQBw_Baseline: LIN1 (Energie)";
CM_ SG_ 1413 SI_BUS_08 "MQB: LIN2 (MFL)
MQB2020: LIN2 (MFL)
MLBevo: LIN2 (MFL)
E3_Volumen: LIN2 (MFL)
MQBw_Baseline: LIN2 (MFL)";
CM_ SG_ 1413 SI_BUS_09 "MQB: LIN3 (unbelegt)
MQB2020: LIN3 (Uhr/FES)
MLBevo: LIN3 (Energie2)
MEB: LIN3
E³ 1.1 UNECE: MDKCAN";
CM_ SG_ 1413 SI_BUS_10 "MLBevo: Flexray
MQB2020: MCAN
MQBw_Baseline: FASCAN_2(FD)
E³ 1.1 UNECE: FASCAN_2(FD)";
CM_ SG_ 1413 SI_BUS_11 "MLBevo: Ethernet
MEB: LIN4";
CM_ SG_ 1413 SI_BUS_12 "MQB: unbelegt
MLBevo: K2CAN
E3_Volumen: MFLCAN
MQBw_Baseline: K2CAN(FD)";
CM_ SG_ 1413 SI_BUS_13 "MQB: unbelegt
MLBevo: DCAN
MEB: CCAN
MQBw_Baseline: K3CAN(FD)";
CM_ SG_ 1413 SI_BUS_14 "MQB/MQB A0: unbelegt
MQB2020: HCAN
MLBevo: CCAN
E3_Volumen: EVCAN(FD)
MQBw_Baseline: EVCANFD(FD)";
CM_ SG_ 1413 SI_BUS_15 "MQB: frei
MQB2020: frei
MLBevo: frei
MEB: AFSCAN";
CM_ SG_ 1413 SI_Bus_Identifikation "Das Signal identifiziert den Bus eindeutig. Das Signal ist konstant auf jedem Bus.
Der Signalwert entspricht dem Wert 'Busnummer' aus der VW80127 Gateway_component_list_databus_identification (0x2A2D) 'Bus-Identifier'.";
CM_ SG_ 1413 SI_CAB "CAB = Clusteraktivbits 
(Verwendung nur für Empfänger die nicht den AutoSar-SSW Stack implementiert haben)";
CM_ SG_ 1413 SI_Diagnose_Aktiv "Gibt an ob Diagnose-Botschaften empfangen werden und somit eine Diagnose aktiv ist.
MQB: Gibt an ob Diagnose-Bus Botschaften empfangen werden und somit eine Diagnose aktiv ist.";
CM_ SG_ 1413 SI_NWDF "Netzwerk-Diagnose Freigebe zur zentralen Aktivierung der Netzwerkdiagnose";
CM_ SG_ 1413 SI_NWDF_gueltig "Gültigkeitsbit zu SI_NWDF gemäß Lastenheft: Zentrale Aktivierung Netzwerkdiagnose";
CM_ SG_ 1413 SI_QRS_Mode "Messmodus Quick-Ruhestrom";
CM_ SG_ 1413 SI_Sammel_SG_Fehler "Anzahl der gesetzten KD-Fehler direkt angeschlossener Steuergeräte der DK3 und DK4 gemäß 80127.
Hinweis: Ein Subbusmaster stellt nur die gesammelte Information der an ihn angeschlossenen Steuergeräte der DK3 und DK4 zur Verfügung.

Für ServiceKey Auswe";
CM_ SG_ 1413 SI_Sammelfehler "Sammelfehlermeldung zur Anzeige im Kombi - siehe Spez. Sammelfehlermeldung
Hinweis: Einzelne Steuergeräte können zur Anpassung an den Produktionsprozess im Gateway auskodiert werden!";
CM_ SG_ 1413 SI_T_Mode "0x0: Transportmodus nicht aktiv
0x1: Transportmodus aktiv";
CM_ SG_ 1413 SI_T_Schutz "Transportschutz-Signal, das bei Transportmodus und Motorlauf aktiv bleibt
0x0: Transportschutz nicht aktiv
0x1: Transportschutz aktiv";

CM_ SG_ 1001 Thermo_Pred_Innen_Kunde_Anf "Änderung der Prädiktion iniziiert durch Kundenaktion";
CM_ SG_ 1001 Thermo_Pred_Innen_System_Anf "Systemseitig initiierte Änderung der Prädiktion; Signal ist einheitsloser Zähler mit Überlauf. 
Eine Inkrementierung steht für die Änderung der Umgebungsbedingungen mit dazugehöriger Klimaleistungsänderung.";
CM_ SG_ 1001 Thermo_Pred_P_dyn_Innen "Dynamsiche Leistung für Headup / Cooldown";
CM_ SG_ 1001 Thermo_Pred_P_stat_Innen "Stationäre Leistung für Heizen / Kühlen";
CM_ SG_ 1001 Thermo_Pred_T_dyn_Innen "Zeit bis zum Übergang vom dynamischen in stationären Betrieb";
CM_ SG_ 1001 Thermo_Verbrauch_BTL "Verbrauch für Heizen und Kühlen der Bauteile";
CM_ SG_ 1001 Thermo_Verbrauch_BTL_Ueberlauf "Überlauf-Bit Verbrauch Bauteil";
CM_ SG_ 1001 Thermo_Verbrauch_Innen "Verbrauch für Heizen und Kühlen Innenraum";
CM_ SG_ 1001 Thermo_Verbrauch_Innen_Ueberlauf "Überlauf-Bit Verbrauch Innenraum";

CM_ SG_ 1015 KL_HV_Energie_Anf "Anforderung HV - Energiebedarf, für VoKo 
";
CM_ SG_ 1015 TME_EKK_Fehlerstatus "aktueller Fehlerstatus des EKK";
CM_ SG_ 1015 TME_EKK_Istmodus "aktuelle IstModus des elektrischen Klimakompressors";
CM_ SG_ 1015 TME_HVEM_HV_Anf "Anforderung 'HV-Netz aktivieren' wegen Innenraumkonditionierung mit HV-Komponente";
CM_ SG_ 1015 TME_HVK_EKK_SOLL "Anforderung an HVK den HV EKK abzuschalten.";
CM_ SG_ 1015 TME_HVPTC_Fehlerstatus "aktueller Fehlerstatus des HVPTC";
CM_ SG_ 1015 TME_HVPTC_Istmodus "aktuelle Ist-Betriebsart der HV-PTC";
CM_ SG_ 1015 TME_Kuehlerluefer_3 "Soll-PWM für Lüfter3";
CM_ SG_ 1015 TME_OBD_Lampe_Anf "MIL-Request durch TME-Steuergerät";
CM_ SG_ 1015 TME_PWM_Pumpe1_tNT_Soll "Soll-PWM für Pumpe 1 im Tiefniedertemperaturkreis";
CM_ SG_ 1015 TME_StartStopp_Info "Stopp-Freigabe und Start-Anforderung an den Start-Stopp-Koordinator";
CM_ SG_ 1015 TME_StartStopp_Info_Prio "Priorität der Stopp-Freigabe und Start-Anforderung an den Start-Stopp-Koordinator";
CM_ SG_ 1015 TME_Strom_Kuehlerluefter "aktueller Kühlerlüfterstrom, +-20% ";

CM_ SG_ 1017 TME_Anf_KL "Max. Kühlerlüfteransteuerung der TME in %";
CM_ SG_ 1017 TME_EM1_IstVolumenstrom "Aktueller Ist-Wert des Vorlaufvolumenstromes LE/EM 1";
CM_ SG_ 1017 TME_EM2_IstVolumenstrom "Aktueller Ist-Wert des Vorlaufvolumenstromes LE/EM 2";
CM_ SG_ 1017 TME_EM3_IstVolumenstrom "Aktueller Ist-Wert des Vorlaufvolumenstromes LE/EM 3";
CM_ SG_ 1017 TME_Fehler_ElWaPu1 "Fehler der el. Zusatzwasserpumpe der zur Deaktivierung der Wasserpumpe führt";
CM_ SG_ 1017 TME_MMTR_Status "Status der Funktion Make me track ready für die Anzeige im Zentraldisplay";
CM_ SG_ 1017 TME_Nachlaufzeit "Nachlaufzeit TME für SKE am MSG";
CM_ SG_ 1017 TME_NT_Kreis_Status "Status gibt an ob der NT Kreis funktional i.O ist. (Komponenten i.O)";
CM_ SG_ 1017 TME_Pumpe1_Status "Rückmeldung des Heizungspumpenstatus";
CM_ SG_ 1017 TME_PWM_Pumpe2_HK_Soll "Soll-PWM für Heizkreispumpe vor Motorchiller";
CM_ SG_ 1017 TME_Status_KL "Fehlerstatus des Kühlerlüftermodules";
CM_ SG_ 1017 TME_Ventil1_Status "Statusrückmeldung Ansteuerung 3/2 Wege-Ventil";

CM_ SG_ 1399 TME_Energie_Komfort_NV "Energieverbrauch/-bedarf der 12V-Komponenten für die Innenraumklimatisierung ";
CM_ SG_ 1399 TME_Energie_Thermo_NV "Energieverbrauch/-bedarf der 12V-Komponenten für das Kühlen/Heizen von der Batterie";
CM_ SG_ 1399 TME_Leistung_Komfort_HV_stat "HV-Leistungsaufnahme Thermomanagement im stationären Fall für die Innenraumklimatisierung";
CM_ SG_ 1399 TME_Leistung_Komfort_NV_stat "12V-Leistungsaufnahme Thermomanagement im stationären Fall für die Innenraumklimatisierung";
CM_ SG_ 1399 TME_Leistung_Thermo_HV_stat "HV-Leistungsaufnahme Thermomanagement im stationären Fall für das Kühlen/Heizen von Bauteilen";
CM_ SG_ 1399 TME_Leistung_Thermo_NV_stat "12V-Leistungsaufnahme Thermomanagement im stationären Fall für das Kühlen/Heizen von Bauteilen";

CM_ SG_ 1375 TME_Absperrventil1_oeffnen "Signal an Standheizungs-SG das Absperrrventil anzusteuern";
CM_ SG_ 1375 TME_AC_LED "Steuerung der LED in der AC-Taste des KBTs";
CM_ SG_ 1375 TME_AC_Rueckmeldung "Status des Elektrischen Klimakompressors";
CM_ SG_ 1375 TME_Freigabe_Luft_PTC "Freigabe des Zuheizers im Klimagerät";
CM_ SG_ 1375 TME_Freigabe_Vorkond "Freigabe an das KBT, mit dem Innenraumkonditionieren zu beginnen.";
CM_ SG_ 1375 TME_Frischluftklappe_Soll "Sollvorgabe der Frischluftklappenstellung bei speziellem Heizbetrieb, z.B. Wärmepumpe";
CM_ SG_ 1375 TME_Heizstrategie "Info über aktuelle Heizstrategie an KBT";
CM_ SG_ 1375 TME_Heizungspumpen_Anst "Anforderung Heizungspumpenansteuerung";
CM_ SG_ 1375 TME_Kbr_Innenraum "Vorhandensein der Klimabereitschaft für Innenraum";
CM_ SG_ 1375 TME_Klima_Defizit "Für Innennraumklimatisierung aktuell nicht verfügbare  Leistung (Defizit = Istleistung - Solleistung)";
CM_ SG_ 1375 TME_Kuehlmittel_Sensor "Signal der Sensorelektroden für die Kühlmittelreserve aktuell, entstört, bewertet (OK/Mangel)
Signalaenderung BEV: Zusaetzlich zum Kuehlmittelsensor werden Fehler an Wasserpumpe des Kuehlsystems auf das Fehlerbit gemappt.";
CM_ SG_ 1375 TME_Nachlaufzeit_Heizp "Nachlaufzeit für Heizungspumpe";
CM_ SG_ 1375 TME_Systemstatus "Systemstatus der TME";
CM_ SG_ 1375 TME_Temp_KM_vor_HWT "Kühlmitteltemperatur vor HWT";
CM_ SG_ 1375 TME_Umluftklappe_Soll "Sollvorgabe der Umluftklappenstellung bei speziellem Heizbetrieb, z.B. Wärmepumpe";
CM_ SG_ 1375 TME_Verdampfer_Status "Verdampfer wird vom Kältemittel durchströmt";
CM_ SG_ 1375 TME_VoKo_Strategie_Anzeige "rueckgemeldete VoKo-Strategie fuer Anzeige
";
CM_ SG_ 1375 TME_Waermepumpe_aktiv "Aktivierungszustand der Wärmepumpe für Innenraumheizen";
CM_ SG_ 1375 TME_Zuheizer_Freigabe "Freigabe-Signal für Verbrennungszuheizfunktion";

CM_ SG_ 1373 TME_Geblaese "Aktivierung des Klimagebläses für Innenraumkonditionierung";
CM_ SG_ 1373 TME_IstSpannung_EKK_HV "Vom EKV gemessene HV-Spannung";
CM_ SG_ 1373 TME_Klimadefizit "Erkanntes Leistungsdefizit für die Klimatisierung";
CM_ SG_ 1373 TME_Kond_Innen_Betrieb "Funktionsrückmeldung über Betriebsstatus (an/aus) als Anzeige bzw  Kundenrückmeldung.";
CM_ SG_ 1373 TME_Kond_Innen_Betriebsdauer "Signal beeinhaltet die Zeitdauer welche vom TME_Steuergerät für die entsprechende Konditionierungsmaßnahme des Innenraumes errechnet wurde.
Die Dauer dient zur Aktivierung der entsrpechenden Komponenten und zur Anzeige im HMI.";
CM_ SG_ 1373 TME_Kond_Innen_Status "Innenraumkonditionierung ist möglich/n.möglich (wegen Komponentendefekt bzw-einschränkung)
Information wird zwecks Einschränkung/Freigabe der  Menübedienbarkeit im MMI benötigt.";
CM_ SG_ 1373 TME_Kuehlmittel_Temp_Pumpe1_tNT "Kühlwassertemperatur nach Batteriekreispumpe";
CM_ SG_ 1373 TME_SKE_Status_2 "Statusinformation über den Zustand der Kühlerjalousie 2";
CM_ SG_ 1373 TME_STH_aktiv "Funktionsrückmeldung für Standheizung aktiv";
CM_ SG_ 1373 TME_STH_Ansteuerung "Einschaltbefehl an die Standheizung seitens TME/Wärmepumpensteuergerät ";
CM_ SG_ 1373 TME_STH_Status "Verfügbarkeitsinformation über den Standheizungsbetrieb.
Information für MMI-Lade-Menü-bedienbarkeit";
CM_ SG_ 1373 TME_STL_aktiv "Funktionsrückmeldung Standlüftung aktiv ";
CM_ SG_ 1373 TME_Temp_KM_vor_LE "Kuehlmittelvorlauftemperatur vor der Leistungselektronik";
CM_ SG_ 1373 TME_Thermomanagement "Stufen des Thermomanagement";
CM_ SG_ 1373 TME_Verdampfertemperatur "Istwert der Verdampfertemperatur  (Verdampfer hängt am TME C7PHEV)";

CM_ SG_ 1657 TME_Eingriff_SKE_Oeffnung "TME Anforderung zur Öffnung der SKE";
CM_ SG_ 1657 TME_EKK_ProtectionMode "Bei akuter Ueberhitzungsgefahr des elektrischen Klimakompressors wird der ProtectionMode aktiviert.";
CM_ SG_ 1657 TME_Klimaanforderung "Anforderungsgrund der Klimaapplikation durch die TME";
CM_ SG_ 1657 TME_Klimaleistung "Leistung des elektrischen Klimakompressors";
CM_ SG_ 1657 TME_SKE_Pos_Summe "Aerodynamisch wirksamer Gesamtöffnungswinkel der am TME angeschlossenen Kühlerjalousiesteller.";
CM_ SG_ 1657 TME_SKE_Position_1 "Position der SKE 1

0 => Geöffnet
1 => Teilgeschlossen
2 => Geschlossen
3 => Init / Anforderung Initialisierung / Anforderung Referenzierung / Fehler heilen";
CM_ SG_ 1657 TME_SKE_PosResp "Rückmeldung SKE Position erreicht";
CM_ SG_ 1657 TME_SKE_Status "Status Information über den Zustand der SKE";
CM_ SG_ 1657 TME_Status_Kuehlmittel_Tmp_CrChk "Status des Cross Checks der Kuehlmitteltemperaturen von TME und MSG";
CM_ SG_ 1657 TME_Systemtemp "Systemtemperatur Antriebe für Kombi";
CM_ SG_ 1657 TME_TCP_Kond_active "Info über eine aktive HV-Batterie Konditionierung welche durch den Turbo Charging Planer ausgelöst wurde";
CM_ SG_ 1657 TME_Temp_KM_nach_EM "Momentanwert Kuehlmitteltemperatur nach E-Maschine";
CM_ SG_ 1657 TME_Temp_KM_vor_eATL "Kühlwassertemperatur vor eATL";
CM_ SG_ 1657 TME_Temperatur_Ruecklauf_VKM "Kühlmitteltemperatur Rücklauf VKM";
CM_ SG_ 1657 TME_Waermebilanz "TME bilanziert die Wärmeentnahme aus VKM";
CM_ SG_ 1657 TME_Waermebilanz_Status "Diagnosestatus zur Wärmebilanz. OBDI berücksichtigt die elektrischen Diagnosen. OBDII berücksichtigt die funktionalen Diagnosen bzw. Sensorwertplausibilisierung.";

CM_ SG_ 2463978655 TME_Senkenleistung_verfuegbar "aktuell verfuegbare Senkenleistung des TME_SG";

CM_ SG_ 2589283463 TME_Befuellung_aktiv "Signalisiert den aktiven bzw. inaktiven Status der Befüllroutine";
CM_ SG_ 2589283463 TME_Entlueftung_aktiv "Signalisiert den aktiven bzw. inaktiven Status der Entlüftungsroutine";
CM_ SG_ 2589283463 TME_Ionenspuelung_aktiv "Signalisiert den aktiven bzw. inaktiven Status der Ionenspülfunktion";
CM_ SG_ 2589283463 TME_KMP_Solldrehzahl "Angeforderte Solldrehzahl der Kühlmittelpumpe der FCU";
CM_ SG_ 2589283463 TME_Mischventil_Heizkreis_Ist "Aktuelle Ventilstellung des MVW1";
CM_ SG_ 2589283463 TME_Temp_KM_n_Mischventil_Heizkr "Temperatur des Kühlmediums nach MVW1 bei Verbindung von Heizkreis und HT-Kreis";
CM_ SG_ 2589283463 TME_Temp_KM_v_Pumpe_Heizkreis "Temperatur des Kühlmediums vor der Heizkreispumpe P5";
CM_ SG_ 2589283463 TME_THMTVLV_Sollstellung "Angeforderte Sollstellung des Mischventils der FCU";

CM_ SG_ 2463978827 TME_MVH_L_Istmodus "aktueller Ist-Modus des MVH_L";
CM_ SG_ 2463978827 TME_MVH_L_Spannung "Gemessene Spannung des MVH_L";
CM_ SG_ 2463978827 TME_MVH_L_Strom "Gemessener Strom des MVH_L";

CM_ SG_ 2463978828 TME_eKMV_Istmodus "aktuelle IstModus des eKMV";
CM_ SG_ 2463978828 TME_eKMV_Spannung "Gemessene Spannung des eKMV";
CM_ SG_ 2463978828 TME_eKMV_Strom "Gemessener Strom des eKMV";

CM_ SG_ 2463978829 TME_Batt_Kond_Verf "Verfügbarkeit der Vorkonditionierung der Batterie";
CM_ SG_ 2463978829 TME_MVEM_MinLeistung "MV Leistungsbedarf des TME-Systemes für Kllimatisierung/Batteriekühlung";
CM_ SG_ 2463978829 TME_Wunschleistung "MV Wunschleistung des TME-Systemes für Kllimatisierung";

CM_ SG_ 2589283464 TME_AGB_Temp "Temperatur Kuehlwasser im AGB";
CM_ SG_ 2589283464 TME_KUE_Auslastungsgrad "Auslastungsgrad des Kältekreislauf";
CM_ SG_ 2589283464 TME_VentilAGB_Pos "Positionsrueckmeldung  des AGB Ventil";

CM_ SG_ 2589283408 SKE1_AOCCT_fehlerstatus "Berechnung ActiveOffCycleCreditTechnology: SKE1 Fehler";
CM_ SG_ 2589283408 SKE1_AOCCT_teststatus "Berechnung ActiveOffCycleCreditTechnology: SKE1 Diagnose durchgeführt";
CM_ SG_ 2589283408 SKE1_AOCCT_timer1_count "Berechnung ActiveOffCycleCreditTechnology: Timer 1 für SKE1 Position <75%";
CM_ SG_ 2589283408 SKE1_AOCCT_timer1_verbaut "Berechnung ActiveOffCycleCreditTechnology: Timer 1 für SKE1 verbaut und codiert";
CM_ SG_ 2589283408 SKE1_AOCCT_timer2_count "Berechnung ActiveOffCycleCreditTechnology: Timer 2 für SKE2 Position >=75%";
CM_ SG_ 2589283408 SKE1_AOCCT_timer2_verbaut "Berechnung ActiveOffCycleCreditTechnology: Timer 2 für SKE1 verbaut und codiert";
CM_ SG_ 2589283408 SKE2_AOCCT_fehlerstatus "Berechnung ActiveOffCycleCreditTechnology: SKE2 Fehler";
CM_ SG_ 2589283408 SKE2_AOCCT_teststatus "Berechnung ActiveOffCycleCreditTechnology: SKE2 Diagnose gelaufen";
CM_ SG_ 2589283408 SKE2_AOCCT_timer1_count "Berechnung ActiveOffCycleCreditTechnology: Timer 1 für SKE2 Position <75%";
CM_ SG_ 2589283408 SKE2_AOCCT_timer1_verbaut "Berechnung ActiveOffCycleCreditTechnology: Timer 1 für SKE2 verbaut und codiert";
CM_ SG_ 2589283408 SKE2_AOCCT_timer2_count "Berechnung ActiveOffCycleCreditTechnology: Timer 2 für SKE2 >=75%";
CM_ SG_ 2589283408 SKE2_AOCCT_timer2_verbaut "Berechnung ActiveOffCycleCreditTechnology: Timer 2 für SKE2 verbaut und codiert";

CM_ SG_ 2527679716 TME_Pred_BTLSys_Anf_FP1 "Systemtrigger, dimensionslose Größe, wird hochgezählt sobald das Fahrprogramm 1 gewählt wird um im GW die Restreichweitenberechnung zu triggern";
CM_ SG_ 2527679716 TME_Pred_KlimaKunde_Anf_FP1 "Systemtrigger, dimensionslose Größe, wird hochgezählt sobald das Fahrprogramm 1 gewählt wird um im GW die Restreichweitenberechnung zu triggern";
CM_ SG_ 2527679716 TME_Pred_KlimaSys_Anf_FP1 "Systemtrigger, dimensionslose Größe, wird hochgezählt sobald das Fahrprogramm 1 gewählt wird um im GW die Restreichweitenberechnung zu triggern";
CM_ SG_ 2527679716 TME_ThermoPred_P_dyn_BTL_FP1 "Prädizierte Leistung der dynamischen Phase der Bauteilkonditionierung im Fahrprogramm 1";
CM_ SG_ 2527679716 TME_ThermoPred_P_dyn_Klima_FP1 "Prädizierte Leistung der dynamischen Phase der Innenraumklimatisierung im Fahrprogramm 1";
CM_ SG_ 2527679716 TME_ThermoPred_P_stat_Klima_FP1 "Prädizierte Leistung der statischen Phase der Innenraumklimatisierung im Fahrprogramm 1";
CM_ SG_ 2527679716 TME_ThermoPred_T_dyn_BTL_FP1 "Prädizierte Zeit der dynamischen Phase der Bauteilkonditionierung im Fahrprogramm 1";
CM_ SG_ 2527679716 TME_ThermoPred_T_dyn_Klima_FP1 "Prädizierte Zeit der dynamischen Phase der Innenraumklimatisierung im Fahrprogramm 1";

CM_ SG_ 2527679717 TME_Pred_BTLSys_Anf_FP2 "Systemtrigger, dimensionslose Größe, wird hochgezählt sobald das Fahrprogramm 2 gewählt wird um im GW die Restreichweitenberechnung zu triggern";
CM_ SG_ 2527679717 TME_Pred_KlimaKunde_Anf_FP2 "Systemtrigger, dimensionslose Größe, wird hochgezählt sobald das Fahrprogramm 2 gewählt wird um im GW die Restreichweitenberechnung zu triggern";
CM_ SG_ 2527679717 TME_Pred_KlimaSys_Anf_FP2 "Systemtrigger, dimensionslose Größe, wird hochgezählt sobald das Fahrprogramm 2 gewählt wird um im GW die Restreichweitenberechnung zu triggern";
CM_ SG_ 2527679717 TME_ThermoPred_P_dyn_BTL_FP2 "Prädizierte Leistung der dynamischen Phase der Bauteilkonditionierung im Fahrprogramm 2";
CM_ SG_ 2527679717 TME_ThermoPred_P_dyn_Klima_FP2 "Prädizierte Leistung der dynamischen Phase der Innenraumklimatisierung im Fahrprogramm 2";
CM_ SG_ 2527679717 TME_ThermoPred_P_stat_Klima_FP2 "Prädizierte Leistung der statischen Phase der Innenraumklimatisierung im Fahrprogramm 2";
CM_ SG_ 2527679717 TME_ThermoPred_T_dyn_BTL_FP2 "Prädizierte Zeit der dynamischen Phase der Bauteilkonditionierung im Fahrprogramm 2";
CM_ SG_ 2527679717 TME_ThermoPred_T_dyn_Klima_FP2 "Prädizierte Zeit der dynamischen Phase der Innenraumklimatisierung im Fahrprogramm 2";

CM_ SG_ 2527679718 TME_Pred_BTLSys_Anf_FP3 "Systemtrigger, dimensionslose Größe, wird hochgezählt sobald das Fahrprogramm 3 gewählt wird um im GW die Restreichweitenberechnung zu triggern";
CM_ SG_ 2527679718 TME_Pred_KlimaKunde_Anf_FP3 "Systemtrigger, dimensionslose Größe, wird hochgezählt sobald das Fahrprogramm 3 gewählt wird um im GW die Restreichweitenberechnung zu triggern";
CM_ SG_ 2527679718 TME_Pred_KlimaSys_Anf_FP3 "Systemtrigger, dimensionslose Größe, wird hochgezählt sobald das Fahrprogramm 3 gewählt wird um im GW die Restreichweitenberechnung zu triggern";
CM_ SG_ 2527679718 TME_ThermoPred_P_dyn_BTL_FP3 "Prädizierte Leistung der dynamischen Phase der Bauteilkonditionierung im Fahrprogramm 3";
CM_ SG_ 2527679718 TME_ThermoPred_P_dyn_Klima_FP3 "Prädizierte Leistung der dynamischen Phase der Innenraumklimatisierung im Fahrprogramm 3";
CM_ SG_ 2527679718 TME_ThermoPred_P_stat_Klima_FP3 "Prädizierte Leistung der statischen Phase der Innenraumklimatisierung im Fahrprogramm 3";
CM_ SG_ 2527679718 TME_ThermoPred_T_dyn_BTL_FP3 "Prädizierte Zeit der dynamischen Phase der Bauteilkonditionierung im Fahrprogramm 3";
CM_ SG_ 2527679718 TME_ThermoPred_T_dyn_Klima_FP3 "Prädizierte Zeit der dynamischen Phase der Innenraumklimatisierung im Fahrprogramm 3";

CM_ SG_ 2463978733 TME_ThermoPred_BTL_System_Anf "Systemtrigger, dimensionslose Größe, wird hochgezählt sobald einen Systemanforderung einen Neuberechnung der Restreichweite im Gateway Triggern muss";
CM_ SG_ 2463978733 TME_ThermoPred_P_dyn_Btl "Prädizierte Leistung der dynamischen Phase für Bauteilkonditionierung";
CM_ SG_ 2463978733 TME_ThermoPred_T_dyn_Btl "Prädizierte Zeit der dynamischen Phase für Bauteilkonditionierung";

CM_ SG_ 977 ASW_Warnung_aktiv_BFS "Abschaltung der Ambientefunktion Beifahrertür bei aktiver ASW Warnung an der Fahrertür";
CM_ SG_ 977 BFS_Status_eTAG "Status des elektrischen Tueraussengriffes Beifahrertuer";
CM_ SG_ 977 BT_ASW_HMI_defekt "Zeigt an, ob die ASW-Anzeige defekt ist.";
CM_ SG_ 977 BT_EC_Spiegel_Helligkeit "Dimmung für den Aussenspiegel in %";
CM_ SG_ 977 BT_FH_Bew_hoch "Fensterheber in Bewegung Richtung hoch";
CM_ SG_ 977 BT_FH_Bew_tief "Fensterheber in Bewegung Richtung tief";
CM_ SG_ 977 BT_FH_Block "Fensterscheibe befindet sich im mechanischen Block (oben oder unten)";
CM_ SG_ 977 BT_FH_Fang "Fangbereich ist 4mm von oberer Lippendichtung";
CM_ SG_ 977 BT_FH_normiert "Die Position der Fensterheberscheibe ist bekannt";
CM_ SG_ 977 BT_FH_Oeffnung "Gibt den Fensteröffnungswert in % an.";
CM_ SG_ 977 BT_FH_S_AutoHoch "FH Schalter automatisch hoch gedrückt";
CM_ SG_ 977 BT_FH_S_AutoTief "FH Schalter automatisch tief gedrückt";
CM_ SG_ 977 BT_FH_S_ManHoch "FH Schalter manuell hoch gedrückt";
CM_ SG_ 977 BT_FH_S_ManTief "FH Schalter manuell tief gedrückt";
CM_ SG_ 977 BT_FH_Thermo "gibt an ob Fensterheber im Thermoschutz ist";
CM_ SG_ 977 BT_gesafet "Im Zustand Safe wird auch das Signal BT_verriegelt = 1 gesendet";
CM_ SG_ 977 BT_Kisi_Fehler "Fehlerstatus Kindersicherungsfunktion";
CM_ SG_ 977 BT_Lock_Taster "Verriegelungstaster";
CM_ SG_ 977 BT_Lock_Taster_inv "Lock Taster nicht betätigt";
CM_ SG_ 977 BT_Oben_Block_erw "Fensterheber in Blockerwartung oben";
CM_ SG_ 977 BT_Schluesselschalter_auf "Schlüsselschalter Richtung auf betätigt";
CM_ SG_ 977 BT_Schluesselschalter_zu "Schluesselschalter Richtung zu betaetigt";
CM_ SG_ 977 BT_Schluesselschalter_zu_inv "Schluesselschalter zu nicht betaetigt";
CM_ SG_ 977 BT_SP_ausgerastet "Spiegel ausgerastet";
CM_ SG_ 977 BT_Sp_Blk_def "Blinker am Spiegel defekt";
CM_ SG_ 977 BT_Sp_Heizung_Anf "Kundenanforderung der Außenspiegelheizung Beifahrertür";
CM_ SG_ 977 BT_SP_Heizung_Status "Status der Spiegelheizung";
CM_ SG_ 977 BT_SP_ht_aktiv "Spiegelverstellung in Richtung hoch/tief aktiv";
CM_ SG_ 977 BT_SP_lr_aktiv "Spiegelverstellung in Richtung links/rechts aktiv";
CM_ SG_ 977 BT_Sperrklinke "Vorraste für Schloß

zwischen Vor- und Hauptraste Signal kurz auf 1, danach wieder auf 0 wenn Tür in Hauptraste (Tür ist sicher zu wenn Sperrklinke und Türkontakt auf 0 sind)";
CM_ SG_ 977 BT_SWA_HMI_defekt "Zeigt an, ob die SWA-Anzeige defekt ist.";
CM_ SG_ 977 BT_TAG_betaetigt "Türaussengriff";
CM_ SG_ 977 BT_TCR_Mode_aktiv "Signal zeigt eine aktive mechanische Redundanz am Türschloss an.";
CM_ SG_ 977 BT_TIG_betaetigt "Türinnengriff";
CM_ SG_ 977 BT_Tuer_geoeffnet "Zeigt eine geöffnete Tür an";
CM_ SG_ 977 BT_Tuer_Status "Türstatus mit Fehler und Initwert";
CM_ SG_ 977 BT_Tuer_Status_QBit "Dieses Bit gibt die Zuverlässigkeit des Türkontakts an. Ein auf dieses Bit folgender Fehlereintrag ist mit dem Sender des Bits abzustimmen (gültig ab PPE).";
CM_ SG_ 977 BT_Tueroeffnen_Warnung "Bit wird gesetzt, wenn Tür während der Fahrt geoeffnet werden soll.";
CM_ SG_ 977 BT_Tuerschloss_defekt "Das Beifahrertürschloss ist nicht mehr funktionsfähig.";
CM_ SG_ 977 BT_UEKB_aktiviert "Überschutzbegrenzungskraft bei Reversieren";
CM_ SG_ 977 BT_Unlock_Taster "Entriegelungstaster betätigt";
CM_ SG_ 977 BT_Unten_Block_erw "Fensterheber in Blockerwartung unten";
CM_ SG_ 977 BT_verriegelt "Zeigt eine verriegelte Tür an ( Status wird erst nach vollständiger Schlossansteuerung ausgegeben (<=1,5sek))";
CM_ SG_ 977 BT_Zuziehhilfe_aktiv "Zuziehhilfe aktiv";

CM_ SG_ 976 ASW_HMI_defekt "HMI Status der Funktion AusstiegsWarnung (ASW). HMI wird durch das TSG angesteuert.";
CM_ SG_ 976 ASW_wakeup "Trigger Start Nachlaufzeit t_1 für die Funktion Ausstieswarnung (ASW)";
CM_ SG_ 976 ASW_Warnung_aktiv_FS "Abschaltung der Ambientefunktion Fahrertür bei aktiver ASW Warnung an der Fahrertür";
CM_ SG_ 976 FS_Status_eTAG "Status des elektrischen Tueraussengriffes Fahrertuer";
CM_ SG_ 976 FT_BFS_Fond_Freigabe "Freigabe für Fondverstellung";
CM_ SG_ 976 FT_Daemmglas "Daemmglas verbaut";
CM_ SG_ 976 FT_FH_Bew_hoch "Fensterheber in Bewegung Richtung hoch";
CM_ SG_ 976 FT_FH_Bew_tief "Fensterheber in Bewegung Richtung tief";
CM_ SG_ 976 FT_FH_Block "Fensterscheibe befindet sich im mechanischen Block (oben oder unten)";
CM_ SG_ 976 FT_FH_Fang "Fangbereich ist 4mm von oberer Lippendichtung";
CM_ SG_ 976 FT_FH_normiert "Die Position der Fensterheberscheibe ist bekannt";
CM_ SG_ 976 FT_FH_Oeffnung "Gibt den Fensteröffnungswert in % an.";
CM_ SG_ 976 FT_FH_S_AutoHoch "FH Schalter automatisch hoch gedrückt";
CM_ SG_ 976 FT_FH_S_AutoTief "FH Schalter automatisch tief gedrückt";
CM_ SG_ 976 FT_FH_S_ManHoch "FH Schalter manuell hoch gedrückt";
CM_ SG_ 976 FT_FH_S_ManTief "FH Schalter manuell tief gedrückt";
CM_ SG_ 976 FT_FH_Thermo "gibt an ob Fensterheber im Thermoschutz ist";
CM_ SG_ 976 FT_gesafet "Im Zustand Safe wird auch das Signal FT_verriegelt = 1 gesendet";
CM_ SG_ 976 FT_HD_Taste "Taste in der Fahrertür zum Öffnen des Heckschlosses";
CM_ SG_ 976 FT_HD_Taste_2 "2. HD-Taste im Bedienfeld 
Funktion: Heckdeckel schließen";
CM_ SG_ 976 FT_IRUE_Taste "Betätigung IRUE-Taster (Innenraumüberwachung)
MQB: Bei Verbau eines einzelnen Taster zur Deaktivierung von IRUE und NGS wird dieses Signal als Deaktivierungsanforderung beider DWA-Alarmquellen gesendet.";
CM_ SG_ 976 FT_Kisi_Fehler "Fehlerstatus Kindersicherungsfunktion";
CM_ SG_ 976 FT_Kisi_li_aktiv "Aktivierungsstatus der Kindersicherung links";
CM_ SG_ 976 FT_Kisi_re_aktiv "Aktivierungsstatus der Kindersicherung rechts";
CM_ SG_ 976 FT_Kisi_Taster_li "Linker Kisi Taster betaetigt";
CM_ SG_ 976 FT_Kisi_Taster_re "Rechter Kisi Taster betaetigt";
CM_ SG_ 976 FT_Lock_Taster "Verriegelungstaster betätigt";
CM_ SG_ 976 FT_Oben_Block_erw "Fensterheber in Blockerwartung oben";
CM_ SG_ 976 FT_Schliesstaster "Vorhalt";
CM_ SG_ 976 FT_Schluesselschalter_auf "Schlüsselschalter Richtung auf betätigt";
CM_ SG_ 976 FT_SP_ausgerastet "Spiegel ausgerastet";
CM_ SG_ 976 FT_Sp_Blk_def "Blinker am Spiegel defekt";
CM_ SG_ 976 FT_Sp_Heizung_Anf "Kundenanforderung der Außenspiegelheizung Fahrertür";
CM_ SG_ 976 FT_SP_Heizung_Status "Status der Spiegelheizung";
CM_ SG_ 976 FT_SP_ht_aktiv "Spiegelverstellung in Richtung hoch/tief aktiv";
CM_ SG_ 976 FT_SP_lr_aktiv "Spiegelverstellung in Richtung links/rechts aktiv";
CM_ SG_ 976 FT_Sperrklinke "Vorraste für Schloß

zwischen Vor- und Hauptraste Signal kurz auf 1, danach wieder auf 0 wenn Tür in Hauptraste (Tür ist sicher zu wenn Sperrklinke und Türkontakt auf 0 sind)";
CM_ SG_ 976 FT_SWA_Taster "SWA/ASW Taster Fahrertür";
CM_ SG_ 976 FT_TAG_betaetigt "Türaussengriff

wird nicht im MLB-B8 verwendet";
CM_ SG_ 976 FT_TD_Taste "Tankdeckelentriegelungs-Taste betätigt";
CM_ SG_ 976 FT_TD_Taste_Fehler "Fehlerstatus des Tankdeckelentriegelungstasters. Wird bei Drucktankkonzepten vom MSG zusammen mit dem Signal FT_TD_Taste ausgewertet, um Tankbereitschaft herzustellen.
Der Fehler beschreibt einen hängenden TD_Taster. Ein Kurzschluss oder Leitungsunterbre";
CM_ SG_ 976 FT_TIG_betaetigt "Türinnengriff

wird nicht im MLB-B8 verwendet";
CM_ SG_ 976 FT_Tuer_geoeffnet "Zeigt eine geöffnete Tür an";
CM_ SG_ 976 FT_Tuerschloss_defekt "Das Fahrertürschloss ist nicht mehr funktionsfähig.";
CM_ SG_ 976 FT_UEKB_aktiviert "Überschutzbegrenzungskraft bei Reversieren";
CM_ SG_ 976 FT_Unlock_Taster "Entriegelungstaster betätigt";
CM_ SG_ 976 FT_Unten_Block_erw "Fensterheber in Blockerwartung unten";
CM_ SG_ 976 FT_verriegelt "Zeigt eine verriegelte Tür an ( Status wird erst nach vollständiger Schlossansteuerung ausgegeben (<=1,5sek))";
CM_ SG_ 976 FT_Zuziehhilfe_aktiv "Zuziehhilfe aktiv";
CM_ SG_ 976 SSR_Temp_Freigabe "Freigabe des Seitenscheibenrollos. Bit wird  für die Deaktivierung des SSR bei Innenraumtemperaturen kleiner -10 Grad verwendet.";
CM_ SG_ 976 SWA_HMI_Diagnose "SWA HMI Diagnose beim TSG";

CM_ SG_ 975 ASW_Warnung_aktiv_HBFS "Abschaltung der Ambientefunktion Tür hinten der Beifahrerseite bei aktiver ASW Warnung an der Fahrertür";
CM_ SG_ 975 HBFS_FH_Bew_hoch "HBFS Fenster bewegt sich in Richtung hoch";
CM_ SG_ 975 HBFS_FH_Bew_tief "HBFS Fenster bewegt sich in Richtung tief";
CM_ SG_ 975 HBFS_FH_Block "Fensterscheibe befindet sich im mechanischen Block (oben oder unten)";
CM_ SG_ 975 HBFS_FH_Fang "Fangbereich ist 4mm von oberer Lippendichtung";
CM_ SG_ 975 HBFS_FH_normiert "Die Position der Fensterheberscheibe ist bekannt.";
CM_ SG_ 975 HBFS_FH_Oeffnung "Gibt den Fensteröffnungswert in % an.";
CM_ SG_ 975 HBFS_FH_S_AutoHoch "Betaetigung FH Schalter auto tief ";
CM_ SG_ 975 HBFS_FH_S_AutoTief "Betaetigung FH Schalter auto hoch";
CM_ SG_ 975 HBFS_FH_S_HFS_AutoHoch "Automatisches Hochfahren der Seitenscheibe HFS";
CM_ SG_ 975 HBFS_FH_S_HFS_AutoTief "Automatisches Absenken der Seitenscheibe HFS";
CM_ SG_ 975 HBFS_FH_S_HFS_ManHoch "Manuelles Hochfahren der Seitenscheibe HFS";
CM_ SG_ 975 HBFS_FH_S_HFS_ManTief "Manuelles Absenken der Seitenscheibe HFS";
CM_ SG_ 975 HBFS_FH_S_ManHoch "Betaetigung FH Schalter man hoch ";
CM_ SG_ 975 HBFS_FH_S_ManTief "Betaetigung FH Schalter man tief";
CM_ SG_ 975 HBFS_FH_Thermo "gibt an ob Fensterheber im Thermoschutz ist";
CM_ SG_ 975 HBFS_gesafet "HBFS Tuer gesafet.
Im Zustand Safe wird auch das Signal HBFS_verriegelt = 1 gesendet.";
CM_ SG_ 975 HBFS_Heckrollotaster_betaetigt "Verfahren des Heckrollos in Richtung Hoch

Bei Einfachtaster wird Bit als Togglebit verwendet (Heckrollo hoch, tief)";
CM_ SG_ 975 HBFS_Lock_Taster "Betaetigung Lock-Taster";
CM_ SG_ 975 HBFS_Lock_Taster_inv "Lock Taster nicht betätigt";
CM_ SG_ 975 HBFS_MRollo_Schalter "  | MRollo2
-----------------------------
0 | nicht_betaetigt
1 | (m) Zu
2 | (a) Zu
3 | (m) Auf
4 | (a) Auf
5 | Schalter nicht verfuegbar
6 | Init
7 | Fehlerfall";
CM_ SG_ 975 HBFS_Oben_Block_erw "Fensterheber in Blockerwartung oben";
CM_ SG_ 975 HBFS_SAD_Schalter "  |   Ausstelldach MD3
-----------------------------
0 | nicht_betaetigt
1 |
2 |
3 |
4 |
5 | (m) Auf
6 | (a) Auf
7 | (m) Zu
8 | (a) Zu
13| Schalter nicht verfuegbar
14| Init
15| Fehlerfall";
CM_ SG_ 975 HBFS_Seitenrollo_tief "Seitenrollo in Bewegung Richtung tief";
CM_ SG_ 975 HBFS_Sperrklinke "Vorraste für Schloß

zwischen Vor- und Hauptraste Signal kurz auf 1, danach wieder auf 0 wenn Tür in Hauptraste (Tür ist sicher zu wenn Sperrklinke und Türkontakt auf 0 sind)";
CM_ SG_ 975 HBFS_Status_eTAG "Status des elektrischen Tueraussengriffes Tuer Beifahrerseite hinten";
CM_ SG_ 975 HBFS_Status_KiSi "Status Kindersicherung HBFS
";
CM_ SG_ 975 HBFS_Status_KiSi_inv "Inverser Status der elektrischen Kindersicherung Beifahrerseite hinten";
CM_ SG_ 975 HBFS_TAG_betaetigt "Betaetigung Türaussengriff";
CM_ SG_ 975 HBFS_TIG_betaetigt "Betaetigung Tuerinnengriff";
CM_ SG_ 975 HBFS_TIG_betaetigt_schliessen "Türinnenbetätigung, Taster Tür schließen.";
CM_ SG_ 975 HBFS_Tuer_geoeffnet "HBFS Tuer geoeffnet";
CM_ SG_ 975 HBFS_Tuer_Status "Türstatus mit Fehler und Initwert";
CM_ SG_ 975 HBFS_Tuer_Status_QBit "Dieses Bit gibt die Zuverlässigkeit des Türkontakts an. Ein auf dieses Bit folgender Fehlereintrag ist mit dem Sender des Bits abzustimmen (gültig ab PPE).";
CM_ SG_ 975 HBFS_Tueroeffnen_Warnung "Bit wird gesetzt, wenn Tür während der Fahrt geoeffnet werden soll.";
CM_ SG_ 975 HBFS_Tuerschloss_defekt "Das hintere Tuerschloss auf der Beifahrerseite ist nicht mehr funktionsfähig.";
CM_ SG_ 975 HBFS_UEKB_aktiviert "Überschutzbegrenzungskraft bei Reversieren";
CM_ SG_ 975 HBFS_Unlock_Taster "Betaetigung Unlock Taster";
CM_ SG_ 975 HBFS_Unten_Block_erw "Fensterheber in Blockerwartung unten";
CM_ SG_ 975 HBFS_verriegelt "Verriegelungsstatus Tür";
CM_ SG_ 975 HBFS_Zuziehhilfe_aktiv "Zuziehhilfe aktiv";
CM_ SG_ 975 MTHBFS_M_Taste "Betätigung M-Taste HBFS";
CM_ SG_ 975 MTHBFS_Pos1 "Betätigung Postionstaste 1 HBFS";
CM_ SG_ 975 MTHBFS_Pos2 "Betätigung Postionstaste 2 HBFS
";
CM_ SG_ 975 MTHBFS_Pos3 "Betätigung Postionstaste 3 HBFS";
CM_ SG_ 975 SSR_HBFS_Pos_Unten "Signal für die 'Global Close'. Über dieses Bit wissen die anderen TSGs, ob der SSR oder der FH verfahren werden darf.";

CM_ SG_ 974 ASW_Warnung_aktiv_HFS "Abschaltung der Ambientefunktion Tür hinten der Fahrerseite bei aktiver ASW Warnung an der Fahrertür";
CM_ SG_ 974 HFS_FH_Bew_hoch "HFS Fenster bewegt sich in Richtung hoch";
CM_ SG_ 974 HFS_FH_Bew_tief "HFS Fenster bewegt sich in Richtung tief";
CM_ SG_ 974 HFS_FH_Block "Fensterscheibe befindet sich im mechanischen Block (oben oder unten)";
CM_ SG_ 974 HFS_FH_Fang "Fangbereich ist 4mm von oberer Lippendichtung";
CM_ SG_ 974 HFS_FH_normiert "Die Position der Fensterheberscheibe ist bekannt.";
CM_ SG_ 974 HFS_FH_Oeffnung "Gibt den Fensteröffnungswert in % an.";
CM_ SG_ 974 HFS_FH_S_AutoHoch "Betaetigung FH Schalter auto hoch";
CM_ SG_ 974 HFS_FH_S_AutoTief "Betaetigung FH Schalter auto tief ";
CM_ SG_ 974 HFS_FH_S_HBFS_AutoHoch "Automatisches Hochfahren der Seitenscheibe HBFS";
CM_ SG_ 974 HFS_FH_S_HBFS_AutoTief "Automatisches Absenken der Seitenscheibe HBFS";
CM_ SG_ 974 HFS_FH_S_HBFS_ManHoch "Manuelles Hochfahren der Seitenscheibe HBFS";
CM_ SG_ 974 HFS_FH_S_HBFS_ManTief "Manuelles Absenken der Seitenscheibe HBFS";
CM_ SG_ 974 HFS_FH_S_ManHoch "Betaetigung FH Schalter man hoch ";
CM_ SG_ 974 HFS_FH_S_ManTief "Betaetigung FH Schalter man tief";
CM_ SG_ 974 HFS_FH_Thermo "gibt an ob Fensterheber im Thermoschutz ist";
CM_ SG_ 974 HFS_gesafet "HFS Tuer gesafet.
Im Zustand Safe wird auch das Signal HFS_verriegelt = 1 gesendet.";
CM_ SG_ 974 HFS_Heckrollotaster_betaetigt "Verfahren des Heckrollos in Richtung Hoch

Bei Einfachtaster wird Bit als Togglebit verwendet (Heckrollo hoch, tief)";
CM_ SG_ 974 HFS_Lock_Taster "Betätigung Lock-Taster";
CM_ SG_ 974 HFS_Lock_Taster_inv "Lock Taster nicht betätigt";
CM_ SG_ 974 HFS_MRollo_Schalter "  | MRollo2
-----------------------------
0 | nicht_betaetigt
1 | (m) Zu
2 | (a) Zu
3 | (m) Auf
4 | (a) Auf
5 | Schalter nicht verfuegbar
6 | Init
7 | Fehlerfall";
CM_ SG_ 974 HFS_Oben_Block_erw "Fensterheber in Blockerwartung oben";
CM_ SG_ 974 HFS_SAD_Schalter "  |   Ausstelldach MD3
-----------------------------
0 | nicht_betaetigt
1 |
2 |
3 |
4 |
5 | (m) Auf
6 | (a) Auf
7 | (m) Zu
8 | (a) Zu
13| Schalter nicht verfuegbar
14| Init
15| Fehlerfall";
CM_ SG_ 974 HFS_Seitenrollo_hoch "Seitenrollo in Bewegung Richtung hoch";
CM_ SG_ 974 HFS_Seitenrollo_tief "Seitenrollo in Bewegung Richtung tief";
CM_ SG_ 974 HFS_Sperrklinke "Vorraste für Schloß

zwischen Vor- und Hauptraste Signal kurz auf 1, danach wieder auf 0 wenn Tür in Hauptraste (Tür ist sicher zu wenn Sperrklinke und Türkontakt auf 0 sind)";
CM_ SG_ 974 HFS_Status_eTAG "Status des elektrischen Tueraussengriffes Tuer Fahrerseite hinten";
CM_ SG_ 974 HFS_Status_KiSi "Status Kindersicherung hinten Fahrerseite";
CM_ SG_ 974 HFS_TAG_betaetigt "Betaetigung Türaussengriff";
CM_ SG_ 974 HFS_TCR_Mode_aktiv "Signal zeigt eine aktive mechanische Redundanz am Türschloss an.";
CM_ SG_ 974 HFS_TIG_betaetigt "Betaetigung Türinnengriff";
CM_ SG_ 974 HFS_Tuer_geoeffnet "HFS Tuer geoeffnet";
CM_ SG_ 974 HFS_Tuer_Status "Türstatus mit Fehler und Initwert";
CM_ SG_ 974 HFS_Tuer_Status_QBit "Dieses Bit gibt die Zuverlässigkeit des Türkontakts an. Ein auf dieses Bit folgender Fehlereintrag ist mit dem Sender des Bits abzustimmen (gültig ab PPE).";
CM_ SG_ 974 HFS_Tueroeffnen_Warnung "Bit wird gesetzt, wenn Tür während der Fahrt geoeffnet werden soll.";
CM_ SG_ 974 HFS_Tuerschloss_defekt "Das hintere Tuerschloss auf der Fahrerseite ist nicht mehr funktionsfähig.";
CM_ SG_ 974 HFS_UEKB_aktiviert "Überschutzbegrenzungskraft bei Reversieren";
CM_ SG_ 974 HFS_Unlock_Taster "Betaetigung Unlock Taster";
CM_ SG_ 974 HFS_Unten_Block_erw "Fensterheber in Blockerwartung unten";
CM_ SG_ 974 HFS_verriegelt "HFS Tuer verriegelt";
CM_ SG_ 974 HFS_Zuziehhilfe_aktiv "Zuziehhilfe aktiv";
CM_ SG_ 974 MTHFS_M_Taste "Betätigung M-Taste HFS";
CM_ SG_ 974 MTHFS_Pos1 "Betätigung Postionstaste 1 HFS";
CM_ SG_ 974 MTHFS_Pos2 "Betätigung Postionstaste 2 HFS
";
CM_ SG_ 974 MTHFS_Pos3 "Betätigung Postionstaste 3 HFS";
CM_ SG_ 974 SSR_HFS_Pos_Unten "Signal für die 'Global Close'. Über dieses Bit wissen die anderen TSGs, ob der SSR oder der FH verfahren werden darf.";

CM_ SG_ 995 VD_SpannungsAnf "Anforderung Forderung des Verdecks zur Spannungsanhebung des Bordnetzes.";
CM_ SG_ 995 Verdeck_01_BZ "4bit Botschaftszähler, wird mit jeder Sendebotschaft inkrementiert";
CM_ SG_ 995 Verdeck_01_CRC "Für MLB:
Berechnung siehe Lastenheft 'Kommunikationsabsicherung für FlexRay und CAN'
Ab MQB und MLBevo:
Berechnung siehe Lastenheft 'End-to-End Kommunikationsabsicherung'

Endwerte siehe Begleitdokument 'S-PDU Kennungsfolgen'";
CM_ SG_ 995 VS_BFS_AutoHoch "automatischer Hochlauf des BFS Fenster ausgelöst durch die Verdecksteuerung";
CM_ SG_ 995 VS_BFS_AutoTief "automatischer Tieflauf des BFS Fenster ausgelöst durch die Verdecksteuerung";
CM_ SG_ 995 VS_BFS_ManHoch "manueller Hochlauf des BFS Fenster ausgelöst durch die Verdecksteuerung";
CM_ SG_ 995 VS_BFS_ManTief "manueller Tieflauf des BFS Fenster ausgelöst durch die Verdecksteuerung";
CM_ SG_ 995 VS_Buzzer "Buzzeransteuerung: 'Buzzeransteuerung' für Gong 200ms (Kombi)";
CM_ SG_ 995 VS_FH_BT_Langhub "Ansteuerung Fensterheber vom Verdecksteuergeraet";
CM_ SG_ 995 VS_FH_FT_Langhub "Ansteuerung Fensterheber vom Verdecksteuergeraet";
CM_ SG_ 995 VS_FH_HBFS_Langhub "Ansteuerung Fensterheber vom Verdecksteuergeraet";
CM_ SG_ 995 VS_FH_HFS_Langhub "Ansteuerung Fensterheber vom Verdecksteuergeraet";
CM_ SG_ 995 VS_FS_AutoHoch "automatischer Hochlauf des FS Fenster ausgelöst durch die Verdecksteuerung";
CM_ SG_ 995 VS_FS_AutoTief "automatischer Tieflauf des FS Fenster ausgelöst durch die Verdecksteuerung";
CM_ SG_ 995 VS_FS_ManHoch "manueller Hochlauf des FS Fenster ausgelöst durch die Verdecksteuerung";
CM_ SG_ 995 VS_FS_ManTief "manueller Tieflauf des FS Fenster ausgelöst durch die Verdecksteuerung";
CM_ SG_ 995 VS_Hardtop "Hardtop montiert";
CM_ SG_ 995 VS_HBFS_AutoHoch "automatischer Hochlauf des HBFS Fenster ausgelöst durch die Verdecksteuerung";
CM_ SG_ 995 VS_HBFS_AutoTief "automatischer Tieflauf des HBFS Fenster ausgelöst durch die Verdecksteuerung";
CM_ SG_ 995 VS_HBFS_ManHoch "manueller Hochlauf des HBFS Fenster ausgelöst durch die Verdecksteuerung";
CM_ SG_ 995 VS_HBFS_ManTief "manueller Tieflauf des HBFS Fenster ausgelöst durch die Verdecksteuerung";
CM_ SG_ 995 VS_HD_sperren "Bei gesetztem Signal wird der Kofferraum/Heckdeckel durch den BCM2 nicht entriegelt werden.";
CM_ SG_ 995 VS_Heckschloss_auf "Signal wird gesetzt, wenn fuer einen Verdeckbetrieb das Öffnen des Heckschlosses erforderlich ist.";
CM_ SG_ 995 VS_HFS_AutoHoch "automatischer Hochlauf des HFS Fenster ausgelöst durch die Verdecksteuerung";
CM_ SG_ 995 VS_HFS_AutoTief "automatischer Tieflauf des HFS Fenster ausgelöst durch die Verdecksteuerung";
CM_ SG_ 995 VS_HFS_ManHoch "manueller Hochlauf des HFS Fenster ausgelöst durch die Verdecksteuerung";
CM_ SG_ 995 VS_HFS_ManTief "manueller Tieflauf des HFS Fenster ausgelöst durch die Verdecksteuerung";
CM_ SG_ 995 VS_HHS_enable "Fehlende Beschreibung (Import)";
CM_ SG_ 995 VS_Lampe_Blk "Ansteuerung Lampe im Kombi

Wird aktiviert bei Aufprüfen, Verdecklauf und Fehlerfall (blinkend).


";
CM_ SG_ 995 VS_StartStopp_Info "Stopp-Freigabe und Start-Anforderung an den Start-Stopp-Koordinator";
CM_ SG_ 995 VS_VD_Bew_auf "



";
CM_ SG_ 995 VS_VD_Bew_zu "


";
CM_ SG_ 995 VS_VD_entriegelt "Zustand des Verdeck entriegelt";
CM_ SG_ 995 VS_VD_Fehler "Fehlerzustand Verdeck";
CM_ SG_ 995 VS_VD_offen_ver "Zustand des Verdecks verriegelt und offen";
CM_ SG_ 995 VS_VD_zu_ver "
";
CM_ SG_ 995 VS_VD_Zwischenposition "Verdeck in Zwischenposition";
CM_ SG_ 995 VS_VDKD_auf "Signal wird gesetzt, wenn der Verdeckkastendeckel vollstaendig geoeffnet ist



";
CM_ SG_ 995 VS_Verdeck_Anf "Verdeckanforderung (Signalisierung der Bereitschaft zur Verdeckbetaetigung ueber Komfortfunktion)";
CM_ SG_ 995 VS_Windschott_nicht_abgelegt "Windschott ist aufgestellt, in Zwischenposition oder die Position ist unbekannt";
CM_ SG_ 995 VSG_Meldungen "Meldungen fuers Kombi lt. konzernübergreifender Abstimmung

0 -> keine Meldung
1 -> 'Verdeckbetrieb RDW aktiv'
2 -> 'Verdeckbetrieb NAR aktiv'
3 -> 'stehendes Verdeck in Zwischenposition (ZP)'
4 -> 'autom. Verdeck in ZP und KL15 aus'
5 -> 'manuelle";

CM_ SG_ 1716 VIN_01_MUX "Achtung:
Die Botschaft ist nicht linear gemultiplext!!!
Sondern 0,1,0,2,0, usw.";
CM_ SG_ 1716 VIN_1 "Initwert:
0x2D bei Fahrzeugen mit Wegfahrsperrengeneration >= 5 
0x58 bei Fahrzeugen mit Wegfahrsperrengeneration < 5 (z.B. WFS-4)";
CM_ SG_ 1716 VIN_10 "Initwert:
0x2D bei Fahrzeugen mit Wegfahrsperrengeneration >= 5 
0x58 bei Fahrzeugen mit Wegfahrsperrengeneration < 5 (z.B. WFS-4)";
CM_ SG_ 1716 VIN_11 "Initwert:
0x2D bei Fahrzeugen mit Wegfahrsperrengeneration >= 5 
0x58 bei Fahrzeugen mit Wegfahrsperrengeneration < 5 (z.B. WFS-4)";
CM_ SG_ 1716 VIN_12 "Initwert:
0x2D bei Fahrzeugen mit Wegfahrsperrengeneration >= 5 
0x58 bei Fahrzeugen mit Wegfahrsperrengeneration < 5 (z.B. WFS-4)";
CM_ SG_ 1716 VIN_13 "Initwert:
0x2D bei Fahrzeugen mit Wegfahrsperrengeneration >= 5 
0x58 bei Fahrzeugen mit Wegfahrsperrengeneration < 5 (z.B. WFS-4)";
CM_ SG_ 1716 VIN_14 "Initwert:
0x2D bei Fahrzeugen mit Wegfahrsperrengeneration >= 5 
0x58 bei Fahrzeugen mit Wegfahrsperrengeneration < 5 (z.B. WFS-4)";
CM_ SG_ 1716 VIN_15 "Initwert:
0x2D bei Fahrzeugen mit Wegfahrsperrengeneration >= 5 
0x58 bei Fahrzeugen mit Wegfahrsperrengeneration < 5 (z.B. WFS-4)";
CM_ SG_ 1716 VIN_16 "Initwert:
0x2D bei Fahrzeugen mit Wegfahrsperrengeneration >= 5 
0x58 bei Fahrzeugen mit Wegfahrsperrengeneration < 5 (z.B. WFS-4)";
CM_ SG_ 1716 VIN_17 "Initwert:
0x2D bei Fahrzeugen mit Wegfahrsperrengeneration >= 5 
0x58 bei Fahrzeugen mit Wegfahrsperrengeneration < 5 (z.B. WFS-4)";
CM_ SG_ 1716 VIN_2 "Initwert:
0x2D bei Fahrzeugen mit Wegfahrsperrengeneration >= 5 
0x58 bei Fahrzeugen mit Wegfahrsperrengeneration < 5 (z.B. WFS-4)";
CM_ SG_ 1716 VIN_3 "Initwert:
0x2D bei Fahrzeugen mit Wegfahrsperrengeneration >= 5 
0x58 bei Fahrzeugen mit Wegfahrsperrengeneration < 5 (z.B. WFS-4)";
CM_ SG_ 1716 VIN_4 "Initwert:
0x2D bei Fahrzeugen mit Wegfahrsperrengeneration >= 5 
0x58 bei Fahrzeugen mit Wegfahrsperrengeneration < 5 (z.B. WFS-4)";
CM_ SG_ 1716 VIN_5 "Initwert:
0x2D bei Fahrzeugen mit Wegfahrsperrengeneration >= 5 
0x58 bei Fahrzeugen mit Wegfahrsperrengeneration < 5 (z.B. WFS-4)";
CM_ SG_ 1716 VIN_6 "Initwert:
0x2D bei Fahrzeugen mit Wegfahrsperrengeneration >= 5 
0x58 bei Fahrzeugen mit Wegfahrsperrengeneration < 5 (z.B. WFS-4)";
CM_ SG_ 1716 VIN_7 "Initwert:
0x2D bei Fahrzeugen mit Wegfahrsperrengeneration >= 5 
0x58 bei Fahrzeugen mit Wegfahrsperrengeneration < 5 (z.B. WFS-4)";
CM_ SG_ 1716 VIN_8 "Initwert:
0x2D bei Fahrzeugen mit Wegfahrsperrengeneration >= 5 
0x58 bei Fahrzeugen mit Wegfahrsperrengeneration < 5 (z.B. WFS-4)";
CM_ SG_ 1716 VIN_9 "Initwert:
0x2D bei Fahrzeugen mit Wegfahrsperrengeneration >= 5 
0x58 bei Fahrzeugen mit Wegfahrsperrengeneration < 5 (z.B. WFS-4)";

CM_ SG_ 916 GE_Sollgang "Signalisiert den Sollgang, in den getippt werden soll. Abhängig vom Signal 'WBA_eing_Gang_02' und dem Sollgang kann dann das Kombi die Hochschaltempfehlung in Tip darstellen.";
CM_ SG_ 916 GE_Stoppverbot_Anz_01 "Dieses Signal gibt die detaillierte Begründung für ein Stoppverbot vom Getriebesteuergerät an.";
CM_ SG_ 916 GE_Stoppverbot_Anz_02 "Dieses Signal gibt die detaillierte Begründung für ein Stoppverbot vom Getriebesteuergerät an.";
CM_ SG_ 916 GE_Stoppverbot_Anz_03 "Dieses Signal gibt die detaillierte Begründung für ein Stoppverbot vom Getriebesteuergerät an.";
CM_ SG_ 916 GE_Stoppverbot_Anz_04 "Dieses Signal gibt die detaillierte Begründung für ein Stoppverbot vom Getriebesteuergerät an.";
CM_ SG_ 916 GE_Stoppverbot_Anz_05 "Dieses Signal gibt die detaillierte Begründung für ein Stoppverbot vom Getriebesteuergerät an.";
CM_ SG_ 916 GE_Stoppverbot_Anz_06 "Dieses Signal gibt die detaillierte Begründung für ein Stoppverbot vom Getriebesteuergerät an.";
CM_ SG_ 916 GE_Stoppverbot_Anz_07 "Dieses Signal gibt die detaillierte Begründung für ein Stoppverbot vom Getriebesteuergerät an.";
CM_ SG_ 916 GE_Stoppverbot_Anz_Std "Dieses Signal gibt die detaillierte Begründung für ein Stoppverbot vom Getriebesteuergerät an.";
CM_ SG_ 916 GE_Tipschaltempf_verfuegbar "Signalisierung, ob eine Hochschaltempfehlung im Tipmodus verfügbar ist oder nicht.";
CM_ SG_ 916 GE_Wiederstart_Anz_Std "Dieses Signal gibt die detaillierte Begründung für einen Wiederstart vom Getriebesteuergerät an. ";
CM_ SG_ 916 WBA_03_CRC "Für MLB:
'Berechnung siehe Lastenheft 'Kommunikationsabsicherung für FlexRay und CAN''

Ab MQB und MLBevo:
'Berechnung siehe Lastenheft 'End-to-End Kommunikationsabsicherung''

Endwerte siehe Begleitdokument 'S-PDU Kennungsfolgen'";
CM_ SG_ 916 WBA_Blinken "Dieses Bit steuert die Fehlerlampe an oder wird zum Blinken der WBA-Anzeige genutzt - nur falls WBA_Senderkennung = 00 (GSG)
";
CM_ SG_ 916 WBA_eing_Gang_02 "Das Automatikgetriebe gibt den aktuell eingelegten Gang aus.
Besonderheiten:
0x0 = marktabhängig wird auf Ganganzeige zur Fahrstufe komplett verzichtet
0xA = kurzzeitige Unterdrückung der Ganganzeige (z. B. Segeln, Zwischenstellung, etc.)";
CM_ SG_ 916 WBA_Fahrstufe_02 "Bei Automatgetrieben wird in diesem Signal die aktuelle anzuzeigende Fahrstufe ausgegeben.

Die Signalkodierungen 0x9, 0xA und 0xB werden im MSS-R8NF und MQB-A1/B/A2 verwendet.

Die Signalkodierungen 0xC und 0xD werden nur im MQB-A1/B/A2 verwendet.
";
CM_ SG_ 916 WBA_GE_Texte "Fahrerhinweise für das Kombi";
CM_ SG_ 916 WBA_GE_Texte_02 "Fahrerhinweise für das Kombi";
CM_ SG_ 916 WBA_GE_Texte_03 "Launch control functionality stauts (performance strategy and smoke stratgey)";
CM_ SG_ 916 WBA_GE_Warnung_02 "Prioritätswarnungen Getriebe";
CM_ SG_ 916 WBA_GE_Zusatzwarnungen "Prioritaetswarnungen Getriebe an Kombi
Audi MLB Wertebereich 0 bis 3
VW MQB Projekte verwenden nur den Wertebereich 0 bis 2
VW MQB Getriebefehler werden über das Signal  GE_Warnungen_02 gesendet.";
CM_ SG_ 916 WBA_Schaltschema "Bei Automatikgetrieben wird in diesem Signal die aktuelle, eingelegte Fahrstufe (=Wählhebelposition) ausgegeben.";
CM_ SG_ 916 WBA_Segeln_aktiv "Getriebe geht in den Segelbetrieb";
CM_ SG_ 916 WBA_ZielFahrstufe "Zielfahrprogramm (Darstellung), für getipptes S/E/M mit neuem Wählhebel im MQB";

CM_ SG_ 1702 BCM1_SRA_aktiv "Status Scheinwerferreinigungsanlage";
CM_ SG_ 1702 Heckwischer_Anforderung "Das Signal beschreibt die Anforderung an den Signalausgang im BCM2 zur Ansteuerung des Heckwischers.";
CM_ SG_ 1702 Waschen_vorne_aktiv "Status: Waschen vorne aktiv";
CM_ SG_ 1702 Wischer1_Wischgeschwindigkeit "aktuelle, durch Sensorik gemessene Wischgeschwindigkeit";
CM_ SG_ 1702 Wischer_Anzeigetext "Das Signal fordert einen Kombi-Pop-Up mit entsprechenden Texten an";
CM_ SG_ 1702 Wischer_vorne_aktiv "Status: Wischer vorne";
CM_ SG_ 1702 Wischer_vorne_blockiert "Blockade Wischer vorne (z.B. durch Schnee)";
CM_ SG_ 1702 Wischer_vorne_defekt "Fehlerstatus Wischer vorne (Anzeige im Kombi)";
CM_ SG_ 1702 Wischer_vorne_Normal "Wischer Front normal aktiv";
CM_ SG_ 1702 Wischer_vorne_Parklage "Wischer Front in Parklage";
CM_ SG_ 1702 Wischer_vorne_Schnell "Wischer vorne schnell aktiv";
CM_ SG_ 1702 WWSs_01_upd "Update-Bit für die LIN-Botschaft WWSs_01.

Betroffene Signale:

Wischer_vorne_aktiv
Wischer1_Wischgeschwindigkeit";

CM_ SG_ 1140 MMI_State "Powerstate des Zentralrechners. MMI_Off wird im Zustand dead mode gesendet.";
CM_ SG_ 1140 SI_ICAN "MQB: Busruhe ICAN.
E3: Busruhe ABCAN.";
CM_ SG_ 1140 WLC1_Systemzustand "0 = Wireless Charger off (Message produced by HMI)
1 = Wireless Charger on (Message produced by HMI)";
CM_ SG_ 1140 WLC2_Systemzustand "0 = Wireless Charger off
1 = Wireless Charger on";
CM_ SG_ 1140 ZR_DimOffs_DU_1 "Dimmungs-Offset der Display Unit.";
CM_ SG_ 1140 ZR_DimOffs_DU_2 "Dimmungs-Offset der Display Unit.";
CM_ SG_ 1140 ZR_DimOffs_DU_3 "Dimmungs-Offset der Display Unit.";
CM_ SG_ 1140 ZR_DimOffs_DU_4 "Dimmungs-Offset der Display Unit.";
CM_ SG_ 1140 ZR_LeistungSaeule "Ladeleistung der geplanten Ladesäule";
CM_ SG_ 1140 ZR_Lenkerposition "Ueber Diagnose (Codierung) im Zentralrechner eingespeicherte Lenkerposition
  ";
CM_ SG_ 1140 ZR_SOCSaeule "SOC an der Ladesäule am nächsten geplanten Ladestopp";
CM_ SG_ 1140 ZR_SpannungSaeule "Ladespannung an der Ladesäule am nächsten geplanten Ladestopp";
CM_ SG_ 1140 ZR_State_DU_1 "Kontrollbit für Display, Hintergrundbeleuchtung aus, Hintergrundbeleuchtung an, Energiesparmodus.
";
CM_ SG_ 1140 ZR_State_DU_2 "Kontrollbit für Display, Hintergrundbeleuchtung aus, Hintergrundbeleuchtung an, Energiesparmodus.
";
CM_ SG_ 1140 ZR_State_DU_3 "Kontrollbit für Display, Hintergrundbeleuchtung aus, Hintergrundbeleuchtung an, Energiesparmodus.
";
CM_ SG_ 1140 ZR_State_DU_4 "Kontrollbit für Display, Hintergrundbeleuchtung aus, Hintergrundbeleuchtung an, Energiesparmodus.";
CM_ SG_ 1140 ZR_t_naechsteLadung "Dauer bis zur nächsten Schnellladung in Minuten";
CM_ SG_ 1140 ZR_WecktGesp "Befehl zum Sperren der Wecktasten am Bedienteil.";

CM_ SG_ 2527679655 MMI_StartupAnimation "Synchronisierung der Startupanimation zwischen MMI und Kombi";
CM_ SG_ 2527679655 ZR_SOC_Weiterfahrt "SOC auf den an der Ladesäule am nächsten geplanten Ladestopp geladen werden soll.";

CM_ SG_ 388 BCM_BF_Spg_Absenkung "Spiegelabsenkung Beifahrerseite";
CM_ SG_ 388 BCM_Spg_Synchron "Anforderung zur Aktivierung der synchronen Spiegelverstellung";
CM_ SG_ 388 FH_BT_hoch "Freigabeinformation fuer die FH-Komfortfunktion";
CM_ SG_ 388 FH_BT_tief "Freigabeinformation fuer die FH-Komfortfunktion";
CM_ SG_ 388 FH_FT_hoch "Freigabeinformation fuer die FH-Komfortfunktion";
CM_ SG_ 388 FH_FT_tief "Freigabeinformation fuer die FH-Komfortfunktion";
CM_ SG_ 388 FH_HBFS_hoch "Freigabeinformation fuer die FH-Komfortfunktion";
CM_ SG_ 388 FH_HBFS_tief "Freigabeinformation fuer die FH-Komfortfunktion";
CM_ SG_ 388 FH_HFS_hoch "Freigabeinformation fuer die FH-Komfortfunktion";
CM_ SG_ 388 FH_HFS_tief "Freigabeinformation fuer die FH-Komfortfunktion";
CM_ SG_ 388 VIP_Freigabe "Vituelles Pedal ist über HMI freigeschaltet.";
CM_ SG_ 388 VIP_Sensor_betaetigt "Heckentriegelung durch die Bedienstelle Virtuelles Pedal(VIP) erkannt. Der VIP Sensor hat eine Fusskickbewegung erkannt und es wurde ein Kessy - Schlüssel im Heckaussenbereich erkannt.";
CM_ SG_ 388 ZV_01_CRC "Für MLB:
'Berechnung siehe Lastenheft 'Kommunikationsabsicherung für FlexRay und CAN''

Ab MQB und MLBevo:
'Berechnung siehe Lastenheft 'End-to-End Kommunikationsabsicherung''

Endwerte siehe Begleitdokument 'S-PDU Kennungsfolgen'";
CM_ SG_ 388 ZV_auf_BT "ZV Schliessstelle";
CM_ SG_ 388 ZV_auf_FT "ZV Schliessstelle";
CM_ SG_ 388 ZV_auf_Funk "ZV Schliessstelle";
CM_ SG_ 388 ZV_auf_Kessy "ZV Schliessstelle";
CM_ SG_ 388 ZV_auto_Ansteuerung "Kennung für die automatische Ansteuerung der Zentralverriegelung (Autolock/Autounlock)";
CM_ SG_ 388 ZV_BT_entriegeln "Beifahrertür entriegeln (Anforderung ZV)";
CM_ SG_ 388 ZV_BT_verriegeln "Verriegelungsanforderung ZV für BT";
CM_ SG_ 388 ZV_entriegeln_Anf "Bei ZV Anforderung erfolgt die Entriegelung des Ladesteckers";
CM_ SG_ 388 ZV_FT_entriegeln "Entriegelungsanforderung ZV für FT";
CM_ SG_ 388 ZV_FT_verriegeln "Verriegelungsanforderung ZV für FT";
CM_ SG_ 388 ZV_HBFS_entriegeln "Entriegelungsanforderung ZV für HBFS
";
CM_ SG_ 388 ZV_HBFS_verriegeln "Verriegelungsanforderung ZV für HBFS
";
CM_ SG_ 388 ZV_HFS_entriegeln "Entriegelungsanforderung ZV für HFS
";
CM_ SG_ 388 ZV_HFS_verriegeln "Verriegelungsanforderung ZV für HFS
";
CM_ SG_ 388 ZV_HSK_entriegeln "Anforderungssignal zur Ansteuerung des Handschuhkastenmotors in Richtung Entriegeln. ";
CM_ SG_ 388 ZV_HSK_verriegeln "Anforderungssignal zur Ansteuerung des Handschuhkastenmotors in Richtung Verriegeln. ";
CM_ SG_ 388 ZV_LED_Steuerung "Ansteuerung der LED's in den Tueren; BAF gilt nicht für dieses Bit";
CM_ SG_ 388 ZV_LED_Uebernahme "Uebernahme der LED Steuerung durch das TSG FT";
CM_ SG_ 388 ZV_Signatur "Signatur der ZV";
CM_ SG_ 388 ZV_Softtouch_betaetigt "Betätigung Softtouch";
CM_ SG_ 388 ZV_Spg_Anklappen "Anforderung über ZV: Spiegel sind anzuklappen";
CM_ SG_ 388 ZV_Verdeck_auf "Anforderungssignal für ein Komfortöffnen des Verdecks. 
Signal wird angefordert wenn  SKontakt = 0 und eine Doppelbetätigung Schließzylinder_auf oder Funkfernbedienung_Taste_auf  innerhalb zwei Sekunden empfangen wird. Signal wird auch angefordert wenn S";
CM_ SG_ 388 ZV_Verdeck_zu "Anforderungssignal für ein Komfortschließen des Verdecks. 
Signal wird angefordert wenn  SKontakt = 0 und eine Doppelbetätigung Schließzylinder_Zu oder Funkfernbedienung_Taste_zu  innerhalb zwei Sekunden empfangen wird. Signal wird auch angefordert wenn ";
CM_ SG_ 388 ZV_zentral_entsafen "Zentral entsafen";
CM_ SG_ 388 ZV_zentral_safen "Zentral safen";
CM_ SG_ 388 ZV_zu_BT "ZV Schliessstelle";
CM_ SG_ 388 ZV_zu_FT "ZV Schliessstelle";
CM_ SG_ 388 ZV_zu_Funk "ZV Schliessstelle";
CM_ SG_ 388 ZV_zu_Kessy "ZV Schliessstelle";
CM_ SG_ 388 ZV_zu_Zeitl_Nachverr "ZV Schliessstelle";

CM_ SG_ 1411 BCM_FH_Freigabe "Funktionsfreigabe Fensterheber";
CM_ SG_ 1411 BCM_HSK_Freigabe "Handschuhkastenfreigabe";
CM_ SG_ 1411 BCM_Komfortfkt_Freigabe "globale Freigabe der Komfortfunktion";
CM_ SG_ 1411 BCM_Tankklappensteller_Fehler "Fehler: nicht Funktionalität des Tankklappenstellers";
CM_ SG_ 1411 BCM_Verdeck_Freigabe "Freigabe Verdeckbetrieb
";
CM_ SG_ 1411 DWA_aktiv "Status DWA  aktiv";
CM_ SG_ 1411 FBS_Warn_Schluessel_Batt "Kombi Prio Warnung Schluessel Batterie
'Bitte Schlüsselbatterie wechseln!'";
CM_ SG_ 1411 FFB_CarFinder "Car Finder Funktion (Blinken ohne zu entriegeln)";
CM_ SG_ 1411 FFB_Komfortoeffnen "Komfortoeffnen Funk
";
CM_ SG_ 1411 FFB_Komfortschliessen "Komfortschliessen Funk
";
CM_ SG_ 1411 HBFS_gesafet "HBFS Tuer gesafet.
Im Zustand Safe wird auch das Signal HBFS_verriegelt = 1 gesendet.";
CM_ SG_ 1411 HBFS_verriegelt "Verriegelungsstatus Tür";
CM_ SG_ 1411 HD_Hauptraste "SBL-Schloss (MQB/MLBevo): Drehfalle Heckdeckel
sonst (MQB): Hauptraste Heckdeckel";
CM_ SG_ 1411 HD_Vorraste "SBL_Schloss (MQB/MLBevo): Sperrklinke Heckdeckel
sonst (MQB): Vorraste Heckdeckel";
CM_ SG_ 1411 HFS_gesafet "HFS Tuer gesafet.
Im Zustand Safe wird auch das Signal HFS_verriegelt = 1 gesendet.";
CM_ SG_ 1411 HFS_verriegelt "HFS Tuer verriegelt";
CM_ SG_ 1411 IRUE_aktiv "Status Innenraumüberwachung
";
CM_ SG_ 1411 IRUE_Taster_Fkts_LED "Anforderung Funktions-LED IRUE-Taster (LED wird vom TSG angesteuert)
MQB: Bei Verbau eines einzelnen Taster zur Deaktivierung von IRUE und NGS wird dieses Signal zur Ansteuerung der Funktions-LED gesendet.";
CM_ SG_ 1411 ZV_BT_offen "gespiegeltes Bit BT_Tuer_geoeffnet TSG_BT_1 Botschaft";
CM_ SG_ 1411 ZV_Einzeltuerentriegelung "Einzeltürentriegelung ZV
";
CM_ SG_ 1411 ZV_FT_offen "gespiegeltes Bit FT_Tuer_geoeffnet TSG_FT_1 Botschaft";
CM_ SG_ 1411 ZV_gesafet_extern_ist "Istzustand: Fahrzeug aussen gesafet
";
CM_ SG_ 1411 ZV_gesafet_extern_soll "Sollzustand: Fahrzeug gesafet extern
";
CM_ SG_ 1411 ZV_HBFS_offen "gespiegeltes Bit HBFS_Tuer_geoeffnet TSG_HBFS_1 Botschaft";
CM_ SG_ 1411 ZV_HD_offen "Status Heckdeckel
";
CM_ SG_ 1411 ZV_Heckeinzelentriegelung "Heckdeckeleinzelentriegelung";
CM_ SG_ 1411 ZV_HFS_offen "gespiegeltes Bit HFS_Tuer_geoeffnet TSG_HFS_1 Botschaft";
CM_ SG_ 1411 ZV_HS_offen "Status Heckscheibe
";
CM_ SG_ 1411 ZV_ist_Zustand_verfuegbar "Verfügbarkeit IST-Zustand ZV

";
CM_ SG_ 1411 ZV_Oeffnungsmodus "Konfigurierter Oeffnungsmodus fuer ZV:
0 = globale Oeffnung (alle Tueren)
1 = ZV mit Einzeltuerentriegelung (FFB - nur Fahrertuer, Kessy - nur bediente Tuer)
2 = ZV individuell selektive Oeffnung (FFB - Fahrerseite, Kessy - bediente Tuer + Fahrertuer)";
CM_ SG_ 1411 ZV_Rollo_auf "Komfortöffnen des Dachrollos";
CM_ SG_ 1411 ZV_Rollo_zu "Komfortschließen des Dachrollos";
CM_ SG_ 1411 ZV_SAD_auf "Komfortöffnen des Schiebeausstelldaches";
CM_ SG_ 1411 ZV_SAD_zu "Komfortschließen des Schiebeausstelldaches";
CM_ SG_ 1411 ZV_SafeFunktion_aktiv "Statusübermittlung ob die Safe Funktion im Fzg. aktiv ist. Das Kombi benötigt das Signal, um den Text Safelock aktiv anzuzeigen. ";
CM_ SG_ 1411 ZV_Schluessel_Zugang "aktuelle Funkschlüsselnummer";
CM_ SG_ 1411 ZV_Tankklappe_offen "Öffnungsstatus der Tankklappe";
CM_ SG_ 1411 ZV_verriegelt_extern_ist "Istzustand: Verriegelung Fahrzeug aussen
";
CM_ SG_ 1411 ZV_verriegelt_extern_soll "Sollzustand: Verriegelung Fahrzeug aussen
";
CM_ SG_ 1411 ZV_verriegelt_intern_ist "Istzustand: Verriegelung Fahrzeug innen
";
CM_ SG_ 1411 ZV_verriegelt_intern_soll "Sollzustand: Verriegelung Fahrzeug innen
";
CM_ SG_ 1411 ZV_verriegelt_soll "Fahrzeug Gesamtverriegelungsstatus Sollzustand für Ladestecker- und Ladeklappenverriegelung. ";

CM_ SG_ 711 BCM2_ZV_Tasten_HMI_Anf "Trigger zum Einschalten des Touchbediendisplays und Anzeigen der ZV Tasten";
CM_ SG_ 711 BCM_Spg_Heizen_Trigger "Anforderung Spiegelheizung";
CM_ SG_ 711 ZV_FD_Taste_auf "Taster zum Öffnen der Frontklappe über BAP";
CM_ SG_ 711 ZV_HD_Taste_auf "Taster zum Öffnen der Heckklappe über BAP";
CM_ SG_ 711 ZV_HD_Taste_zu "Taster zum Schliessen der Heckklappe über BAP";
CM_ SG_ 711 ZV_TAG_verfahren "TAG Aus- oder Einfahren";
BA_DEF_ BO_  "DiagRequest" ENUM "No", "Yes";
BA_DEF_ BO_  "DiagResponse" ENUM "No", "Yes";
BA_DEF_ BO_  "DiagState" ENUM "No", "Yes";
BA_DEF_ BO_  "GenMsgChkConstant" HEX 0 4095;
BA_DEF_ BO_  "GenMsgCycleTime" INT 0 65535;
BA_DEF_ BO_  "GenMsgCycleTimeFast" INT 0 65535;
BA_DEF_ BO_  "GenMsgDelayTime" INT 0 100000;
BA_DEF_ BO_  "GenMsgILSupport" ENUM "No", "Yes";
BA_DEF_ BO_  "GenMsgNrOfRepetition" INT 0 100;
BA_DEF_ BO_  "GenMsgPDUConstants" STRING;
BA_DEF_ BO_  "GenMsgSendType" ENUM "Cyclic", "not_used", "not_used", "not_used", "not_used", "not_used", "not_used", "IfActive", "NoMsgSendType";
BA_DEF_ BO_  "GenMsgStartDelayTime" INT 0 100000;
BA_DEF_ BO_  "NmMessage" ENUM "No", "Yes";
BA_DEF_ BO_  "NmhMessage" ENUM "No", "Yes";
BA_DEF_ BO_  "MsgType" ENUM "Application", "NM ", "NMH", "TP2.0", "ISO-TP ", "BAP", "EID", "KS", "XCP_PRE_CONFIGURED", "XCP_RUNTIME_CONFIGURED";
BA_DEF_ BO_  "VAGTP20_API" HEX 0 255;
BA_DEF_ BO_  "VAGTP20_DynConnection" ENUM "No", "Yes";
BA_DEF_ BO_  "VAGTP20_DynSetup" ENUM "No", "Yes";
BA_DEF_ BO_  "VAGTP20_StatConnection" ENUM "No", "Yes";
BA_DEF_ SG_  "GenSigActiveRepetitions" INT -2147483648 2147483647;
BA_DEF_ SG_  "GenSigInactiveValue" INT -2147483648 2147483647;
BA_DEF_ SG_  "GenSigSendType" ENUM "Cyclic", "OnWrite", "OnWriteWithRepetition", "OnChange", "OnChangeWithRepetition", "IfActive", "IfActiveWithRepetition", "NoSigSendType", "OnChangeAndIfActive", "OnChangeAndIfActiveWithRepetition";
BA_DEF_ SG_  "GenSigStartValue" INT -2147483648 2147483647;
BA_DEF_ SG_  "NWM-WakeupAllowed" ENUM "No", "Yes";
BA_DEF_ SG_  "GenSigFuncType" ENUM "NoFunction", "MsgCounter", "CRC-8", "XOR", "XOR-2", "DatedBit", "SW-Kl15", "CHK", "Constant", "Protocol", "CRC-8-SAE_J1850", "CRC-32", "DataLength", "DataID", "MsgCounter16", "SOK-Signatur", "Cluster";
BA_DEF_ SG_  "GenSigSwitchedByIgnition" ENUM "No", "Yes";
BA_DEF_ SG_  "Fehlerwert" HEX 0 2147483647;
BA_DEF_ SG_  "GenSigMissingSourceValue" HEX 0 2147483647;
BA_DEF_DEF_  "DiagRequest" "No";
BA_DEF_DEF_  "DiagResponse" "No";
BA_DEF_DEF_  "DiagState" "No";
BA_DEF_DEF_  "GenMsgChkConstant" 0;
BA_DEF_DEF_  "GenMsgCycleTime" 0;
BA_DEF_DEF_  "GenMsgCycleTimeFast" 0;
BA_DEF_DEF_  "GenMsgDelayTime" 0;
BA_DEF_DEF_  "GenMsgILSupport" "No";
BA_DEF_DEF_  "GenMsgNrOfRepetition" 0;
BA_DEF_DEF_  "GenMsgPDUConstants" "";
BA_DEF_DEF_  "GenMsgSendType" "NoMsgSendType";
BA_DEF_DEF_  "GenMsgStartDelayTime" 0;
BA_DEF_DEF_  "NmMessage" "No";
BA_DEF_DEF_  "NmhMessage" "No";
BA_DEF_DEF_  "MsgType" "Application";
BA_DEF_DEF_  "VAGTP20_API" 0;
BA_DEF_DEF_  "VAGTP20_DynConnection" "No";
BA_DEF_DEF_  "VAGTP20_DynSetup" "No";
BA_DEF_DEF_  "VAGTP20_StatConnection" "No";
BA_DEF_DEF_  "GenSigActiveRepetitions" 0;
BA_DEF_DEF_  "GenSigInactiveValue" 0;
BA_DEF_DEF_  "GenSigSendType" "NoSigSendType";
BA_DEF_DEF_  "GenSigStartValue" 0;
BA_DEF_DEF_  "NWM-WakeupAllowed" "No";
BA_DEF_DEF_  "GenSigFuncType" "NoFunction";
BA_DEF_DEF_  "GenSigSwitchedByIgnition" "Yes";
BA_DEF_DEF_  "Fehlerwert" 0;
BA_DEF_DEF_  "GenSigMissingSourceValue" 0;
BA_ "DiagResponse" BO_ 2550034644 1;
BA_ "MsgType" BO_ 2550034644 4;
BA_ "DiagRequest" BO_ 2549903573 1;
BA_ "MsgType" BO_ 2549903573 4;
BA_ "DiagResponse" BO_ 2550034645 1;
BA_ "MsgType" BO_ 2550034645 4;
BA_ "DiagRequest" BO_ 2549903574 1;
BA_ "MsgType" BO_ 2549903574 4;
BA_ "DiagResponse" BO_ 2550034646 1;
BA_ "MsgType" BO_ 2550034646 4;
BA_ "DiagRequest" BO_ 2549903575 1;
BA_ "MsgType" BO_ 2549903575 4;
BA_ "DiagResponse" BO_ 2550034647 1;
BA_ "MsgType" BO_ 2550034647 4;
BA_ "DiagRequest" BO_ 2549903576 1;
BA_ "MsgType" BO_ 2549903576 4;
BA_ "DiagResponse" BO_ 2550034648 1;
BA_ "MsgType" BO_ 2550034648 4;
BA_ "DiagRequest" BO_ 2549903577 1;
BA_ "MsgType" BO_ 2549903577 4;
BA_ "DiagResponse" BO_ 2550034649 1;
BA_ "MsgType" BO_ 2550034649 4;
BA_ "DiagRequest" BO_ 2549903578 1;
BA_ "MsgType" BO_ 2549903578 4;
BA_ "DiagResponse" BO_ 2550034650 1;
BA_ "MsgType" BO_ 2550034650 4;
BA_ "DiagRequest" BO_ 2549903579 1;
BA_ "MsgType" BO_ 2549903579 4;
BA_ "DiagResponse" BO_ 2550034651 1;
BA_ "MsgType" BO_ 2550034651 4;
BA_ "DiagRequest" BO_ 2549903580 1;
BA_ "MsgType" BO_ 2549903580 4;
BA_ "DiagResponse" BO_ 2550034652 1;
BA_ "MsgType" BO_ 2550034652 4;
BA_ "DiagRequest" BO_ 2549903601 1;
BA_ "MsgType" BO_ 2549903601 4;
BA_ "DiagResponse" BO_ 2550034673 1;
BA_ "MsgType" BO_ 2550034673 4;
BA_ "DiagRequest" BO_ 2549903602 1;
BA_ "MsgType" BO_ 2549903602 4;
BA_ "DiagResponse" BO_ 2550034674 1;
BA_ "MsgType" BO_ 2550034674 4;
BA_ "DiagRequest" BO_ 2549903603 1;
BA_ "MsgType" BO_ 2549903603 4;
BA_ "DiagResponse" BO_ 2550034675 1;
BA_ "MsgType" BO_ 2550034675 4;
BA_ "DiagRequest" BO_ 2549875380 1;
BA_ "MsgType" BO_ 2549875380 4;
BA_ "DiagResponse" BO_ 2550006452 1;
BA_ "MsgType" BO_ 2550006452 4;
BA_ "DiagRequest" BO_ 2549875266 1;
BA_ "MsgType" BO_ 2549875266 4;
BA_ "DiagResponse" BO_ 2550006338 1;
BA_ "MsgType" BO_ 2550006338 4;
BA_ "GenMsgCycleTime" BO_ 2589283656 960;
BA_ "GenMsgDelayTime" BO_ 2589283656 160;
BA_ "GenMsgILSupport" BO_ 2589283656 1;
BA_ "GenMsgPDUConstants" BO_ 2589283656 "0xee,0xcc,0x2f,0x27,0x93,0x0c,0x45,0x97,0x87,0x2e,0xec,0x3b,0xd3,0x35,0xcb,0x4a";
BA_ "GenMsgSendType" BO_ 2589283656 0;
BA_ "GenMsgStartDelayTime" BO_ 2589283656 160;
BA_ "GenMsgCycleTime" BO_ 872 1000;
BA_ "GenMsgDelayTime" BO_ 872 40;
BA_ "GenMsgILSupport" BO_ 872 1;
BA_ "GenMsgSendType" BO_ 872 0;
BA_ "GenMsgCycleTime" BO_ 2463978617 500;
BA_ "GenMsgDelayTime" BO_ 2463978617 40;
BA_ "GenMsgILSupport" BO_ 2463978617 1;
BA_ "GenMsgSendType" BO_ 2463978617 0;
BA_ "GenMsgCycleTime" BO_ 1175 1000;
BA_ "GenMsgDelayTime" BO_ 1175 50;
BA_ "GenMsgILSupport" BO_ 1175 1;
BA_ "GenMsgSendType" BO_ 1175 0;
BA_ "GenMsgCycleTime" BO_ 1355 500;
BA_ "GenMsgDelayTime" BO_ 1355 20;
BA_ "GenMsgILSupport" BO_ 1355 1;
BA_ "GenMsgSendType" BO_ 1355 0;
BA_ "GenMsgCycleTime" BO_ 617 80;
BA_ "GenMsgILSupport" BO_ 617 1;
BA_ "GenMsgSendType" BO_ 617 0;
BA_ "MsgType" BO_ 2549876804 4;
BA_ "MsgType" BO_ 2550007876 4;
BA_ "GenMsgCycleTime" BO_ 2527679715 1000;
BA_ "GenMsgDelayTime" BO_ 2527679715 200;
BA_ "GenMsgILSupport" BO_ 2527679715 1;
BA_ "GenMsgSendType" BO_ 2527679715 0;
BA_ "GenMsgCycleTime" BO_ 1616 1000;
BA_ "GenMsgDelayTime" BO_ 1616 50;
BA_ "GenMsgILSupport" BO_ 1616 1;
BA_ "GenMsgSendType" BO_ 1616 0;
BA_ "GenMsgCycleTime" BO_ 1525 500;
BA_ "GenMsgILSupport" BO_ 1525 1;
BA_ "GenMsgSendType" BO_ 1525 0;
BA_ "GenMsgStartDelayTime" BO_ 1525 85;
BA_ "GenMsgCycleTime" BO_ 1527 500;
BA_ "GenMsgDelayTime" BO_ 1527 100;
BA_ "GenMsgILSupport" BO_ 1527 1;
BA_ "GenMsgSendType" BO_ 1527 0;
BA_ "GenMsgStartDelayTime" BO_ 1527 85;
BA_ "GenMsgCycleTime" BO_ 2463978658 100;
BA_ "GenMsgDelayTime" BO_ 2463978658 10;
BA_ "GenMsgILSupport" BO_ 2463978658 1;
BA_ "GenMsgSendType" BO_ 2463978658 0;
BA_ "GenMsgCycleTime" BO_ 1126 500;
BA_ "GenMsgDelayTime" BO_ 1126 100;
BA_ "GenMsgILSupport" BO_ 1126 1;
BA_ "GenMsgSendType" BO_ 1126 0;
BA_ "GenMsgStartDelayTime" BO_ 1126 160;
BA_ "GenMsgCycleTime" BO_ 2527679790 500;
BA_ "GenMsgILSupport" BO_ 2527679790 1;
BA_ "GenMsgSendType" BO_ 2527679790 0;
BA_ "GenMsgCycleTime" BO_ 2527679791 500;
BA_ "GenMsgILSupport" BO_ 2527679791 1;
BA_ "GenMsgSendType" BO_ 2527679791 0;
BA_ "GenMsgCycleTime" BO_ 2527679792 500;
BA_ "GenMsgDelayTime" BO_ 2527679792 50;
BA_ "GenMsgILSupport" BO_ 2527679792 1;
BA_ "GenMsgSendType" BO_ 2527679792 0;
BA_ "GenMsgCycleTime" BO_ 424 20;
BA_ "GenMsgILSupport" BO_ 424 1;
BA_ "GenMsgPDUConstants" BO_ 424 "0x11,0x17,0xbb,0xaa,0xd0,0x83,0xe1,0x8e,0xa3,0x4d,0xef,0x50,0x88,0xa5,0x22,0xf6";
BA_ "GenMsgSendType" BO_ 424 0;
BA_ "GenMsgCycleTime" BO_ 1313 200;
BA_ "GenMsgILSupport" BO_ 1313 1;
BA_ "GenMsgSendType" BO_ 1313 0;
BA_ "GenMsgCycleTime" BO_ 505 500;
BA_ "GenMsgILSupport" BO_ 505 1;
BA_ "GenMsgPDUConstants" BO_ 505 "0x14,0xf8,0xf6,0x94,0x2a,0x12,0x39,0x3d,0x98,0x3f,0xfb,0x9d,0x36,0xca,0x1d,0xe0";
BA_ "GenMsgSendType" BO_ 505 0;
BA_ "GenMsgCycleTime" BO_ 1413 1000;
BA_ "GenMsgDelayTime" BO_ 1413 10;
BA_ "GenMsgILSupport" BO_ 1413 1;
BA_ "GenMsgSendType" BO_ 1413 0;
BA_ "GenMsgStartDelayTime" BO_ 1413 85;
BA_ "GenMsgCycleTime" BO_ 1001 100;
BA_ "GenMsgILSupport" BO_ 1001 1;
BA_ "GenMsgSendType" BO_ 1001 0;
BA_ "GenMsgCycleTime" BO_ 1015 100;
BA_ "GenMsgILSupport" BO_ 1015 1;
BA_ "GenMsgSendType" BO_ 1015 0;
BA_ "GenMsgCycleTime" BO_ 1017 200;
BA_ "GenMsgILSupport" BO_ 1017 1;
BA_ "GenMsgSendType" BO_ 1017 0;
BA_ "GenMsgCycleTime" BO_ 1399 320;
BA_ "GenMsgILSupport" BO_ 1399 1;
BA_ "GenMsgSendType" BO_ 1399 0;
BA_ "GenMsgCycleTime" BO_ 1375 500;
BA_ "GenMsgDelayTime" BO_ 1375 20;
BA_ "GenMsgILSupport" BO_ 1375 1;
BA_ "GenMsgSendType" BO_ 1375 0;
BA_ "GenMsgCycleTime" BO_ 1373 500;
BA_ "GenMsgDelayTime" BO_ 1373 200;
BA_ "GenMsgILSupport" BO_ 1373 1;
BA_ "GenMsgSendType" BO_ 1373 0;
BA_ "GenMsgCycleTime" BO_ 1657 500;
BA_ "GenMsgILSupport" BO_ 1657 1;
BA_ "GenMsgSendType" BO_ 1657 0;
BA_ "GenMsgCycleTime" BO_ 2463978655 100;
BA_ "GenMsgILSupport" BO_ 2463978655 1;
BA_ "GenMsgSendType" BO_ 2463978655 0;
BA_ "GenMsgCycleTime" BO_ 2589283463 500;
BA_ "GenMsgILSupport" BO_ 2589283463 1;
BA_ "GenMsgSendType" BO_ 2589283463 0;
BA_ "GenMsgCycleTime" BO_ 2463978827 100;
BA_ "GenMsgILSupport" BO_ 2463978827 1;
BA_ "GenMsgSendType" BO_ 2463978827 0;
BA_ "GenMsgCycleTime" BO_ 2463978828 100;
BA_ "GenMsgILSupport" BO_ 2463978828 1;
BA_ "GenMsgSendType" BO_ 2463978828 0;
BA_ "GenMsgCycleTime" BO_ 2463978829 100;
BA_ "GenMsgILSupport" BO_ 2463978829 1;
BA_ "GenMsgSendType" BO_ 2463978829 0;
BA_ "GenMsgCycleTime" BO_ 2589283464 500;
BA_ "GenMsgILSupport" BO_ 2589283464 1;
BA_ "GenMsgSendType" BO_ 2589283464 0;
BA_ "GenMsgCycleTime" BO_ 2589283408 500;
BA_ "GenMsgILSupport" BO_ 2589283408 1;
BA_ "GenMsgSendType" BO_ 2589283408 0;
BA_ "GenMsgCycleTime" BO_ 2527679716 200;
BA_ "GenMsgILSupport" BO_ 2527679716 1;
BA_ "GenMsgSendType" BO_ 2527679716 0;
BA_ "GenMsgCycleTime" BO_ 2527679717 200;
BA_ "GenMsgILSupport" BO_ 2527679717 1;
BA_ "GenMsgSendType" BO_ 2527679717 0;
BA_ "GenMsgCycleTime" BO_ 2527679718 200;
BA_ "GenMsgILSupport" BO_ 2527679718 1;
BA_ "GenMsgSendType" BO_ 2527679718 0;
BA_ "GenMsgCycleTime" BO_ 2463978733 100;
BA_ "GenMsgILSupport" BO_ 2463978733 1;
BA_ "GenMsgSendType" BO_ 2463978733 0;
BA_ "GenMsgCycleTime" BO_ 977 100;
BA_ "GenMsgDelayTime" BO_ 977 20;
BA_ "GenMsgILSupport" BO_ 977 1;
BA_ "GenMsgSendType" BO_ 977 0;
BA_ "GenMsgCycleTime" BO_ 976 100;
BA_ "GenMsgDelayTime" BO_ 976 20;
BA_ "GenMsgILSupport" BO_ 976 1;
BA_ "GenMsgSendType" BO_ 976 0;
BA_ "GenMsgCycleTime" BO_ 975 100;
BA_ "GenMsgDelayTime" BO_ 975 20;
BA_ "GenMsgILSupport" BO_ 975 1;
BA_ "GenMsgSendType" BO_ 975 0;
BA_ "GenMsgCycleTime" BO_ 974 100;
BA_ "GenMsgDelayTime" BO_ 974 20;
BA_ "GenMsgILSupport" BO_ 974 1;
BA_ "GenMsgSendType" BO_ 974 0;
BA_ "GenMsgCycleTime" BO_ 995 100;
BA_ "GenMsgCycleTimeFast" BO_ 995 50;
BA_ "GenMsgDelayTime" BO_ 995 50;
BA_ "GenMsgILSupport" BO_ 995 1;
BA_ "GenMsgNrOfRepetition" BO_ 995 5;
BA_ "GenMsgPDUConstants" BO_ 995 "0xad,0x1d,0xac,0x8e,0x6e,0x58,0x71,0x3b,0xce,0xc6,0x27,0x4f,0x06,0xca,0x65,0x84";
BA_ "GenMsgSendType" BO_ 995 0;
BA_ "GenMsgCycleTime" BO_ 1716 200;
BA_ "GenMsgILSupport" BO_ 1716 1;
BA_ "GenMsgSendType" BO_ 1716 0;
BA_ "GenMsgCycleTime" BO_ 916 160;
BA_ "GenMsgDelayTime" BO_ 916 10;
BA_ "GenMsgILSupport" BO_ 916 1;
BA_ "GenMsgPDUConstants" BO_ 916 "0x47,0x94,0x92,0x6a,0x67,0xb5,0x0d,0x38,0xe3,0x8a,0x5d,0xb4,0x54,0xab,0xae,0x27";
BA_ "GenMsgSendType" BO_ 916 0;
BA_ "GenMsgCycleTime" BO_ 1702 500;
BA_ "GenMsgCycleTimeFast" BO_ 1702 100;
BA_ "GenMsgDelayTime" BO_ 1702 50;
BA_ "GenMsgILSupport" BO_ 1702 1;
BA_ "GenMsgNrOfRepetition" BO_ 1702 3;
BA_ "GenMsgSendType" BO_ 1702 0;
BA_ "MsgType" BO_ 2617079552 6;
BA_ "MsgType" BO_ 2617079553 6;
BA_ "MsgType" BO_ 2566705152 6;
BA_ "MsgType" BO_ 2566705153 6;
BA_ "MsgType" BO_ 2617042688 6;
BA_ "MsgType" BO_ 2617042689 6;
BA_ "MsgType" BO_ 2617118208 6;
BA_ "MsgType" BO_ 2617118209 6;
BA_ "MsgType" BO_ 2617097984 6;
BA_ "MsgType" BO_ 2617097985 6;
BA_ "MsgType" BO_ 2617093888 6;
BA_ "MsgType" BO_ 2617093889 6;
BA_ "MsgType" BO_ 2617120256 8;
BA_ "MsgType" BO_ 2617120257 9;
BA_ "GenMsgCycleTime" BO_ 1140 1000;
BA_ "GenMsgDelayTime" BO_ 1140 40;
BA_ "GenMsgILSupport" BO_ 1140 1;
BA_ "GenMsgSendType" BO_ 1140 0;
BA_ "GenMsgCycleTime" BO_ 2527679655 1000;
BA_ "GenMsgDelayTime" BO_ 2527679655 50;
BA_ "GenMsgILSupport" BO_ 2527679655 1;
BA_ "GenMsgSendType" BO_ 2527679655 0;
BA_ "GenMsgCycleTime" BO_ 388 1000;
BA_ "GenMsgCycleTimeFast" BO_ 388 20;
BA_ "GenMsgILSupport" BO_ 388 1;
BA_ "GenMsgNrOfRepetition" BO_ 388 11;
BA_ "GenMsgPDUConstants" BO_ 388 "0xe3,0xe8,0xc4,0x7f,0xf1,0x95,0xd8,0xb0,0xc7,0xa3,0xf4,0x6c,0xe7,0xc3,0x5a,0xf7";
BA_ "GenMsgSendType" BO_ 388 0;
BA_ "GenMsgCycleTime" BO_ 1411 200;
BA_ "GenMsgCycleTimeFast" BO_ 1411 50;
BA_ "GenMsgDelayTime" BO_ 1411 50;
BA_ "GenMsgILSupport" BO_ 1411 1;
BA_ "GenMsgNrOfRepetition" BO_ 1411 5;
BA_ "GenMsgSendType" BO_ 1411 0;
BA_ "GenMsgCycleTime" BO_ 711 1000;
BA_ "GenMsgCycleTimeFast" BO_ 711 20;
BA_ "GenMsgILSupport" BO_ 711 1;
BA_ "GenMsgNrOfRepetition" BO_ 711 11;
BA_ "GenMsgSendType" BO_ 711 0;
